VERSION "created by canmatrix"

NS_ :

BS_:

BU_: BDC_Body CHC DME1 EME FLA NiVi ZGW Kombi Kombi_Basis Diagnosetool_FA_CAN CDC_ZGW DME2 ELV Gliwa_T1_Host FA_CAN_Dummy

BO_ 841 RAW_DATA_TANK: 5 BDC_Body
 SG_ RWDT_SEN_FLLV_FUTA_L : 0|16@1+ (0.1,0) [0|120.7] "Ohm" Kombi,Kombi_Basis
 SG_ RWDT_SEN_FLLV_FUTA_R : 16|16@1+ (0.1,0) [0|120.7] "Ohm" Kombi,Kombi_Basis

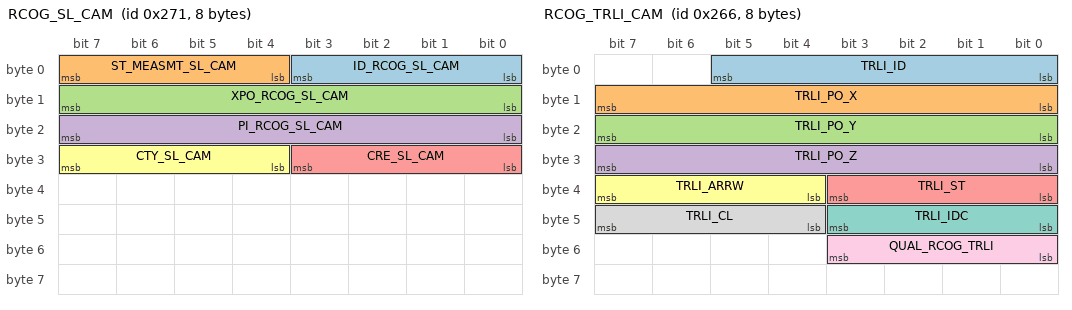
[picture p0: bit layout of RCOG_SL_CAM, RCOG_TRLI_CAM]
BO_ 625 RCOG_SL_CAM: 8 ZGW
 SG_ ID_RCOG_SL_CAM : 0|4@1+ (1,0) [0|12] "This unit fulfills the required AUTOSAR reference to a unit. No real unit is defined." DME2,DME1
 SG_ ST_MEASMT_SL_CAM : 4|4@1+ (1,0) [0|15] "" DME2,DME1
 SG_ XPO_RCOG_SL_CAM : 8|8@1+ (0.25,0) [0.00|15.75] "m" DME2,DME1
 SG_ PI_RCOG_SL_CAM : 16|8@1+ (0.01247,0) [0.00000|0.0391862268] "rad" DME2,DME1
 SG_ CRE_SL_CAM : 24|4@1+ (1,0) [0|10] "This unit fulfills the required AUTOSAR reference to a unit. No real unit is defined." DME2,DME1
 SG_ CTY_SL_CAM : 28|4@1+ (1,0) [0|15] "" DME2,DME1

BO_ 614 RCOG_TRLI_CAM: 8 ZGW
 SG_ TRLI_ID : 0|6@1+ (1,0) [0|60] "This unit fulfills the required AUTOSAR reference to a unit. No real unit is defined." DME2,DME1
 SG_ TRLI_PO_X : 8|8@1+ (0.5,0) [0|63] "m" DME2,DME1
 SG_ TRLI_PO_Y : 16|8@1+ (0.3,-37.8) [-49.14|-26.46] "m" DME2,DME1
 SG_ TRLI_PO_Z : 24|8@1+ (0.1,0) [0|2.52] "m" DME2,DME1
 SG_ TRLI_ST : 32|4@1+ (1,0) [0|15] "" DME2,DME1
 SG_ TRLI_ARRW : 36|4@1+ (1,0) [0|15] "" DME2,DME1
 SG_ TRLI_IDC : 40|4@1+ (1,0) [0|15] "" DME2,DME1
 SG_ TRLI_CL : 44|4@1+ (1,0) [0|15] "" DME2,DME1
 SG_ QUAL_RCOG_TRLI : 48|4@1+ (10,0) [0|1000] "%" DME2,DME1

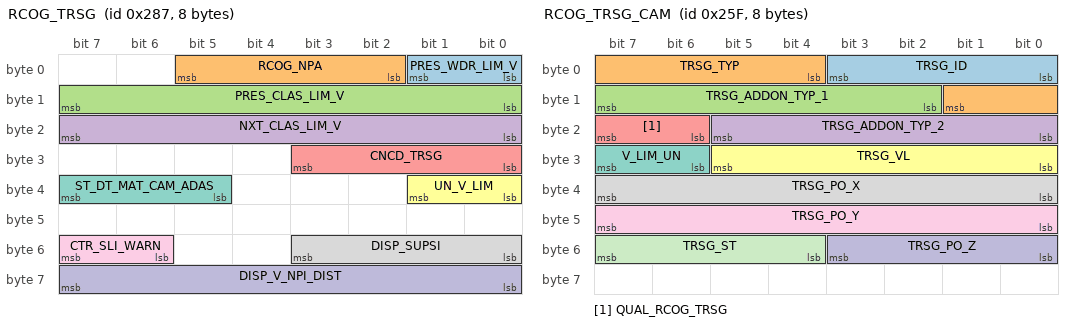
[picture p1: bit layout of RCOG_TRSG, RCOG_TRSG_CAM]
BO_ 647 RCOG_TRSG: 8 ZGW
 SG_ PRES_WDR_LIM_V : 0|2@1+ (1,0) [0|3] "" Kombi,Kombi_Basis,EME
 SG_ RCOG_NPA : 2|4@1+ (1,0) [0|15] "" Kombi,Kombi_Basis
 SG_ PRES_CLAS_LIM_V : 8|8@1+ (1,0) [0|255] "" Kombi,Kombi_Basis,EME
 SG_ NXT_CLAS_LIM_V : 16|8@1+ (1,0) [0|255] "" Kombi
 SG_ CNCD_TRSG : 24|4@1+ (1,0) [0|15] "" Kombi,Kombi_Basis,EME
 SG_ UN_V_LIM : 32|2@1+ (1,0) [0|3] "" Kombi,Kombi_Basis,EME
 SG_ ST_DT_MAT_CAM_ADAS : 37|3@1+ (1,0) [0|7] "" Kombi
 SG_ DISP_SUPSI : 48|4@1+ (1,0) [0|15] "" Kombi
 SG_ CTR_SLI_WARN : 54|2@1+ (1,0) [0|3] "" Kombi,Kombi_Basis
 SG_ DISP_V_NPI_DIST : 56|8@1+ (10,0) [0|25200] "This unit fulfills the required AUTOSAR reference to a unit. No real unit is defined." Kombi

BO_ 607 RCOG_TRSG_CAM: 8 ZGW
 SG_ TRSG_ID : 0|4@1+ (1,0) [0|12] "This unit fulfills the required AUTOSAR reference to a unit. No real unit is defined." DME2,DME1
 SG_ TRSG_TYP : 4|6@1+ (1,0) [0|63] "" DME2,DME1
 SG_ TRSG_ADDON_TYP_1 : 10|6@1+ (1,0) [0|63] "" DME2,DME1
 SG_ TRSG_ADDON_TYP_2 : 16|6@1+ (1,0) [0|63] "" DME2,DME1
 SG_ QUAL_RCOG_TRSG : 22|2@1+ (1,0) [0|3] "" DME2,DME1
 SG_ TRSG_VL : 24|6@1+ (5,0) [0|1500] "This unit fulfills the required AUTOSAR reference to a unit. No real unit is defined." DME2,DME1
 SG_ V_LIM_UN : 30|2@1+ (1,0) [0|3] "" DME2,DME1
 SG_ TRSG_PO_X : 32|8@1+ (0.5,0) [0|63] "m" DME2,DME1
 SG_ TRSG_PO_Y : 40|8@1+ (0.2,-25.2) [-30.24|-20.16] "m" DME2,DME1
 SG_ TRSG_PO_Z : 48|4@1+ (0.5,0) [0|3] "m" DME2,DME1
 SG_ TRSG_ST : 52|4@1+ (1,0) [0|15] "" DME2,DME1

BO_ 370 RCPT_RQ_KI: 5 ZGW
 SG_ RCPT_RQ_ACOU_KI : 32|4@1+ (1,0) [0|15] "" Kombi,Kombi_Basis

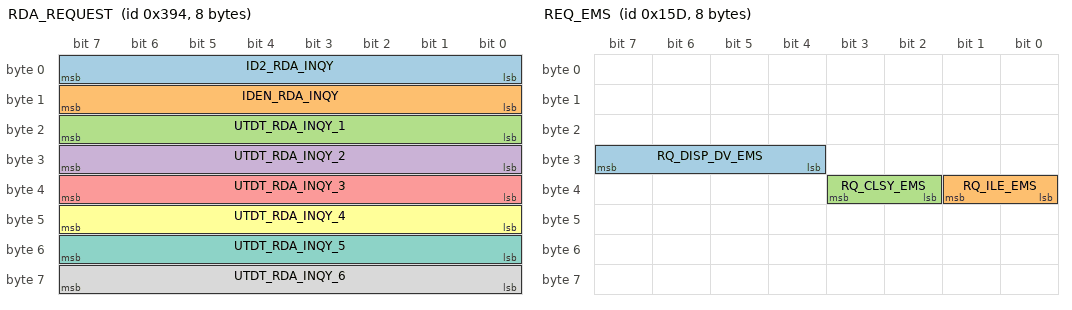
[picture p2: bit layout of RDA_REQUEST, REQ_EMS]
BO_ 916 RDA_REQUEST: 8 Kombi
 SG_ ID2_RDA_INQY : 0|8@1+ (1,0) [0|255] "" BDC_Body
 SG_ IDEN_RDA_INQY : 8|8@1+ (1,0) [0|254] "This unit fulfills the required AUTOSAR reference to a unit. No real unit is defined." BDC_Body
 SG_ UTDT_RDA_INQY_1 : 16|8@1+ (1,0) [0|255] "" BDC_Body
 SG_ UTDT_RDA_INQY_2 : 24|8@1+ (1,0) [0|255] "" BDC_Body
 SG_ UTDT_RDA_INQY_3 : 32|8@1+ (1,0) [0|255] "" BDC_Body
 SG_ UTDT_RDA_INQY_4 : 40|8@1+ (1,0) [0|255] "" BDC_Body
 SG_ UTDT_RDA_INQY_5 : 48|8@1+ (1,0) [0|255] "" BDC_Body
 SG_ UTDT_RDA_INQY_6 : 56|8@1+ (1,0) [0|255] "" BDC_Body

BO_ 808 RELATIVZEIT: 6 Kombi
 SG_ T_SEC_COU_REL : 0|32@1+ (1,0) [0|4294967294] "s" BDC_Body,NiVi,FLA,ELV,EME,DME2,DME1,Kombi_Basis,CHC,ZGW,Kombi
 SG_ T_DAY_COU_ABSL : 32|16@1+ (1,0) [0|65534] "This unit fulfills the required AUTOSAR reference to a unit. No real unit is defined." BDC_Body,EME,DME2,DME1,ZGW,NiVi

BO_ 349 REQ_EMS: 8 ZGW
 SG_ RQ_DISP_DV_EMS : 28|4@1+ (1,0) [0|15] "" Kombi,Kombi_Basis
 SG_ RQ_ILE_EMS : 32|2@1+ (1,0) [0|3] "" BDC_Body
 SG_ RQ_CLSY_EMS : 34|2@1+ (1,0) [0|3] "" BDC_Body

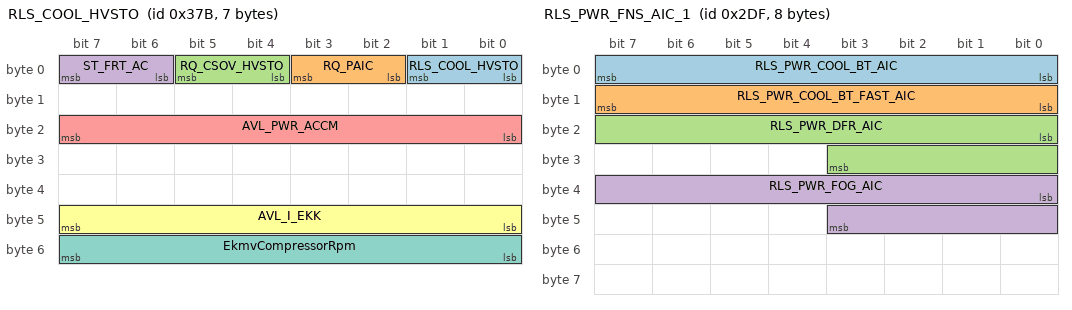
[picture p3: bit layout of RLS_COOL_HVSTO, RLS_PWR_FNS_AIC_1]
BO_ 891 RLS_COOL_HVSTO: 7 ZGW
 SG_ RLS_COOL_HVSTO : 0|2@1+ (1,0) [0|3] "" EME
 SG_ RQ_PAIC : 2|2@1+ (1,0) [0|3] "" DME2,EME,DME1
 SG_ RQ_CSOV_HVSTO : 4|2@1+ (1,0) [0|3] "" EME
 SG_ ST_FRT_AC : 6|2@1+ (1,0) [0|3] "" EME
 SG_ AVL_PWR_ACCM : 16|8@1+ (0.04,0) [0.00|0.4064] "kW" DME2,EME,DME1
 SG_ AVL_I_EKK : 40|8@1+ (0.2,0) [0|10.16] "A" CDC_ZGW,EME
 SG_ EkmvCompressorRpm : 48|8@1+ (0.5,0) [0|50] "%" EME

BO_ 735 RLS_PWR_FNS_AIC_1: 8 EME
 SG_ RLS_PWR_COOL_BT_AIC : 0|8@1+ (25,0) [0|157500] "W" ZGW
 SG_ RLS_PWR_COOL_BT_FAST_AIC : 8|8@1+ (25,0) [0|157500] "W" ZGW
 SG_ RLS_PWR_DFR_AIC : 16|12@1+ (25,0) [0|2557500] "W" ZGW
 SG_ RLS_PWR_FOG_AIC : 32|12@1+ (25,0) [0|2557500] "W" ZGW

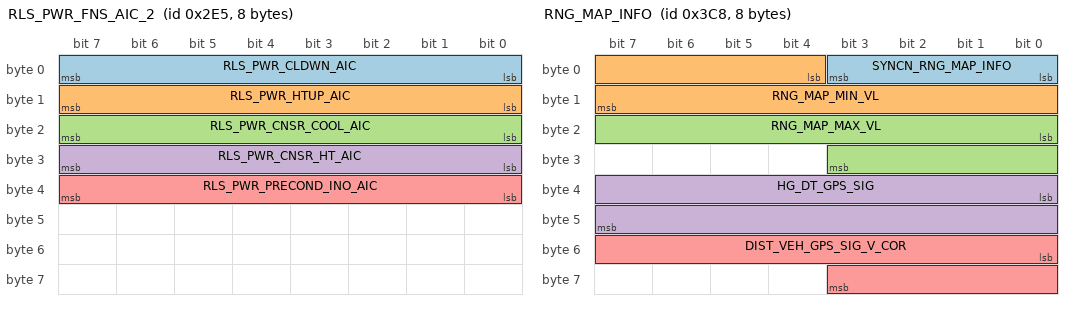
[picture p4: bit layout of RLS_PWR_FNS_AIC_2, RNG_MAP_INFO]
BO_ 741 RLS_PWR_FNS_AIC_2: 8 EME
 SG_ RLS_PWR_CLDWN_AIC : 0|8@1+ (25,0) [0|157500] "W" ZGW
 SG_ RLS_PWR_HTUP_AIC : 8|8@1+ (25,0) [0|157500] "W" ZGW
 SG_ RLS_PWR_CNSR_COOL_AIC : 16|8@1+ (25,0) [0|157500] "W" ZGW
 SG_ RLS_PWR_CNSR_HT_AIC : 24|8@1+ (25,0) [0|157500] "W" ZGW
 SG_ RLS_PWR_PRECOND_INO_AIC : 32|8@1+ (25,0) [0|157500] "W" ZGW

BO_ 968 RNG_MAP_INFO: 8 ZGW
 SG_ SYNCN_RNG_MAP_INFO : 0|4@1+ (1,0) [0|14] "This unit fulfills the required AUTOSAR reference to a unit. No real unit is defined." Kombi,Kombi_Basis
 SG_ RNG_MAP_MIN_VL : 4|12@1+ (1,0) [0|4094] "This unit fulfills the required AUTOSAR reference to a unit. No real unit is defined." Kombi,Kombi_Basis
 SG_ RNG_MAP_MAX_VL : 16|12@1+ (1,0) [0|4094] "This unit fulfills the required AUTOSAR reference to a unit. No real unit is defined." Kombi,Kombi_Basis
 SG_ HG_DT_GPS_SIG : 32|16@1+ (0.2,-1000) [-1200|1421.36] "m" Kombi,Kombi_Basis
 SG_ DIST_VEH_GPS_SIG_V_COR : 48|12@1+ (1,0) [0|4093] "m" Kombi,Kombi_Basis

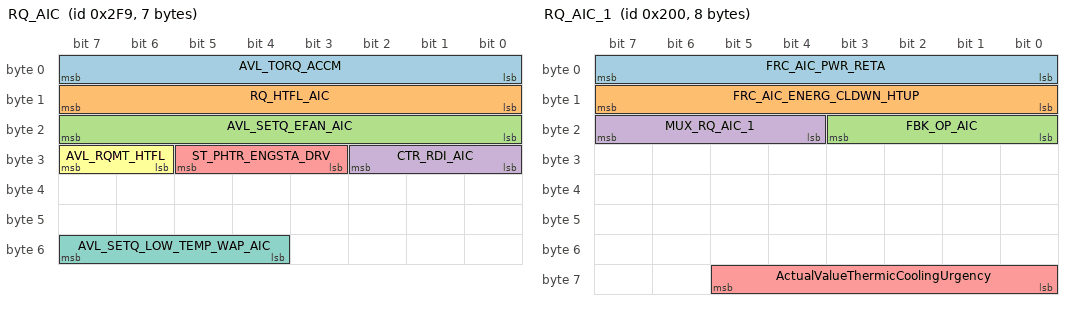
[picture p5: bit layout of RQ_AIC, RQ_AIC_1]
BO_ 761 RQ_AIC: 7 ZGW
 SG_ AVL_TORQ_ACCM : 0|8@1+ (0.5,0) [0|15] "Nm" DME2,DME1
 SG_ RQ_HTFL_AIC : 8|8@1+ (0.5,0) [0|50] "%" DME2,DME1
 SG_ AVL_SETQ_EFAN_AIC : 16|8@1+ (0.5,0) [0|50] "%" DME2,DME1
 SG_ CTR_RDI_AIC : 24|3@1+ (1,0) [0|7] "" DME2,DME1
 SG_ ST_PHTR_ENGSTA_DRV : 27|3@1+ (1,0) [0|7] "" DME2,DME1
 SG_ AVL_RQMT_HTFL : 30|2@1+ (1,0) [0|3] "" DME2,DME1
 SG_ AVL_SETQ_LOW_TEMP_WAP_AIC : 52|4@1+ (8.5,0) [0|867] "%" DME2,DME1

BO_ 512 RQ_AIC_1: 8 ZGW
 SG_ FRC_AIC_PWR_RETA : 0|8@1+ (0.05,0) [0.00|0.630] "kW" Kombi
 SG_ FRC_AIC_ENERG_CLDWN_HTUP : 8|8@1+ (0.05,0) [0.00|0.630] "kWh" Kombi
 SG_ FBK_OP_AIC : 16|4@1+ (1,0) [0|14] "This unit fulfills the required AUTOSAR reference to a unit. No real unit is defined." Kombi
 SG_ MUX_RQ_AIC_1 : 20|4@1+ (1,0) [0|15] "" Kombi
 SG_ ActualValueThermicCoolingUrgency : 56|6@1+ (2,0) [0|200] "%" EME

BO_ 665 RQ_AIC_HYB: 8 ZGW
 SG_ CTR_CSOV_EVA : 40|8@1+ (1,0) [0|100] "%" EME

BO_ 160 RQ_TORQ_CRSH_GRB_2: 8 DME1
 SG_ TAR_MOD_SHFT_DVCH : 12|4@1+ (1,0) [0|15] "" ZGW,Kombi

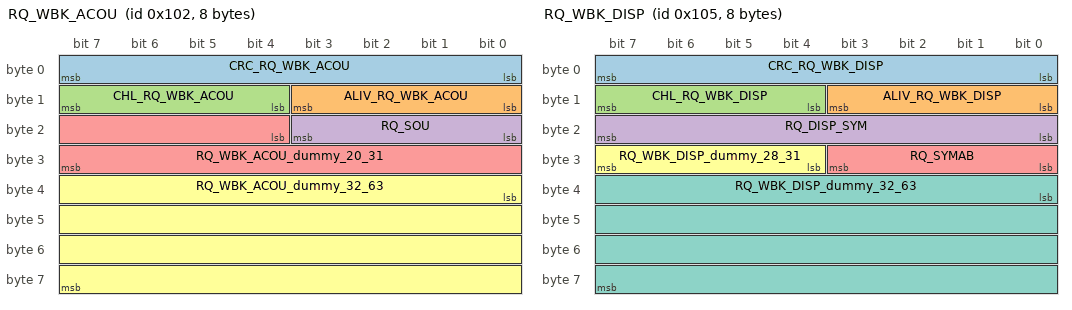
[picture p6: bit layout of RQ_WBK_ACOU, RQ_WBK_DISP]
BO_ 258 RQ_WBK_ACOU: 8 ZGW
 SG_ CRC_RQ_WBK_ACOU : 0|8@1+ (1,0) [0|255] "This unit fulfills the required AUTOSAR reference to a unit. No real unit is defined." Vector__XXX
 SG_ ALIV_RQ_WBK_ACOU : 8|4@1+ (1,0) [0|14] "This unit fulfills the required AUTOSAR reference to a unit. No real unit is defined." Vector__XXX
 SG_ CHL_RQ_WBK_ACOU : 12|4@1+ (1,0) [0|14] "This unit fulfills the required AUTOSAR reference to a unit. No real unit is defined." Vector__XXX
 SG_ RQ_SOU : 16|4@1+ (1,0) [0|15] "" Vector__XXX
 SG_ RQ_WBK_ACOU_dummy_20_31 : 20|12@1+ (1,0) [-2048|2047] "" Vector__XXX
 SG_ RQ_WBK_ACOU_dummy_32_63 : 32|32@1+ (1,0) [-2147483648|2147483647] "" Vector__XXX

BO_ 261 RQ_WBK_DISP: 8 ZGW
 SG_ CRC_RQ_WBK_DISP : 0|8@1+ (1,0) [0|255] "This unit fulfills the required AUTOSAR reference to a unit. No real unit is defined." Vector__XXX
 SG_ ALIV_RQ_WBK_DISP : 8|4@1+ (1,0) [0|14] "This unit fulfills the required AUTOSAR reference to a unit. No real unit is defined." Vector__XXX
 SG_ CHL_RQ_WBK_DISP : 12|4@1+ (1,0) [0|14] "This unit fulfills the required AUTOSAR reference to a unit. No real unit is defined." Vector__XXX
 SG_ RQ_DISP_SYM : 16|8@1+ (1,0) [0|255] "" Vector__XXX
 SG_ RQ_SYMAB : 24|4@1+ (1,0) [0|15] "" Vector__XXX
 SG_ RQ_WBK_DISP_dummy_28_31 : 28|4@1+ (1,0) [-8|7] "" Vector__XXX
 SG_ RQ_WBK_DISP_dummy_32_63 : 32|32@1+ (1,0) [-2147483648|2147483647] "" Vector__XXX

BO_ 199 RTM_DT: 8 EME
 SG_ Multiplexor M : 0|8@1+ (1,0) [-128|127] "" Vector__XXX

BO_ 1096 RequestKeyAction: 8 ZGW
 SG_ RequestKeyFunction : 0|8@1+ (1,0) [0|255] "" BDC_Body
 SG_ RequestKeyId : 8|24@1+ (1,0) [0|16777215] "" BDC_Body

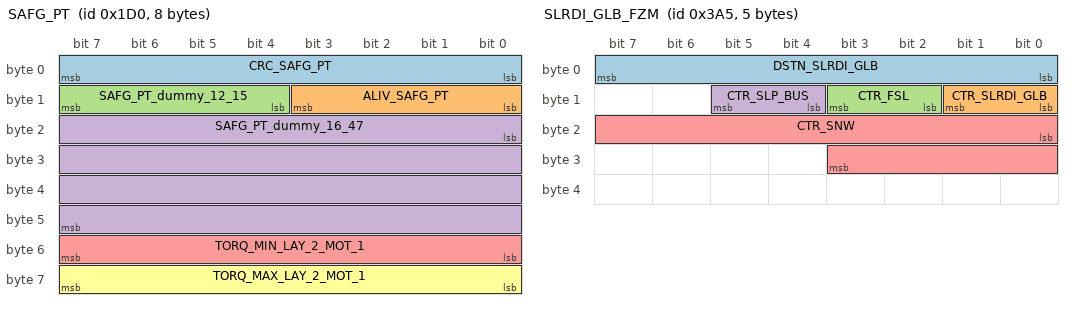
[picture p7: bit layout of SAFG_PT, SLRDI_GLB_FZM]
BO_ 464 SAFG_PT: 8 DME1
 SG_ CRC_SAFG_PT : 0|8@1+ (1,0) [0|255] "This unit fulfills the required AUTOSAR reference to a unit. No real unit is defined." Vector__XXX
 SG_ ALIV_SAFG_PT : 8|4@1+ (1,0) [0|14] "This unit fulfills the required AUTOSAR reference to a unit. No real unit is defined." Vector__XXX
 SG_ SAFG_PT_dummy_12_15 : 12|4@1+ (1,0) [-8|7] "" Vector__XXX
 SG_ SAFG_PT_dummy_16_47 : 16|32@1+ (1,0) [-2147483648|2147483647] "" Vector__XXX
 SG_ TORQ_MIN_LAY_2_MOT_1 : 48|8@1+ (2,-500) [-1500|-500] "Nm" Vector__XXX
 SG_ TORQ_MAX_LAY_2_MOT_1 : 56|8@1+ (2,0) [0|1000] "Nm" Vector__XXX

BO_ 482 SECU_FAHRGESTELLNUMMER: 8 ZGW
 SG_ STU_8_BYTE : 0|64@1+ (1,0) [0|18446744073709551615] "This unit fulfills the required AUTOSAR reference to a unit. No real unit is defined." Vector__XXX

BO_ 786 SERV_C_TELESERV: 2 Kombi
 SG_ TR_AUTOM_SER_CALL_TS : 0|2@1+ (1,0) [0|3] "" ZGW
 SG_ ST_CBS_TS : 2|2@1+ (1,0) [0|3] "" ZGW

BO_ 933 SLRDI_GLB_FZM: 5 ZGW
 SG_ DSTN_SLRDI_GLB : 0|8@1+ (1,0) [0|255] "" DME2,Diagnosetool_FA_CAN,EME,DME1
 SG_ CTR_SLRDI_GLB : 8|2@1+ (1,0) [0|3] "" DME2,Diagnosetool_FA_CAN,EME,DME1
 SG_ CTR_FSL : 10|2@1+ (1,0) [0|3] "" DME2,Diagnosetool_FA_CAN,EME,DME1
 SG_ CTR_SLP_BUS : 12|2@1+ (1,0) [0|3] "" DME2,Diagnosetool_FA_CAN,EME,DME1
 SG_ CTR_SNW : 16|12@1+ (1,0) [0|4095] "" DME2,Diagnosetool_FA_CAN,EME,DME1

BO_ 843 STATE_SBIL_DR: 8 ZGW
 SG_ ALIV_COU_SM_DR : 0|4@1+ (1,0) [0|14] "This unit fulfills the required AUTOSAR reference to a unit. No real unit is defined." Kombi,Kombi_Basis
 SG_ ST_SBIL_DR : 4|2@1+ (1,0) [0|3] "" Kombi,Kombi_Basis

BO_ 845 STATE_SBIL_PS: 8 ZGW
 SG_ ALIV_COU_SM_PS : 0|4@1+ (1,0) [0|14] "This unit fulfills the required AUTOSAR reference to a unit. No real unit is defined." Kombi,Kombi_Basis
 SG_ ST_SBIL_PS : 4|2@1+ (1,0) [0|3] "" Kombi,Kombi_Basis

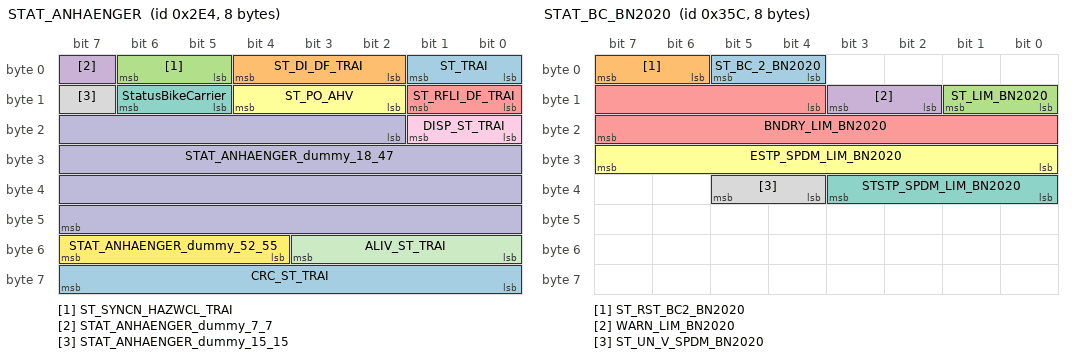
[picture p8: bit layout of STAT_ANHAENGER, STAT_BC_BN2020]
BO_ 740 STAT_ANHAENGER: 8 ZGW
 SG_ ST_TRAI : 0|2@1+ (1,0) [0|3] "" Vector__XXX
 SG_ ST_DI_DF_TRAI : 2|3@1+ (1,0) [0|7] "" Vector__XXX
 SG_ ST_SYNCN_HAZWCL_TRAI : 5|2@1+ (1,0) [0|3] "" Vector__XXX
 SG_ STAT_ANHAENGER_dummy_7_7 : 7|1@1+ (1,0) [-1|0] "" Vector__XXX
 SG_ ST_RFLI_DF_TRAI : 8|2@1+ (1,0) [0|3] "" Vector__XXX
 SG_ ST_PO_AHV : 10|3@1+ (1,0) [0|7] "" Vector__XXX
 SG_ StatusBikeCarrier : 13|2@1+ (1,0) [0|3] "" Vector__XXX
 SG_ STAT_ANHAENGER_dummy_15_15 : 15|1@1+ (1,0) [-1|0] "" Vector__XXX
 SG_ DISP_ST_TRAI : 16|2@1+ (1,0) [0|3] "" Vector__XXX
 SG_ STAT_ANHAENGER_dummy_18_47 : 18|30@1+ (1,0) [-536870912|536870911] "" Vector__XXX
 SG_ ALIV_ST_TRAI : 48|4@1+ (1,0) [0|14] "This unit fulfills the required AUTOSAR reference to a unit. No real unit is defined." Vector__XXX
 SG_ STAT_ANHAENGER_dummy_52_55 : 52|4@1+ (1,0) [-8|7] "" Vector__XXX
 SG_ CRC_ST_TRAI : 56|8@1+ (1,0) [0|255] "This unit fulfills the required AUTOSAR reference to a unit. No real unit is defined." Vector__XXX

BO_ 860 STAT_BC_BN2020: 8 Kombi
 SG_ ST_BC_2_BN2020 : 4|2@1+ (1,0) [0|3] "" ZGW
 SG_ ST_RST_BC2_BN2020 : 6|2@1+ (1,0) [0|3] "" ZGW
 SG_ ST_LIM_BN2020 : 8|2@1+ (1,0) [0|3] "" ZGW
 SG_ WARN_LIM_BN2020 : 10|2@1+ (1,0) [0|3] "" ZGW
 SG_ BNDRY_LIM_BN2020 : 12|12@1+ (1,0) [0|4094] "This unit fulfills the required AUTOSAR reference to a unit. No real unit is defined." ZGW
 SG_ ESTP_SPDM_LIM_BN2020 : 24|8@1+ (1,80) [160|414] "This unit fulfills the required AUTOSAR reference to a unit. No real unit is defined." ZGW
 SG_ STSTP_SPDM_LIM_BN2020 : 32|4@1+ (1,0) [0|14] "This unit fulfills the required AUTOSAR reference to a unit. No real unit is defined." ZGW
 SG_ ST_UN_V_SPDM_BN2020 : 36|2@1+ (1,0) [0|3] "" ZGW

BO_ 554 STAT_BFS: 8 ZGW
 SG_ ST_SHTR_PS : 4|4@1+ (1,0) [0|15] "" Kombi,Kombi_Basis

BO_ 558 STAT_BFSH: 8 ZGW
 SG_ ST_SHTR_PSR : 4|4@1+ (1,0) [0|15] "" Kombi,Kombi_Basis

BO_ 847 STAT_CT_HABR: 2 BDC_Body
 SG_ ST_CT_HABR : 0|2@1+ (1,0) [0|3] "" ZGW,Kombi,Kombi_Basis

BO_ 722 STAT_DRUCK_KAELTE: 5 ZGW
 SG_ DT_PSEN_RFCI : 0|8@1+ (0.5,0) [0|63] "bar" DME2,DME1

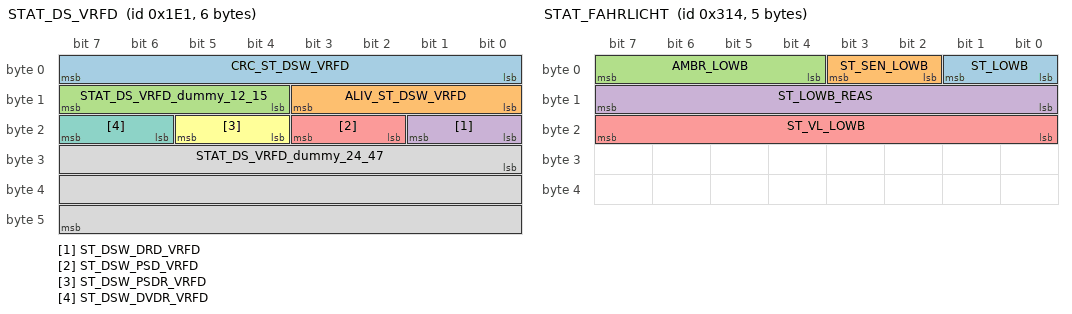
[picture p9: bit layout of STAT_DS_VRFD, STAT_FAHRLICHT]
BO_ 481 STAT_DS_VRFD: 6 BDC_Body
 SG_ CRC_ST_DSW_VRFD : 0|8@1+ (1,0) [0|255] "This unit fulfills the required AUTOSAR reference to a unit. No real unit is defined." Vector__XXX
 SG_ ALIV_ST_DSW_VRFD : 8|4@1+ (1,0) [0|14] "This unit fulfills the required AUTOSAR reference to a unit. No real unit is defined." Vector__XXX
 SG_ STAT_DS_VRFD_dummy_12_15 : 12|4@1+ (1,0) [-8|7] "" Vector__XXX
 SG_ ST_DSW_DRD_VRFD : 16|2@1+ (1,0) [0|3] "" Vector__XXX
 SG_ ST_DSW_PSD_VRFD : 18|2@1+ (1,0) [0|3] "" Vector__XXX
 SG_ ST_DSW_PSDR_VRFD : 20|2@1+ (1,0) [0|3] "" Vector__XXX
 SG_ ST_DSW_DVDR_VRFD : 22|2@1+ (1,0) [0|3] "" Vector__XXX
 SG_ STAT_DS_VRFD_dummy_24_47 : 24|24@1+ (1,0) [-8388608|8388607] "" Vector__XXX

BO_ 779 STAT_ENG_STA_AUTO: 8 DME1
 SG_ CRC_ST_ENG_STA_AUTO : 0|8@1+ (1,0) [0|255] "This unit fulfills the required AUTOSAR reference to a unit. No real unit is defined." Vector__XXX
 SG_ ALIV_ST_ENG_STA_AUTO : 8|4@1+ (1,0) [0|15] "" Vector__XXX
 SG_ RQ_MSA_ENG_STA_1 : 12|2@1+ (1,0) [0|3] "" Vector__XXX
 SG_ RQ_MSA_ENG_STA_2 : 14|2@1+ (1,0) [0|3] "" Vector__XXX
 SG_ ST_AVL_PENG_CENG_ENGMG : 16|2@1+ (1,0) [0|3] "" Vector__XXX
 SG_ ST_FN_MSA : 18|2@1+ (1,0) [0|3] "" Vector__XXX
 SG_ SPEC_TYP_ENGSTA_PRM : 20|4@1+ (1,0) [0|15] "" Vector__XXX
 SG_ ST_SHFT_MSA_ENGSTP : 24|3@1+ (1,0) [0|7] "" Vector__XXX
 SG_ PSBTY_MSA_ENG_STOP_STA : 27|3@1+ (1,0) [0|7] "" Vector__XXX
 SG_ ST_TAR_CENG : 30|2@1+ (1,0) [0|3] "" Vector__XXX
 SG_ SPEC_TYP_ENGSTA : 32|4@1+ (1,0) [0|15] "" Vector__XXX
 SG_ ST_RPM_CLCTR_MOT : 36|2@1+ (1,0) [0|3] "" Vector__XXX
 SG_ ST_TAR_PENG_CENG : 38|2@1+ (1,0) [0|3] "" Vector__XXX
 SG_ ST_AVAI_SAIL_DME : 40|8@1+ (1,0) [0|255] "" Vector__XXX
 SG_ RQ_SLIP_K0 : 48|8@1+ (10,-1000) [-11000|9000] "1/min" Vector__XXX
 SG_ VARI_TYP_ENGSTA : 56|2@1+ (1,0) [0|3] "" Vector__XXX
 SG_ STAT_ENG_STA_AUTO_dummy_58_59 : 58|2@1+ (1,0) [-2|1] "" Vector__XXX
 SG_ ST_CON_MSA : 60|4@1+ (1,0) [0|15] "" Vector__XXX

BO_ 788 STAT_FAHRLICHT: 5 BDC_Body
 SG_ ST_LOWB : 0|2@1+ (1,0) [0|3] "" NiVi
 SG_ ST_SEN_LOWB : 2|2@1+ (1,0) [0|3] "" Kombi,Kombi_Basis,NiVi
 SG_ AMBR_LOWB : 4|4@1+ (1,0) [1|8] "This unit fulfills the required AUTOSAR reference to a unit. No real unit is defined." CDC_ZGW,NiVi
 SG_ ST_LOWB_REAS : 8|8@1+ (1,0) [0|255] "" CDC_ZGW,Kombi,Kombi_Basis,NiVi
 SG_ ST_VL_LOWB : 16|8@1+ (1,0) [0|254] "This unit fulfills the required AUTOSAR reference to a unit. No real unit is defined." Kombi,Kombi_Basis,NiVi

BO_ 562 STAT_FAS: 8 ZGW
 SG_ ST_SHTR_DR : 4|4@1+ (1,0) [0|15] "" Kombi,Kombi_Basis

BO_ 566 STAT_FASH: 8 ZGW
 SG_ ST_SHTR_DRR : 4|4@1+ (1,0) [0|15] "" Kombi,Kombi_Basis

BO_ 570 STAT_FUNKSCHLUESSEL: 8 BDC_Body
 SG_ NO_KEY_PRSL_IMME : 0|4@1+ (1,0) [0|15] "" ZGW,Kombi,Kombi_Basis,NiVi
 SG_ NO_KEY_PRSL : 4|4@1+ (1,0) [0|15] "" ZGW,Kombi,Kombi_Basis,NiVi
 SG_ ST_KEY_RMC : 8|2@1+ (1,0) [0|3] "" ZGW
 SG_ ST_KEY_BT : 10|2@1+ (1,0) [0|3] "" ZGW
 SG_ CTR_ITLI_PLIP : 12|2@1+ (1,0) [0|3] "" ZGW,Kombi,Kombi_Basis,NiVi
 SG_ OP_KEY_LDPO_FLDT : 14|2@1+ (1,0) [0|3] "" ZGW
 SG_ OP_KEY_BUT_ULOK : 16|2@1+ (1,0) [0|3] "" NiVi,EME,Kombi_Basis,ZGW,Kombi
 SG_ OP_KEY_BUT_LOK : 18|2@1+ (1,0) [0|3] "" ZGW,Kombi,Kombi_Basis,NiVi
 SG_ OP_KEY_BUT_BTL : 20|2@1+ (1,0) [0|3] "" ZGW,Kombi,Kombi_Basis,NiVi
 SG_ OP_KEY_BUT_SPFN : 22|2@1+ (1,0) [0|3] "" ZGW,Kombi,Kombi_Basis,NiVi
 SG_ NO_KEY_TR_PRSL : 24|4@1+ (1,0) [0|15] "" ZGW,Kombi,Kombi_Basis,NiVi
 SG_ CTR_TR_PRSL : 28|2@1+ (1,0) [0|3] "" ZGW,Kombi,Kombi_Basis,NiVi
 SG_ ST_LOK_RQ_FFB_LFSR : 30|2@1+ (1,0) [0|3] "" ZGW
 SG_ CTR_LP_FMH : 32|2@1+ (1,0) [0|3] "" ZGW
 SG_ CTR_UGDO : 34|2@1+ (1,0) [0|3] "" ZGW
 SG_ ST_KEY_BT_DISP_MMI : 36|4@1+ (1,0) [0|15] "" ZGW
 SG_ ST_PCOL : 40|2@1+ (1,0) [0|3] "" ZGW
 SG_ CTR_PAN_MOD : 42|2@1+ (1,0) [0|3] "" ZGW
 SG_ AVL_MOD_SSHK : 44|4@1+ (1,0) [0|15] "" ZGW

BO_ 944 STAT_GANG_RUECKWAERTS: 2 BDC_Body
 SG_ ST_GR_BAC : 0|2@1+ (1,0) [0|3] "" FLA,DME2,DME1,Kombi_Basis,ZGW,Kombi

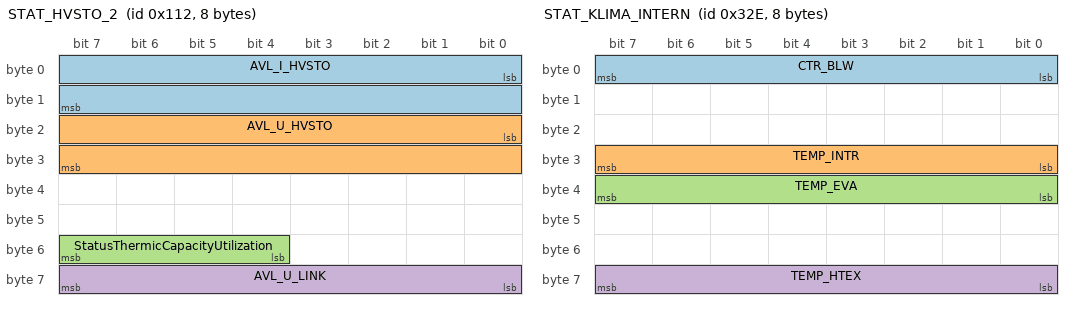
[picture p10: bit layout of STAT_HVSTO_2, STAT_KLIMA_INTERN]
BO_ 274 STAT_HVSTO_2: 8 EME
 SG_ AVL_I_HVSTO : 0|16@1+ (0.1,-819.2) [-901.12|-737.3] "A" CDC_ZGW,ZGW
 SG_ AVL_U_HVSTO : 16|16@1+ (0.1,0) [0|81.9] "V" CDC_ZGW,ZGW
 SG_ StatusThermicCapacityUtilization : 52|4@1+ (1,0) [0|15] "" ZGW
 SG_ AVL_U_LINK : 56|8@1+ (4,0) [0|3280] "V" ZGW

BO_ 814 STAT_KLIMA_INTERN: 8 ZGW
 SG_ CTR_BLW : 0|8@1+ (0.5,0) [0|50] "%" DME2,EME,DME1
 SG_ TEMP_INTR : 24|8@1+ (0.1667,0) [1.6670|6.6680] "°C" BDC_Body
 SG_ TEMP_EVA : 32|8@1+ (0.2,-10) [-12|-2] "°C" BDC_Body,DME1
 SG_ TEMP_HTEX : 56|8@1+ (0.5,5) [7.5|67.5] "°C" BDC_Body

BO_ 742 STAT_KLIMA_LUFT_FA: 8 ZGW
 SG_ TEMP_TAR_DR_IHKA : 56|8@1+ (0.5,0) [8|16] "°C" DME2,DME1

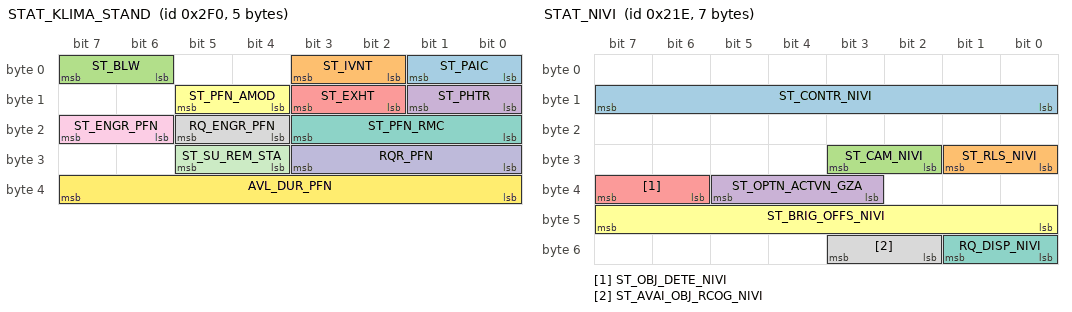
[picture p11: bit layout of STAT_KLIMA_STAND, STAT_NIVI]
BO_ 752 STAT_KLIMA_STAND: 5 ZGW
 SG_ ST_PAIC : 0|2@1+ (1,0) [0|3] "" BDC_Body,DME2,DME1,Kombi_Basis,Kombi
 SG_ ST_IVNT : 2|2@1+ (1,0) [0|3] "" BDC_Body,DME2,DME1,Kombi_Basis,Kombi
 SG_ ST_BLW : 6|2@1+ (1,0) [0|3] "" BDC_Body
 SG_ ST_PHTR : 8|2@1+ (1,0) [0|3] "" BDC_Body,DME2,DME1,Kombi_Basis,Kombi
 SG_ ST_EXHT : 10|2@1+ (1,0) [0|3] "" BDC_Body
 SG_ ST_PFN_AMOD : 12|2@1+ (1,0) [0|3] "" BDC_Body
 SG_ ST_PFN_RMC : 16|4@1+ (1,0) [0|15] "" BDC_Body
 SG_ RQ_ENGR_PFN : 20|2@1+ (1,0) [0|3] "" BDC_Body,DME2,DME1
 SG_ ST_ENGR_PFN : 22|2@1+ (1,0) [0|3] "" Kombi,BDC_Body,Kombi_Basis
 SG_ RQR_PFN : 24|4@1+ (1,0) [0|15] "" BDC_Body
 SG_ ST_SU_REM_STA : 28|2@1+ (1,0) [0|3] "" BDC_Body
 SG_ AVL_DUR_PFN : 32|8@1+ (1,0) [0|60] "min" BDC_Body

BO_ 542 STAT_NIVI: 7 NiVi
 SG_ ST_CONTR_NIVI : 8|8@1+ (1,0) [0|100] "%" ZGW
 SG_ ST_RLS_NIVI : 24|2@1+ (1,0) [0|3] "" ZGW
 SG_ ST_CAM_NIVI : 26|2@1+ (1,0) [0|3] "" ZGW
 SG_ ST_OPTN_ACTVN_GZA : 35|3@1+ (1,0) [0|7] "" BDC_Body
 SG_ ST_OBJ_DETE_NIVI : 38|2@1+ (1,0) [0|3] "" ZGW,BDC_Body
 SG_ ST_BRIG_OFFS_NIVI : 40|8@1+ (1,0) [0|100] "%" ZGW
 SG_ RQ_DISP_NIVI : 48|2@1+ (1,0) [0|3] "" ZGW
 SG_ ST_AVAI_OBJ_RCOG_NIVI : 50|2@1+ (1,0) [0|3] "" BDC_Body

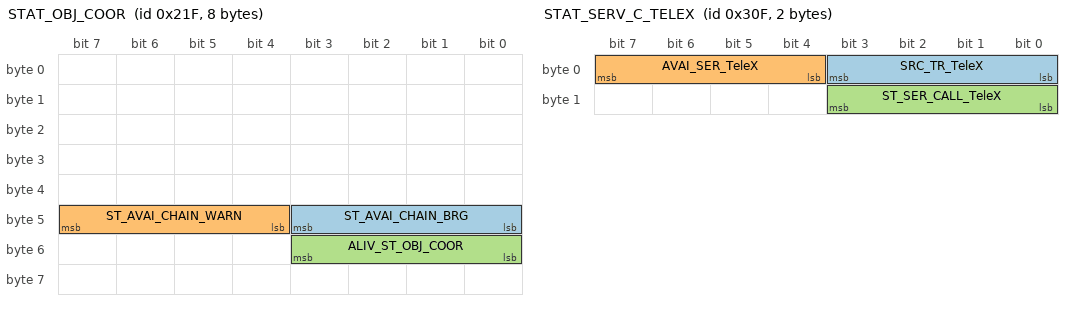
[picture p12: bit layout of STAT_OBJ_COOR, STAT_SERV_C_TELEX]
BO_ 543 STAT_OBJ_COOR: 8 ZGW
 SG_ ST_AVAI_CHAIN_BRG : 40|4@1+ (1,0) [0|15] "" NiVi
 SG_ ST_AVAI_CHAIN_WARN : 44|4@1+ (1,0) [0|15] "" NiVi
 SG_ ALIV_ST_OBJ_COOR : 48|4@1+ (1,0) [0|14] "This unit fulfills the required AUTOSAR reference to a unit. No real unit is defined." NiVi

BO_ 783 STAT_SERV_C_TELEX: 2 ZGW
 SG_ SRC_TR_TeleX : 0|4@1+ (1,0) [0|15] "" Kombi,Kombi_Basis
 SG_ AVAI_SER_TeleX : 4|4@1+ (1,0) [0|15] "" Kombi,Kombi_Basis
 SG_ ST_SER_CALL_TeleX : 8|4@1+ (1,0) [0|15] "" Kombi,Kombi_Basis

BO_ 594 STAT_WISCHER: 2 BDC_Body
 SG_ PO_WIBL : 0|4@1+ (1,0) [0|15] "" ZGW,NiVi

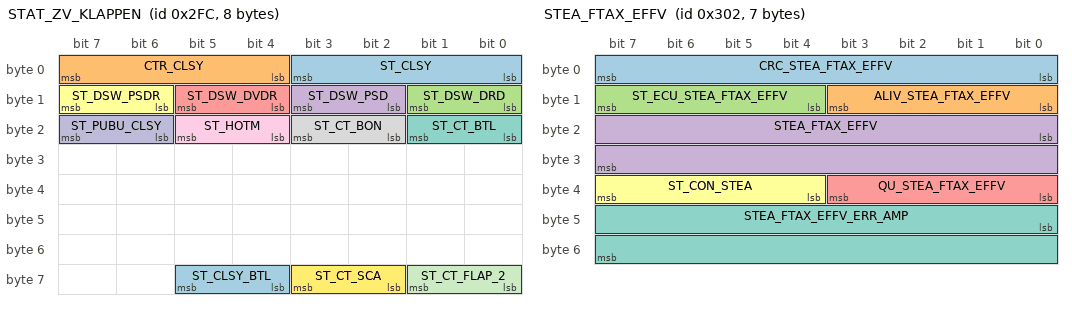
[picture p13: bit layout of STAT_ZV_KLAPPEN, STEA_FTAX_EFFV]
BO_ 764 STAT_ZV_KLAPPEN: 8 BDC_Body
 SG_ ST_CLSY : 0|4@1+ (1,0) [0|15] "" ELV,EME,DME1,Kombi_Basis,CHC,ZGW,Kombi
 SG_ CTR_CLSY : 4|4@1+ (1,0) [0|15] "" ZGW,Kombi,Kombi_Basis
 SG_ ST_DSW_DRD : 8|2@1+ (1,0) [0|3] "" ELV,DME2,DME1,Kombi_Basis,CHC,ZGW,Kombi
 SG_ ST_DSW_PSD : 10|2@1+ (1,0) [0|3] "" ZGW,Kombi,Kombi_Basis,CHC
 SG_ ST_DSW_DVDR : 12|2@1+ (1,0) [0|3] "" ZGW,Kombi,Kombi_Basis,CHC
 SG_ ST_DSW_PSDR : 14|2@1+ (1,0) [0|3] "" ZGW,Kombi,Kombi_Basis,CHC
 SG_ ST_CT_BTL : 16|2@1+ (1,0) [0|3] "" EME,DME2,DME1,Kombi_Basis,CHC,ZGW,Kombi
 SG_ ST_CT_BON : 18|2@1+ (1,0) [0|3] "" EME,DME2,DME1,Kombi_Basis,ZGW,Kombi
 SG_ ST_HOTM : 20|2@1+ (1,0) [0|3] "" ZGW
 SG_ ST_PUBU_CLSY : 22|2@1+ (1,0) [0|3] "" ZGW
 SG_ ST_CT_FLAP_2 : 56|2@1+ (1,0) [0|3] "" ZGW,Kombi,Kombi_Basis
 SG_ ST_CT_SCA : 58|2@1+ (1,0) [0|3] "" ZGW
 SG_ ST_CLSY_BTL : 60|2@1+ (1,0) [0|3] "" ZGW

BO_ 719 STAT_ZWP: 2 BDC_Body
 SG_ ST_AUWP : 0|3@1+ (1,0) [0|7] "" ZGW

BO_ 770 STEA_FTAX_EFFV: 7 ZGW
 SG_ CRC_STEA_FTAX_EFFV : 0|8@1+ (1,0) [0|255] "This unit fulfills the required AUTOSAR reference to a unit. No real unit is defined." Vector__XXX
 SG_ ALIV_STEA_FTAX_EFFV : 8|4@1+ (1,0) [0|14] "This unit fulfills the required AUTOSAR reference to a unit. No real unit is defined." Vector__XXX
 SG_ ST_ECU_STEA_FTAX_EFFV : 12|4@1+ (1,0) [0|15] "" Vector__XXX
 SG_ STEA_FTAX_EFFV : 16|16@1+ (0.00274658203125,-89.997253418125) [-90.24443825722507476806640625|-89.75006857902578353881835938] "°" Vector__XXX
 SG_ QU_STEA_FTAX_EFFV : 32|4@1+ (1,0) [0|15] "" Vector__XXX
 SG_ ST_CON_STEA : 36|4@1+ (1,0) [0|15] "" Vector__XXX
 SG_ STEA_FTAX_EFFV_ERR_AMP : 40|16@1+ (0.00274658203125,0) [0E-014|0.24719238281250] "°" Vector__XXX

BO_ 756 ST_ACTVN_HSFZ: 2 ZGW
 SG_ ST_CONN_HSFZ : 0|8@1+ (1,0) [0|255] "" Kombi,Kombi_Basis
 SG_ ST_ACTVN_WR_HSFZ : 8|8@1+ (1,0) [0|255] "" Kombi,Kombi_Basis

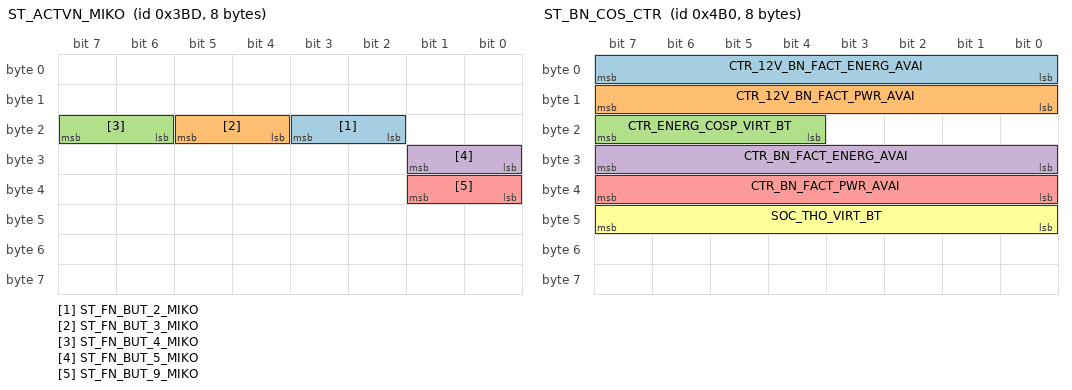
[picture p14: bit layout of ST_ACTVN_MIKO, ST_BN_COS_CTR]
BO_ 957 ST_ACTVN_MIKO: 8 BDC_Body
 SG_ ST_FN_BUT_2_MIKO : 18|2@1+ (1,0) [0|3] "" ZGW,DME2,DME1
 SG_ ST_FN_BUT_3_MIKO : 20|2@1+ (1,0) [0|3] "" ZGW,DME2,DME1
 SG_ ST_FN_BUT_4_MIKO : 22|2@1+ (1,0) [0|3] "" ZGW,DME2,DME1
 SG_ ST_FN_BUT_5_MIKO : 24|2@1+ (1,0) [0|3] "" ZGW
 SG_ ST_FN_BUT_9_MIKO : 32|2@1+ (1,0) [0|3] "" DME2,DME1

BO_ 663 ST_BLT_CT_SOCCU: 7 ZGW
 SG_ CRC_ST_BLT_CT_SOCCU : 0|8@1+ (1,0) [0|255] "This unit fulfills the required AUTOSAR reference to a unit. No real unit is defined." Vector__XXX
 SG_ ALIV_COU_ST_BLT_CT_SOCCU : 8|4@1+ (1,0) [0|14] "This unit fulfills the required AUTOSAR reference to a unit. No real unit is defined." Vector__XXX
 SG_ ST_ERR_SEAT_MT_DR : 12|3@1+ (1,0) [0|7] "" Vector__XXX
 SG_ ST_BLT_CT_SOCCU_dummy_15_15 : 15|1@1+ (1,0) [-1|0] "" Vector__XXX
 SG_ ST_BLTB_SW_DR : 16|2@1+ (1,0) [0|3] "" Vector__XXX
 SG_ ST_SEAT_OCCU_DR : 18|3@1+ (1,0) [0|7] "" Vector__XXX
 SG_ ST_SEAT_OCCU_3_LH_TIR_RS : 21|3@1+ (1,0) [0|7] "" Vector__XXX
 SG_ ST_BLTB_SW_PS : 24|2@1+ (1,0) [0|3] "" Vector__XXX
 SG_ ST_SEAT_OCCU_PS : 26|3@1+ (1,0) [0|7] "" Vector__XXX
 SG_ ST_SEAT_OCCU_3_MID_TIR_RS : 29|3@1+ (1,0) [0|7] "" Vector__XXX
 SG_ ST_BLTB_SW_RLH : 32|2@1+ (1,0) [0|3] "" Vector__XXX
 SG_ ST_SEAT_OCCU_RLH : 34|3@1+ (1,0) [0|7] "" Vector__XXX
 SG_ ST_SEAT_OCCU_3_RH_TIR_RS : 37|3@1+ (1,0) [0|7] "" Vector__XXX
 SG_ ST_BLTB_SW_RRH : 40|2@1+ (1,0) [0|3] "" Vector__XXX
 SG_ ST_SEAT_OCCU_RRH : 42|3@1+ (1,0) [0|7] "" Vector__XXX
 SG_ ST_SEAT_OCCU_RM : 45|3@1+ (1,0) [0|7] "" Vector__XXX
 SG_ ST_BLTB_SW_RM : 48|2@1+ (1,0) [0|3] "" Vector__XXX
 SG_ ST_BLTB_SW_3_LH_TIR_RS : 50|2@1+ (1,0) [0|3] "" Vector__XXX
 SG_ ST_BLTB_SW_3_RH_TIR_RS : 52|2@1+ (1,0) [0|3] "" Vector__XXX
 SG_ ST_BLTB_SW_3_MID_TIR_RS : 54|2@1+ (1,0) [0|3] "" Vector__XXX

BO_ 1200 ST_BN_COS_CTR: 8 DME1
 SG_ CTR_12V_BN_FACT_ENERG_AVAI : 0|8@1+ (0.5,0) [0|50] "%" ZGW,BDC_Body
 SG_ CTR_12V_BN_FACT_PWR_AVAI : 8|8@1+ (0.5,0) [0|50] "%" ZGW,BDC_Body
 SG_ CTR_ENERG_COSP_VIRT_BT : 20|4@1+ (1,0) [0|15] "" ZGW,BDC_Body
 SG_ CTR_BN_FACT_ENERG_AVAI : 24|8@1+ (0.5,0) [0|50] "%" Vector__XXX
 SG_ CTR_BN_FACT_PWR_AVAI : 32|8@1+ (0.5,0) [0|50] "%" Vector__XXX
 SG_ SOC_THO_VIRT_BT : 40|8@1+ (1,0) [0|100] "%" BDC_Body

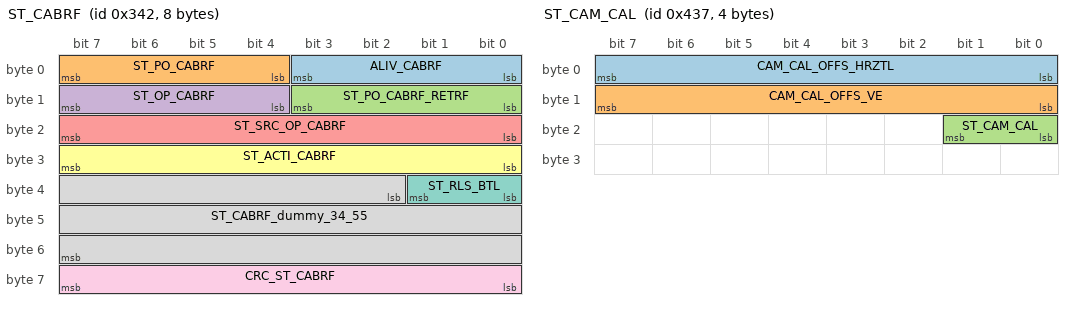
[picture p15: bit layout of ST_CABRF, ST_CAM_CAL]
BO_ 834 ST_CABRF: 8 ZGW
 SG_ ALIV_CABRF : 0|4@1+ (1,0) [0|14] "This unit fulfills the required AUTOSAR reference to a unit. No real unit is defined." Vector__XXX
 SG_ ST_PO_CABRF : 4|4@1+ (1,0) [0|15] "" Vector__XXX
 SG_ ST_PO_CABRF_RETRF : 8|4@1+ (1,0) [0|15] "" Vector__XXX
 SG_ ST_OP_CABRF : 12|4@1+ (1,0) [0|15] "" Vector__XXX
 SG_ ST_SRC_OP_CABRF : 16|8@1+ (1,0) [0|255] "" Vector__XXX
 SG_ ST_ACTI_CABRF : 24|8@1+ (1,0) [0|255] "" Vector__XXX
 SG_ ST_RLS_BTL : 32|2@1+ (1,0) [0|3] "" Vector__XXX
 SG_ ST_CABRF_dummy_34_55 : 34|22@1+ (1,0) [-2097152|2097151] "" Vector__XXX
 SG_ CRC_ST_CABRF : 56|8@1+ (1,0) [0|255] "This unit fulfills the required AUTOSAR reference to a unit. No real unit is defined." Vector__XXX

BO_ 1079 ST_CAM_CAL: 4 FLA
 SG_ CAM_CAL_OFFS_HRZTL : 0|8@1+ (0.05,-5) [-5.25|-4.75] "°" BDC_Body
 SG_ CAM_CAL_OFFS_VE : 8|8@1+ (0.05,-5) [-5.25|-4.75] "°" BDC_Body
 SG_ ST_CAM_CAL : 16|2@1+ (1,0) [0|3] "" BDC_Body

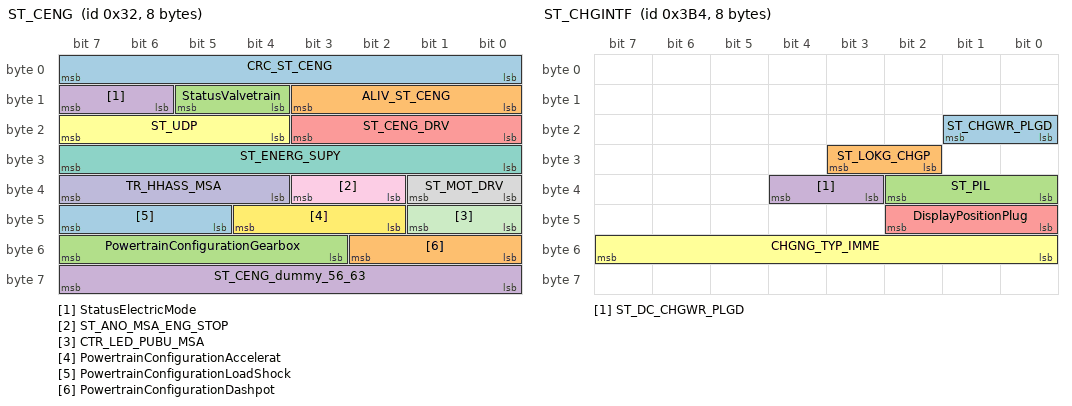
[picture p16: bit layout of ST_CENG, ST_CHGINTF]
BO_ 50 ST_CENG: 8 DME1
 SG_ CRC_ST_CENG : 0|8@1+ (1,0) [0|255] "This unit fulfills the required AUTOSAR reference to a unit. No real unit is defined." Vector__XXX
 SG_ ALIV_ST_CENG : 8|4@1+ (1,0) [0|14] "This unit fulfills the required AUTOSAR reference to a unit. No real unit is defined." Vector__XXX
 SG_ StatusValvetrain : 12|2@1+ (1,0) [0|3] "" Vector__XXX
 SG_ StatusElectricMode : 14|2@1+ (1,0) [0|3] "" Vector__XXX
 SG_ ST_CENG_DRV : 16|4@1+ (1,0) [0|15] "" Vector__XXX
 SG_ ST_UDP : 20|4@1+ (1,0) [0|15] "" Vector__XXX
 SG_ ST_ENERG_SUPY : 24|8@1+ (1,0) [0|255] "" Vector__XXX
 SG_ ST_MOT_DRV : 32|2@1+ (1,0) [0|3] "" Vector__XXX
 SG_ ST_ANO_MSA_ENG_STOP : 34|2@1+ (1,0) [0|3] "" Vector__XXX
 SG_ TR_HHASS_MSA : 36|4@1+ (1,0) [0|15] "" Vector__XXX
 SG_ CTR_LED_PUBU_MSA : 40|2@1+ (1,0) [0|3] "" Vector__XXX
 SG_ PowertrainConfigurationAccelerat : 42|3@1+ (1,0) [0|7] "" Vector__XXX
 SG_ PowertrainConfigurationLoadShock : 45|3@1+ (1,0) [0|7] "" Vector__XXX
 SG_ PowertrainConfigurationDashpot : 48|3@1+ (1,0) [0|7] "" Vector__XXX
 SG_ PowertrainConfigurationGearbox : 51|5@1+ (1,0) [0|31] "" Vector__XXX
 SG_ ST_CENG_dummy_56_63 : 56|8@1+ (1,0) [-128|127] "" Vector__XXX

BO_ 948 ST_CHGINTF: 8 EME
 SG_ ST_CHGWR_PLGD : 16|2@1+ (1,0) [0|3] "" ZGW,Kombi,BDC_Body,Kombi_Basis
 SG_ ST_LOKG_CHGP : 26|2@1+ (1,0) [0|3] "" ZGW
 SG_ ST_PIL : 32|3@1+ (1,0) [0|7] "" BDC_Body
 SG_ ST_DC_CHGWR_PLGD : 35|2@1+ (1,0) [0|3] "" ZGW,Kombi,BDC_Body,Kombi_Basis
 SG_ DisplayPositionPlug : 40|3@1+ (1,0) [0|7] "" Kombi
 SG_ CHGNG_TYP_IMME : 48|8@1+ (1,0) [0|255] "" CDC_ZGW,Kombi,ZGW

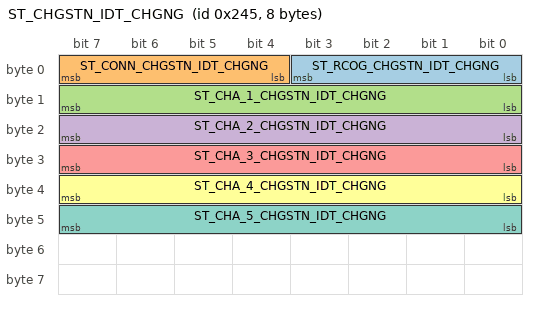
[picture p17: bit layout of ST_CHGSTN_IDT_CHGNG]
BO_ 581 ST_CHGSTN_IDT_CHGNG: 8 EME
 SG_ ST_RCOG_CHGSTN_IDT_CHGNG : 0|4@1+ (1,0) [0|15] "" ZGW
 SG_ ST_CONN_CHGSTN_IDT_CHGNG : 4|4@1+ (1,0) [0|15] "" ZGW
 SG_ ST_CHA_1_CHGSTN_IDT_CHGNG : 8|8@1+ (1,0) [0|254] "This unit fulfills the required AUTOSAR reference to a unit. No real unit is defined." ZGW
 SG_ ST_CHA_2_CHGSTN_IDT_CHGNG : 16|8@1+ (1,0) [0|254] "This unit fulfills the required AUTOSAR reference to a unit. No real unit is defined." ZGW
 SG_ ST_CHA_3_CHGSTN_IDT_CHGNG : 24|8@1+ (1,0) [0|254] "This unit fulfills the required AUTOSAR reference to a unit. No real unit is defined." ZGW
 SG_ ST_CHA_4_CHGSTN_IDT_CHGNG : 32|8@1+ (1,0) [0|254] "This unit fulfills the required AUTOSAR reference to a unit. No real unit is defined." ZGW
 SG_ ST_CHA_5_CHGSTN_IDT_CHGNG : 40|8@1+ (1,0) [0|254] "This unit fulfills the required AUTOSAR reference to a unit. No real unit is defined." ZGW

BO_ 588 ST_CLSY_DO_LA: 8 ZGW
 SG_ ST_CT_RSCR_LCL : 34|2@1+ (1,0) [0|3] "" Kombi,Kombi_Basis

BO_TX_BU_ 916 : Kombi,Kombi_Basis;
BO_TX_BU_ 808 : Kombi,Kombi_Basis;
BO_TX_BU_ 786 : Kombi,Kombi_Basis;
BO_TX_BU_ 860 : Kombi,Kombi_Basis;
BO_TX_BU_ 1079 : FLA,ZGW;
BO_TX_BU_ 948 : EME,ZGW;
CM_ BO_ 199  "Mit dieser Nachricht werden ein Teil der Daten f�r RTM (RealTimeMonitoring) von der EME an das ZGW gesendet. Die EME sammelt die Daten ein und sendet sie als Multiplex-Nachricht ans ZGW (RTM-Funktion).
Aktuell werden 22 PDUs im Abstand von mind. 20ms mit MUX-Daten versendet.
Zykluszeit der 22 verwendeten PDUs muss jeweils auf 1000ms gesetzt werden.
Der Frame wird nur in China-Varianten versendet.";
CM_ BO_ 543  "Die Versendung dieser Nachricht erfolgt zyklisch ab Klemme R EIN.";

BA_DEF_ BO_ "FrameTriggeringName" STRING;
BA_DEF_ BO_ "GenMsgCycleTime" INT 0 65535;
BA_DEF_ BO_ "GenMsgDelayTime" INT 0 65535;
BA_DEF_ BO_ "GenMsgSendType" ENUM  "cyclicX","spontanX","cyclicIfActiveX","spontanWithDelay","cyclicAndSpontanX","cyclicAndSpontanWithDelay","spontanWithRepitition","cyclicIfActiveAndSpontanWD","cyclicIfActiveFast","cyclicWithRepeatOnDemand","none";
BA_DEF_ BO_ "GenMsgStartValue" STRING;
BA_DEF_ BO_ "PduName" STRING;
BA_DEF_ BO_ "SystemMessageLongSymbol" STRING;
BA_DEF_ SG_ "CompuMethodName" STRING;
BA_DEF_ SG_ "GenSigStartValue" FLOAT 0 100000000000;
BA_DEF_ SG_ "ISignalName" STRING;
BA_DEF_ SG_ "LongName" STRING;
BA_DEF_ SG_ "SysSignalName" STRING;
BA_DEF_ SG_ "SystemSignalLongSymbol" STRING;
BA_ "FrameTriggeringName" BO_ 841 "frTrig_CAN_963411852_841_963396506_963411732_963424759_FA_CAN";
BA_ "GenMsgCycleTime" BO_ 841 200;
BA_ "GenMsgSendType" BO_ 841 0;
BA_ "GenMsgStartValue" BO_ 841 "0000000000";
BA_ "PduName" BO_ 841 "RAW_DATA_TANK";
BA_ "FrameTriggeringName" BO_ 625 "frTrig_CAN_963411942_625_963396678_963411732_963424759_FA_CAN";
BA_ "GenMsgDelayTime" BO_ 625 60;
BA_ "GenMsgSendType" BO_ 625 1;
BA_ "GenMsgStartValue" BO_ 625 "0000000000000000";
BA_ "PduName" BO_ 625 "RCOG_SL_CAM";
BA_ "FrameTriggeringName" BO_ 614 "frTrig_CAN_963411740_614_963394157_963411732_963424759_FA_CAN";
BA_ "GenMsgDelayTime" BO_ 614 60;
BA_ "GenMsgSendType" BO_ 614 1;
BA_ "GenMsgStartValue" BO_ 614 "0000da0000000000";
BA_ "PduName" BO_ 614 "RCOG_TRLI_CAM";
BA_ "FrameTriggeringName" BO_ 647 "frTrig_CAN_963412064_647_963393854_963411732_963424759_FA_CAN";
BA_ "GenMsgCycleTime" BO_ 647 500;
BA_ "GenMsgDelayTime" BO_ 647 100;
BA_ "GenMsgSendType" BO_ 647 4;
BA_ "GenMsgStartValue" BO_ 647 "0000000000000000";
BA_ "PduName" BO_ 647 "RCOG_TRSG";
BA_ "FrameTriggeringName" BO_ 607 "frTrig_CAN_963411967_607_963405823_963411732_963424759_FA_CAN";
BA_ "GenMsgDelayTime" BO_ 607 100;
BA_ "GenMsgSendType" BO_ 607 1;
BA_ "GenMsgStartValue" BO_ 607 "0000000000e70000";
BA_ "PduName" BO_ 607 "RCOG_TRSG_CAM";
BA_ "FrameTriggeringName" BO_ 370 "frTrig_CAN_963411964_370_963403256_963411732_963424759_FA_CAN";
BA_ "GenMsgDelayTime" BO_ 370 50;
BA_ "GenMsgSendType" BO_ 370 1;
BA_ "GenMsgStartValue" BO_ 370 "0000000000";
BA_ "PduName" BO_ 370 "RCPT_RQ_KI";
BA_ "FrameTriggeringName" BO_ 916 "frTrig_CAN_963411991_916_963403249_963411732_963424759_FA_CAN";
BA_ "GenMsgDelayTime" BO_ 916 100;
BA_ "GenMsgSendType" BO_ 916 1;
BA_ "GenMsgStartValue" BO_ 916 "0000000000000000";
BA_ "PduName" BO_ 916 "RDA_REQUEST";
BA_ "FrameTriggeringName" BO_ 808 "frTrig_CAN_963411780_808_963402693_963411732_963424759_FA_CAN";
BA_ "GenMsgCycleTime" BO_ 808 1000;
BA_ "GenMsgDelayTime" BO_ 808 200;
BA_ "GenMsgSendType" BO_ 808 4;
BA_ "GenMsgStartValue" BO_ 808 "000000000000";
BA_ "PduName" BO_ 808 "RELATIVZEIT";
BA_ "FrameTriggeringName" BO_ 349 "frTrig_CAN_963411997_349_963405206_963411732_963424759_FA_CAN";
BA_ "GenMsgCycleTime" BO_ 349 1000;
BA_ "GenMsgDelayTime" BO_ 349 20;
BA_ "GenMsgSendType" BO_ 349 4;
BA_ "GenMsgStartValue" BO_ 349 "0000000000000000";
BA_ "PduName" BO_ 349 "REQ_EMS";
BA_ "FrameTriggeringName" BO_ 891 "frTrig_CAN_963412072_891_963401213_963411732_963424759_FA_CAN";
BA_ "GenMsgCycleTime" BO_ 891 10000;
BA_ "GenMsgDelayTime" BO_ 891 200;
BA_ "GenMsgSendType" BO_ 891 4;
BA_ "GenMsgStartValue" BO_ 891 "00000000000000";
BA_ "PduName" BO_ 891 "RLS_COOL_HVSTO";
BA_ "FrameTriggeringName" BO_ 735 "frTrig_CAN_963411817_735_963398771_963411732_963424759_FA_CAN";
BA_ "GenMsgCycleTime" BO_ 735 1000;
BA_ "GenMsgDelayTime" BO_ 735 100;
BA_ "GenMsgSendType" BO_ 735 4;
BA_ "GenMsgStartValue" BO_ 735 "0000000000000000";
BA_ "PduName" BO_ 735 "RLS_PWR_FNS_AIC_1";
BA_ "FrameTriggeringName" BO_ 741 "frTrig_CAN_963412163_741_963401233_963411732_963424759_FA_CAN";
BA_ "GenMsgCycleTime" BO_ 741 1000;
BA_ "GenMsgDelayTime" BO_ 741 100;
BA_ "GenMsgSendType" BO_ 741 4;
BA_ "GenMsgStartValue" BO_ 741 "0000000000000000";
BA_ "PduName" BO_ 741 "RLS_PWR_FNS_AIC_2";
BA_ "FrameTriggeringName" BO_ 968 "frTrig_CAN_963412054_968_963399086_963411732_963424759_FA_CAN";
BA_ "GenMsgCycleTime" BO_ 968 1000;
BA_ "GenMsgDelayTime" BO_ 968 100;
BA_ "GenMsgSendType" BO_ 968 4;
BA_ "GenMsgStartValue" BO_ 968 "0000000088130000";
BA_ "PduName" BO_ 968 "RNG_MAP_INFO";
BA_ "FrameTriggeringName" BO_ 761 "frTrig_CAN_963411971_761_963403413_963411732_963424759_FA_CAN";
BA_ "GenMsgCycleTime" BO_ 761 1000;
BA_ "GenMsgDelayTime" BO_ 761 50;
BA_ "GenMsgSendType" BO_ 761 4;
BA_ "GenMsgStartValue" BO_ 761 "00000000000000";
BA_ "PduName" BO_ 761 "RQ_AIC";
BA_ "FrameTriggeringName" BO_ 512 "frTrig_CAN_963412006_512_963394349_963411732_963424759_FA_CAN";
BA_ "GenMsgCycleTime" BO_ 512 1000;
BA_ "GenMsgDelayTime" BO_ 512 50;
BA_ "GenMsgSendType" BO_ 512 4;
BA_ "GenMsgStartValue" BO_ 512 "0000000000000000";
BA_ "PduName" BO_ 512 "RQ_AIC_1";
BA_ "FrameTriggeringName" BO_ 665 "frTrig_CAN_963411762_665_963389409_963411732_963424759_FA_CAN";
BA_ "GenMsgCycleTime" BO_ 665 1000;
BA_ "GenMsgDelayTime" BO_ 665 200;
BA_ "GenMsgSendType" BO_ 665 4;
BA_ "GenMsgStartValue" BO_ 665 "0000000000000000";
BA_ "PduName" BO_ 665 "RQ_AIC_HYB";
BA_ "FrameTriggeringName" BO_ 160 "frTrig_CAN_963411881_160_963401124_963411732_963424759_FA_CAN";
BA_ "GenMsgCycleTime" BO_ 160 30;
BA_ "GenMsgSendType" BO_ 160 0;
BA_ "GenMsgStartValue" BO_ 160 "0000000000000000";
BA_ "PduName" BO_ 160 "RQ_TORQ_CRSH_GRB_2";
BA_ "FrameTriggeringName" BO_ 258 "frTrig_CAN_963411962_258_963391949_963411732_963424759_FA_CAN";
BA_ "GenMsgCycleTime" BO_ 258 500;
BA_ "GenMsgDelayTime" BO_ 258 20;
BA_ "GenMsgSendType" BO_ 258 4;
BA_ "GenMsgStartValue" BO_ 258 "0000008000000080";
BA_ "PduName" BO_ 258 "RQ_WBK_ACOU";
BA_ "FrameTriggeringName" BO_ 261 "frTrig_CAN_963411858_261_963391769_963411732_963424759_FA_CAN";
BA_ "GenMsgCycleTime" BO_ 261 500;
BA_ "GenMsgDelayTime" BO_ 261 20;
BA_ "GenMsgSendType" BO_ 261 4;
BA_ "GenMsgStartValue" BO_ 261 "0000008000000080";
BA_ "PduName" BO_ 261 "RQ_WBK_DISP";
BA_ "FrameTriggeringName" BO_ 199 "frTrig_CAN_963411926_199_963396673_963411732_963424759_FA_CAN";
BA_ "GenMsgSendType" BO_ 199 1;
BA_ "GenMsgStartValue" BO_ 199 "0000000000000000";
BA_ "PduName" BO_ 199 "RTM_DT";
BA_ "FrameTriggeringName" BO_ 1096 "frTrig_CAN_963411822_1096_963394063_963411732_963424759_FA_CAN";
BA_ "GenMsgDelayTime" BO_ 1096 200;
BA_ "GenMsgSendType" BO_ 1096 1;
BA_ "GenMsgStartValue" BO_ 1096 "0000000000000000";
BA_ "PduName" BO_ 1096 "RequestKeyAction";
BA_ "FrameTriggeringName" BO_ 464 "frTrig_CAN_963411873_464_963394341_963411732_963424759_FA_CAN";
BA_ "GenMsgCycleTime" BO_ 464 1000;
BA_ "GenMsgDelayTime" BO_ 464 10;
BA_ "GenMsgSendType" BO_ 464 4;
BA_ "GenMsgStartValue" BO_ 464 "0080000000800c00";
BA_ "PduName" BO_ 464 "SAFG_PT";
BA_ "FrameTriggeringName" BO_ 482 "frTrig_CAN_963411797_482_963393870_963411732_963424759_FA_CAN";
BA_ "GenMsgDelayTime" BO_ 482 50;
BA_ "GenMsgSendType" BO_ 482 1;
BA_ "GenMsgStartValue" BO_ 482 "0000000000000000";
BA_ "PduName" BO_ 482 "SECU_FAHRGESTELLNUMMER";
BA_ "FrameTriggeringName" BO_ 786 "frTrig_CAN_963411801_786_963403200_963411732_963424759_FA_CAN";
BA_ "GenMsgDelayTime" BO_ 786 100;
BA_ "GenMsgSendType" BO_ 786 1;
BA_ "GenMsgStartValue" BO_ 786 "0000";
BA_ "PduName" BO_ 786 "SERV_C_TELESERV";
BA_ "FrameTriggeringName" BO_ 933 "frTrig_CAN_963411884_933_963388814_963411732_963424759_FA_CAN";
BA_ "GenMsgCycleTime" BO_ 933 5000;
BA_ "GenMsgDelayTime" BO_ 933 160;
BA_ "GenMsgSendType" BO_ 933 4;
BA_ "GenMsgStartValue" BO_ 933 "0000000000";
BA_ "PduName" BO_ 933 "SLRDI_GLB_FZM";
BA_ "FrameTriggeringName" BO_ 843 "frTrig_CAN_963411800_843_963400672_963411732_963424759_FA_CAN";
BA_ "GenMsgCycleTime" BO_ 843 1000;
BA_ "GenMsgDelayTime" BO_ 843 100;
BA_ "GenMsgSendType" BO_ 843 4;
BA_ "GenMsgStartValue" BO_ 843 "0000000000000000";
BA_ "PduName" BO_ 843 "STATE_SBIL_DR";
BA_ "FrameTriggeringName" BO_ 845 "frTrig_CAN_963412105_845_963391239_963411732_963424759_FA_CAN";
BA_ "GenMsgCycleTime" BO_ 845 1000;
BA_ "GenMsgDelayTime" BO_ 845 100;
BA_ "GenMsgSendType" BO_ 845 4;
BA_ "GenMsgStartValue" BO_ 845 "0000000000000000";
BA_ "PduName" BO_ 845 "STATE_SBIL_PS";
BA_ "FrameTriggeringName" BO_ 740 "frTrig_CAN_963411955_740_963391115_963411732_963424759_FA_CAN";
BA_ "GenMsgCycleTime" BO_ 740 5000;
BA_ "GenMsgDelayTime" BO_ 740 100;
BA_ "GenMsgSendType" BO_ 740 4;
BA_ "GenMsgStartValue" BO_ 740 "8080000000808000";
BA_ "PduName" BO_ 740 "STAT_ANHAENGER";
BA_ "FrameTriggeringName" BO_ 860 "frTrig_CAN_963412027_860_963396685_963411732_963424759_FA_CAN";
BA_ "GenMsgCycleTime" BO_ 860 5000;
BA_ "GenMsgDelayTime" BO_ 860 200;
BA_ "GenMsgSendType" BO_ 860 4;
BA_ "GenMsgStartValue" BO_ 860 "0000005000000000";
BA_ "PduName" BO_ 860 "STAT_BC_BN2020";
BA_ "FrameTriggeringName" BO_ 554 "frTrig_CAN_963412067_554_963393649_963411732_963424759_FA_CAN";
BA_ "GenMsgCycleTime" BO_ 554 5000;
BA_ "GenMsgDelayTime" BO_ 554 50;
BA_ "GenMsgSendType" BO_ 554 4;
BA_ "GenMsgStartValue" BO_ 554 "0000000000000000";
BA_ "PduName" BO_ 554 "STAT_BFS";
BA_ "FrameTriggeringName" BO_ 558 "frTrig_CAN_963412085_558_963405112_963411732_963424759_FA_CAN";
BA_ "GenMsgCycleTime" BO_ 558 5000;
BA_ "GenMsgDelayTime" BO_ 558 50;
BA_ "GenMsgSendType" BO_ 558 4;
BA_ "GenMsgStartValue" BO_ 558 "0000000000000000";
BA_ "PduName" BO_ 558 "STAT_BFSH";
BA_ "FrameTriggeringName" BO_ 847 "frTrig_CAN_963411806_847_963398241_963411732_963424759_FA_CAN";
BA_ "GenMsgCycleTime" BO_ 847 5000;
BA_ "GenMsgDelayTime" BO_ 847 50;
BA_ "GenMsgSendType" BO_ 847 4;
BA_ "GenMsgStartValue" BO_ 847 "0000";
BA_ "PduName" BO_ 847 "STAT_CT_HABR";
BA_ "FrameTriggeringName" BO_ 722 "frTrig_CAN_963411766_722_963391751_963411732_963424759_FA_CAN";
BA_ "GenMsgCycleTime" BO_ 722 20000;
BA_ "GenMsgDelayTime" BO_ 722 500;
BA_ "GenMsgSendType" BO_ 722 4;
BA_ "GenMsgStartValue" BO_ 722 "0000000000";
BA_ "PduName" BO_ 722 "STAT_DRUCK_KAELTE";
BA_ "FrameTriggeringName" BO_ 481 "frTrig_CAN_963412021_481_963402935_963411732_963424759_FA_CAN";
BA_ "GenMsgCycleTime" BO_ 481 200;
BA_ "GenMsgDelayTime" BO_ 481 100;
BA_ "GenMsgSendType" BO_ 481 4;
BA_ "GenMsgStartValue" BO_ 481 "008000000080";
BA_ "PduName" BO_ 481 "STAT_DS_VRFD";
BA_ "FrameTriggeringName" BO_ 779 "frTrig_CAN_963411737_779_963396250_963411732_963424759_FA_CAN";
BA_ "GenMsgCycleTime" BO_ 779 100;
BA_ "GenMsgDelayTime" BO_ 779 10;
BA_ "GenMsgSendType" BO_ 779 4;
BA_ "GenMsgStartValue" BO_ 779 "0000000000006408";
BA_ "PduName" BO_ 779 "STAT_ENG_STA_AUTO";
BA_ "FrameTriggeringName" BO_ 788 "frTrig_CAN_963411739_788_963402705_963411732_963424759_FA_CAN";
BA_ "GenMsgCycleTime" BO_ 788 160;
BA_ "GenMsgDelayTime" BO_ 788 100;
BA_ "GenMsgSendType" BO_ 788 4;
BA_ "GenMsgStartValue" BO_ 788 "1000000000";
BA_ "PduName" BO_ 788 "STAT_FAHRLICHT";
BA_ "FrameTriggeringName" BO_ 562 "frTrig_CAN_963412047_562_963393521_963411732_963424759_FA_CAN";
BA_ "GenMsgCycleTime" BO_ 562 5000;
BA_ "GenMsgDelayTime" BO_ 562 50;
BA_ "GenMsgSendType" BO_ 562 4;
BA_ "GenMsgStartValue" BO_ 562 "0000000000000000";
BA_ "PduName" BO_ 562 "STAT_FAS";
BA_ "FrameTriggeringName" BO_ 566 "frTrig_CAN_963412106_566_963400676_963411732_963424759_FA_CAN";
BA_ "GenMsgCycleTime" BO_ 566 5000;
BA_ "GenMsgDelayTime" BO_ 566 50;
BA_ "GenMsgSendType" BO_ 566 4;
BA_ "GenMsgStartValue" BO_ 566 "0000000000000000";
BA_ "PduName" BO_ 566 "STAT_FASH";
BA_ "FrameTriggeringName" BO_ 570 "frTrig_CAN_963412013_570_963388867_963411732_963424759_FA_CAN";
BA_ "GenMsgCycleTime" BO_ 570 100;
BA_ "GenMsgDelayTime" BO_ 570 50;
BA_ "GenMsgSendType" BO_ 570 4;
BA_ "GenMsgStartValue" BO_ 570 "0000000000000000";
BA_ "PduName" BO_ 570 "STAT_FUNKSCHLUESSEL";
BA_ "FrameTriggeringName" BO_ 944 "frTrig_CAN_963412103_944_963393914_963411732_963424759_FA_CAN";
BA_ "GenMsgCycleTime" BO_ 944 1000;
BA_ "GenMsgDelayTime" BO_ 944 50;
BA_ "GenMsgSendType" BO_ 944 4;
BA_ "GenMsgStartValue" BO_ 944 "0000";
BA_ "PduName" BO_ 944 "STAT_GANG_RUECKWAERTS";
BA_ "FrameTriggeringName" BO_ 274 "frTrig_CAN_963411984_274_963394228_963411732_963424759_FA_CAN";
BA_ "GenMsgCycleTime" BO_ 274 20;
BA_ "GenMsgSendType" BO_ 274 0;
BA_ "GenMsgStartValue" BO_ 274 "cdfc000000000000";
BA_ "PduName" BO_ 274 "STAT_HVSTO_2";
BA_ "FrameTriggeringName" BO_ 814 "frTrig_CAN_963411770_814_963398379_963411732_963424759_FA_CAN";
BA_ "GenMsgCycleTime" BO_ 814 1000;
BA_ "GenMsgSendType" BO_ 814 0;
BA_ "GenMsgStartValue" BO_ 814 "0000000af6000005";
BA_ "PduName" BO_ 814 "STAT_KLIMA_INTERN";
BA_ "FrameTriggeringName" BO_ 742 "frTrig_CAN_963411798_742_963402689_963411732_963424759_FA_CAN";
BA_ "GenMsgCycleTime" BO_ 742 10000;
BA_ "GenMsgDelayTime" BO_ 742 100;
BA_ "GenMsgSendType" BO_ 742 4;
BA_ "GenMsgStartValue" BO_ 742 "0000000000000010";
BA_ "PduName" BO_ 742 "STAT_KLIMA_LUFT_FA";
BA_ "FrameTriggeringName" BO_ 752 "frTrig_CAN_963412092_752_963402674_963411732_963424759_FA_CAN";
BA_ "GenMsgCycleTime" BO_ 752 2000;
BA_ "GenMsgDelayTime" BO_ 752 100;
BA_ "GenMsgSendType" BO_ 752 4;
BA_ "GenMsgStartValue" BO_ 752 "0000000000";
BA_ "PduName" BO_ 752 "STAT_KLIMA_STAND";
BA_ "FrameTriggeringName" BO_ 542 "frTrig_CAN_963412022_542_963399075_963411732_963424759_FA_CAN";
BA_ "GenMsgCycleTime" BO_ 542 200;
BA_ "GenMsgDelayTime" BO_ 542 200;
BA_ "GenMsgSendType" BO_ 542 4;
BA_ "GenMsgStartValue" BO_ 542 "00000000000000";
BA_ "PduName" BO_ 542 "STAT_NIVI";
BA_ "FrameTriggeringName" BO_ 543 "frTrig_CAN_963411930_543_963393950_963411732_963424759_FA_CAN";
BA_ "GenMsgCycleTime" BO_ 543 1000;
BA_ "GenMsgDelayTime" BO_ 543 200;
BA_ "GenMsgSendType" BO_ 543 4;
BA_ "GenMsgStartValue" BO_ 543 "0000000000000000";
BA_ "PduName" BO_ 543 "STAT_OBJ_COOR";
BA_ "FrameTriggeringName" BO_ 783 "frTrig_CAN_963411901_783_963405648_963411732_963424759_FA_CAN";
BA_ "GenMsgDelayTime" BO_ 783 10;
BA_ "GenMsgSendType" BO_ 783 1;
BA_ "GenMsgStartValue" BO_ 783 "0000";
BA_ "PduName" BO_ 783 "STAT_SERV_C_TELEX";
BA_ "FrameTriggeringName" BO_ 594 "frTrig_CAN_963411846_594_963393858_963411732_963424759_FA_CAN";
BA_ "GenMsgDelayTime" BO_ 594 50;
BA_ "GenMsgSendType" BO_ 594 1;
BA_ "GenMsgStartValue" BO_ 594 "0000";
BA_ "PduName" BO_ 594 "STAT_WISCHER";
BA_ "FrameTriggeringName" BO_ 764 "frTrig_CAN_963412112_764_963396018_963411732_963424759_FA_CAN";
BA_ "GenMsgCycleTime" BO_ 764 5000;
BA_ "GenMsgDelayTime" BO_ 764 100;
BA_ "GenMsgSendType" BO_ 764 4;
BA_ "GenMsgStartValue" BO_ 764 "0000000000000000";
BA_ "PduName" BO_ 764 "STAT_ZV_KLAPPEN";
BA_ "FrameTriggeringName" BO_ 719 "frTrig_CAN_963411982_719_963391772_963411732_963424759_FA_CAN";
BA_ "GenMsgCycleTime" BO_ 719 20000;
BA_ "GenMsgDelayTime" BO_ 719 500;
BA_ "GenMsgSendType" BO_ 719 4;
BA_ "GenMsgStartValue" BO_ 719 "0000";
BA_ "PduName" BO_ 719 "STAT_ZWP";
BA_ "FrameTriggeringName" BO_ 770 "frTrig_CAN_963412075_770_963393778_963411732_963424759_FA_CAN";
BA_ "GenMsgCycleTime" BO_ 770 40;
BA_ "GenMsgSendType" BO_ 770 0;
BA_ "GenMsgStartValue" BO_ 770 "0000a6ff000000";
BA_ "PduName" BO_ 770 "STEA_FTAX_EFFV";
BA_ "FrameTriggeringName" BO_ 756 "frTrig_CAN_963411791_756_963395954_963411732_963424759_FA_CAN";
BA_ "GenMsgCycleTime" BO_ 756 500;
BA_ "GenMsgSendType" BO_ 756 0;
BA_ "GenMsgStartValue" BO_ 756 "0000";
BA_ "PduName" BO_ 756 "ST_ACTVN_HSFZ";
BA_ "FrameTriggeringName" BO_ 957 "frTrig_CAN_963411768_957_963403192_963411732_963424759_FA_CAN";
BA_ "GenMsgCycleTime" BO_ 957 10000;
BA_ "GenMsgDelayTime" BO_ 957 200;
BA_ "GenMsgSendType" BO_ 957 4;
BA_ "GenMsgStartValue" BO_ 957 "0000000000000000";
BA_ "PduName" BO_ 957 "ST_ACTVN_MIKO";
BA_ "FrameTriggeringName" BO_ 663 "frTrig_CAN_963412023_663_963395993_963411732_963424759_FA_CAN";
BA_ "GenMsgCycleTime" BO_ 663 200;
BA_ "GenMsgDelayTime" BO_ 663 40;
BA_ "GenMsgSendType" BO_ 663 4;
BA_ "GenMsgStartValue" BO_ 663 "00800000000000";
BA_ "PduName" BO_ 663 "ST_BLT_CT_SOCCU";
BA_ "FrameTriggeringName" BO_ 1200 "frTrig_CAN_963411813_1200_963405146_963411732_963424759_FA_CAN";
BA_ "GenMsgCycleTime" BO_ 1200 5000;
BA_ "GenMsgDelayTime" BO_ 1200 100;
BA_ "GenMsgSendType" BO_ 1200 4;
BA_ "GenMsgStartValue" BO_ 1200 "0000000000000000";
BA_ "PduName" BO_ 1200 "ST_BN_COS_CTR";
BA_ "FrameTriggeringName" BO_ 834 "frTrig_CAN_963412082_834_963393492_963411732_963424759_FA_CAN";
BA_ "GenMsgCycleTime" BO_ 834 1000;
BA_ "GenMsgDelayTime" BO_ 834 100;
BA_ "GenMsgSendType" BO_ 834 4;
BA_ "GenMsgStartValue" BO_ 834 "0000000000008000";
BA_ "PduName" BO_ 834 "ST_CABRF";
BA_ "FrameTriggeringName" BO_ 1079 "frTrig_CAN_963412159_1079_963401229_963411732_963424759_FA_CAN";
BA_ "GenMsgCycleTime" BO_ 1079 5000;
BA_ "GenMsgSendType" BO_ 1079 0;
BA_ "GenMsgStartValue" BO_ 1079 "fbfb0000";
BA_ "PduName" BO_ 1079 "ST_CAM_CAL";
BA_ "FrameTriggeringName" BO_ 50 "frTrig_CAN_963411906_50_963400599_963411732_963424759_FA_CAN";
BA_ "GenMsgCycleTime" BO_ 50 1000;
BA_ "GenMsgDelayTime" BO_ 50 10;
BA_ "GenMsgSendType" BO_ 50 4;
BA_ "GenMsgStartValue" BO_ 50 "0000000000000080";
BA_ "PduName" BO_ 50 "ST_CENG";
BA_ "FrameTriggeringName" BO_ 948 "frTrig_CAN_963411745_948_963398259_963411732_963424759_FA_CAN";
BA_ "GenMsgCycleTime" BO_ 948 200;
BA_ "GenMsgDelayTime" BO_ 948 40;
BA_ "GenMsgSendType" BO_ 948 4;
BA_ "GenMsgStartValue" BO_ 948 "0000000000000000";
BA_ "PduName" BO_ 948 "ST_CHGINTF";
BA_ "FrameTriggeringName" BO_ 581 "frTrig_CAN_963412001_581_963394217_963411732_963424759_FA_CAN";
BA_ "GenMsgDelayTime" BO_ 581 100;
BA_ "GenMsgSendType" BO_ 581 1;
BA_ "GenMsgStartValue" BO_ 581 "0000000000000000";
BA_ "PduName" BO_ 581 "ST_CHGSTN_IDT_CHGNG";
BA_ "FrameTriggeringName" BO_ 588 "frTrig_CAN_963412043_588_963388912_963411732_963424759_FA_CAN";
BA_ "GenMsgCycleTime" BO_ 588 5000;
BA_ "GenMsgDelayTime" BO_ 588 100;
BA_ "GenMsgSendType" BO_ 588 4;
BA_ "GenMsgStartValue" BO_ 588 "0000000000000000";
BA_ "PduName" BO_ 588 "ST_CLSY_DO_LA";
BA_ "CompuMethodName" SG_ 841 RWDT_SEN_FLLV_FUTA_L "RWDT_SEN_FLLV_FUTA_LH";
BA_ "ISignalName" SG_ 841 RWDT_SEN_FLLV_FUTA_L "RWDT_SEN_FLLV_FUTA_L";
BA_ "LongName" SG_ 841 RWDT_SEN_FLLV_FUTA_L "Rohdaten_Sensor_Füllstand_Tank_Links";
BA_ "SysSignalName" SG_ 841 RWDT_SEN_FLLV_FUTA_L "RWDT_SEN_FLLV_FUTA_L";
BA_ "CompuMethodName" SG_ 841 RWDT_SEN_FLLV_FUTA_R "UI_16_0_0_65535_0_10s_0_noEnc_hasRng_1";
BA_ "ISignalName" SG_ 841 RWDT_SEN_FLLV_FUTA_R "RWDT_SEN_FLLV_FUTA_R";
BA_ "LongName" SG_ 841 RWDT_SEN_FLLV_FUTA_R "Rohdaten_Sensor_Füllstand_Tank_Rechts";
BA_ "SysSignalName" SG_ 841 RWDT_SEN_FLLV_FUTA_R "RWDT_SEN_FLLV_FUTA_R";
BA_ "CompuMethodName" SG_ 625 ID_RCOG_SL_CAM "ID_RCOG_SL_CAM";
BA_ "ISignalName" SG_ 625 ID_RCOG_SL_CAM "ID_RCOG_SL_CAM";
BA_ "LongName" SG_ 625 ID_RCOG_SL_CAM "ID_Erkennung_Haltelinie_Kamera";
BA_ "SysSignalName" SG_ 625 ID_RCOG_SL_CAM "ID_RCOG_SL_CAM";
BA_ "CompuMethodName" SG_ 625 ST_MEASMT_SL_CAM "ST_MEASMT_SL_CAM";
BA_ "ISignalName" SG_ 625 ST_MEASMT_SL_CAM "ST_MEASMT_SL_CAM";
BA_ "LongName" SG_ 625 ST_MEASMT_SL_CAM "Status_Messung_Haltelinie_Kamera";
BA_ "SysSignalName" SG_ 625 ST_MEASMT_SL_CAM "ST_MEASMT_SL_CAM";
BA_ "CompuMethodName" SG_ 625 XPO_RCOG_SL_CAM "XPO_RCOG_SL_CAM";
BA_ "ISignalName" SG_ 625 XPO_RCOG_SL_CAM "XPO_RCOG_SL_CAM";
BA_ "LongName" SG_ 625 XPO_RCOG_SL_CAM "x-Position_Erkennung_Haltelinie_Kamera";
BA_ "SysSignalName" SG_ 625 XPO_RCOG_SL_CAM "XPO_RCOG_SL_CAM";
BA_ "CompuMethodName" SG_ 625 PI_RCOG_SL_CAM "PI_RCOG_SL_CAM";
BA_ "ISignalName" SG_ 625 PI_RCOG_SL_CAM "PI_RCOG_SL_CAM";
BA_ "LongName" SG_ 625 PI_RCOG_SL_CAM "Phi_Erkennung_Haltelinie_Kamera";
BA_ "SysSignalName" SG_ 625 PI_RCOG_SL_CAM "PI_RCOG_SL_CAM";
BA_ "CompuMethodName" SG_ 625 CRE_SL_CAM "CRE_SL_CAM";
BA_ "ISignalName" SG_ 625 CRE_SL_CAM "CRE_SL_CAM";
BA_ "LongName" SG_ 625 CRE_SL_CAM "Erkennungskonfidenz_Haltelinie_Kamera";
BA_ "SysSignalName" SG_ 625 CRE_SL_CAM "CRE_SL_CAM";
BA_ "CompuMethodName" SG_ 625 CTY_SL_CAM "CTY_SL_CAM";
BA_ "ISignalName" SG_ 625 CTY_SL_CAM "CTY_SL_CAM";
BA_ "LongName" SG_ 625 CTY_SL_CAM "Klassifikationstyp_Haltelinie_Kamera";
BA_ "SysSignalName" SG_ 625 CTY_SL_CAM "CTY_SL_CAM";
BA_ "CompuMethodName" SG_ 614 TRLI_ID "TRLI_ID";
BA_ "ISignalName" SG_ 614 TRLI_ID "TRLI_ID";
BA_ "LongName" SG_ 614 TRLI_ID "Ampel_ID";
BA_ "SysSignalName" SG_ 614 TRLI_ID "TRLI_ID";
BA_ "CompuMethodName" SG_ 614 TRLI_PO_X "TRLI_PO_X";
BA_ "ISignalName" SG_ 614 TRLI_PO_X "TRLI_PO_X";
BA_ "LongName" SG_ 614 TRLI_PO_X "Ampel_Position_X";
BA_ "SysSignalName" SG_ 614 TRLI_PO_X "TRLI_PO_X";
BA_ "CompuMethodName" SG_ 614 TRLI_PO_Y "TRLI_PO_Y";
BA_ "GenSigStartValue" SG_ 614 TRLI_PO_Y -38;
BA_ "ISignalName" SG_ 614 TRLI_PO_Y "TRLI_PO_Y";
BA_ "LongName" SG_ 614 TRLI_PO_Y "Ampel_Position_Y";
BA_ "SysSignalName" SG_ 614 TRLI_PO_Y "TRLI_PO_Y";
BA_ "CompuMethodName" SG_ 614 TRLI_PO_Z "TRLI_PO_Z";
BA_ "ISignalName" SG_ 614 TRLI_PO_Z "TRLI_PO_Z";
BA_ "LongName" SG_ 614 TRLI_PO_Z "Ampel_Position_Z";
BA_ "SysSignalName" SG_ 614 TRLI_PO_Z "TRLI_PO_Z";
BA_ "CompuMethodName" SG_ 614 TRLI_ST "TRLI_ST";
BA_ "ISignalName" SG_ 614 TRLI_ST "TRLI_ST";
BA_ "LongName" SG_ 614 TRLI_ST "Ampel_Status";
BA_ "SysSignalName" SG_ 614 TRLI_ST "TRLI_ST";
BA_ "CompuMethodName" SG_ 614 TRLI_ARRW "TRLI_ARRW";
BA_ "ISignalName" SG_ 614 TRLI_ARRW "TRLI_ARRW";
BA_ "LongName" SG_ 614 TRLI_ARRW "Ampel_Pfeil";
BA_ "SysSignalName" SG_ 614 TRLI_ARRW "TRLI_ARRW";
BA_ "CompuMethodName" SG_ 614 TRLI_IDC "TRLI_IDC";
BA_ "ISignalName" SG_ 614 TRLI_IDC "TRLI_IDC";
BA_ "LongName" SG_ 614 TRLI_IDC "Ampel_Blinken";
BA_ "SysSignalName" SG_ 614 TRLI_IDC "TRLI_IDC";
BA_ "CompuMethodName" SG_ 614 TRLI_CL "TRLI_CL";
BA_ "ISignalName" SG_ 614 TRLI_CL "TRLI_CL";
BA_ "LongName" SG_ 614 TRLI_CL "Ampel_Farbe";
BA_ "SysSignalName" SG_ 614 TRLI_CL "TRLI_CL";
BA_ "CompuMethodName" SG_ 614 QUAL_RCOG_TRLI "QUAL_RCOG_TRLI";
BA_ "ISignalName" SG_ 614 QUAL_RCOG_TRLI "QUAL_RCOG_TRLI";
BA_ "LongName" SG_ 614 QUAL_RCOG_TRLI "Qualität_Erkennung_Ampel";
BA_ "SysSignalName" SG_ 614 QUAL_RCOG_TRLI "QUAL_RCOG_TRLI";
BA_ "CompuMethodName" SG_ 647 PRES_WDR_LIM_V "PRES_WDR_LIM_V";
BA_ "ISignalName" SG_ 647 PRES_WDR_LIM_V "PRES_WDR_LIM_V";
BA_ "LongName" SG_ 647 PRES_WDR_LIM_V "Aktuelle_Aufhebung_Begrenzung_Geschwindigkeit";
BA_ "SysSignalName" SG_ 647 PRES_WDR_LIM_V "PRES_WDR_LIM_V";
BA_ "CompuMethodName" SG_ 647 RCOG_NPA "RCOG_Ueberholverbot";
BA_ "ISignalName" SG_ 647 RCOG_NPA "RCOG_NPA";
BA_ "LongName" SG_ 647 RCOG_NPA "Erkennung_Überholverbot";
BA_ "SysSignalName" SG_ 647 RCOG_NPA "RCOG_NPA";
BA_ "CompuMethodName" SG_ 647 PRES_CLAS_LIM_V "PRES_CLAS_LIM_V";
BA_ "ISignalName" SG_ 647 PRES_CLAS_LIM_V "PRES_CLAS_LIM_V";
BA_ "LongName" SG_ 647 PRES_CLAS_LIM_V "Aktuelle_Klasse_Begrenzung_Geschwindigkeit";
BA_ "SysSignalName" SG_ 647 PRES_CLAS_LIM_V "PRES_CLAS_LIM_V";
BA_ "CompuMethodName" SG_ 647 NXT_CLAS_LIM_V "NXT_CLAS_LIM_V";
BA_ "ISignalName" SG_ 647 NXT_CLAS_LIM_V "NXT_CLAS_LIM_V";
BA_ "LongName" SG_ 647 NXT_CLAS_LIM_V "Nächste_Klasse_Begrenzung_Geschwindigkeit";
BA_ "SysSignalName" SG_ 647 NXT_CLAS_LIM_V "NXT_CLAS_LIM_V";
BA_ "CompuMethodName" SG_ 647 CNCD_TRSG "CNCD_TRSG_1";
BA_ "ISignalName" SG_ 647 CNCD_TRSG "CNCD_TRSG";
BA_ "LongName" SG_ 647 CNCD_TRSG "Ländercodierung_Verkehrszeichen";
BA_ "SysSignalName" SG_ 647 CNCD_TRSG "CNCD_TRSG";
BA_ "CompuMethodName" SG_ 647 UN_V_LIM "UN_V_LIM";
BA_ "ISignalName" SG_ 647 UN_V_LIM "UN_V_LIM";
BA_ "LongName" SG_ 647 UN_V_LIM "Einheit_Geschwindigkeit_Begrenzung";
BA_ "SysSignalName" SG_ 647 UN_V_LIM "UN_V_LIM";
BA_ "CompuMethodName" SG_ 647 ST_DT_MAT_CAM_ADAS "ST_DT_MAT_CAM_ADAS";
BA_ "ISignalName" SG_ 647 ST_DT_MAT_CAM_ADAS "ST_DT_MAT_CAM_ADAS";
BA_ "LongName" SG_ 647 ST_DT_MAT_CAM_ADAS "Status_Daten_Abgleich_Kamera_ADAS";
BA_ "SysSignalName" SG_ 647 ST_DT_MAT_CAM_ADAS "ST_DT_MAT_CAM_ADAS";
BA_ "CompuMethodName" SG_ 647 DISP_SUPSI "DISP_SUPSI";
BA_ "ISignalName" SG_ 647 DISP_SUPSI "DISP_SUPSI";
BA_ "LongName" SG_ 647 DISP_SUPSI "Anzeige_Zusatzzeichen";
BA_ "SysSignalName" SG_ 647 DISP_SUPSI "DISP_SUPSI";
BA_ "CompuMethodName" SG_ 647 CTR_SLI_WARN "CTR_SLI_WARN";
BA_ "ISignalName" SG_ 647 CTR_SLI_WARN "CTR_SLI_WARN";
BA_ "LongName" SG_ 647 CTR_SLI_WARN "Steuerung_SLI_Warnung";
BA_ "SysSignalName" SG_ 647 CTR_SLI_WARN "CTR_SLI_WARN";
BA_ "CompuMethodName" SG_ 647 DISP_V_NPI_DIST "DISP_V_NPI_DIST";
BA_ "ISignalName" SG_ 647 DISP_V_NPI_DIST "DISP_V_NPI_DIST";
BA_ "LongName" SG_ 647 DISP_V_NPI_DIST "Anzeige_Geschwindigkeit_NPI_Distanz";
BA_ "SysSignalName" SG_ 647 DISP_V_NPI_DIST "DISP_V_NPI_DIST";
BA_ "CompuMethodName" SG_ 607 TRSG_ID "TRSG_ID";
BA_ "ISignalName" SG_ 607 TRSG_ID "TRSG_ID";
BA_ "LongName" SG_ 607 TRSG_ID "Verkehrszeichen_ID";
BA_ "SysSignalName" SG_ 607 TRSG_ID "TRSG_ID";
BA_ "CompuMethodName" SG_ 607 TRSG_TYP "TRSG_TYP";
BA_ "ISignalName" SG_ 607 TRSG_TYP "TRSG_TYP";
BA_ "LongName" SG_ 607 TRSG_TYP "Verkehrszeichen_Typ";
BA_ "SysSignalName" SG_ 607 TRSG_TYP "TRSG_TYP";
BA_ "CompuMethodName" SG_ 607 TRSG_ADDON_TYP_1 "TRSG_ADDON_TYP";
BA_ "ISignalName" SG_ 607 TRSG_ADDON_TYP_1 "TRSG_ADDON_TYP_1";
BA_ "LongName" SG_ 607 TRSG_ADDON_TYP_1 "Verkehrszeichen_Zusatz_Typ_1";
BA_ "SysSignalName" SG_ 607 TRSG_ADDON_TYP_1 "TRSG_ADDON_TYP_1";
BA_ "CompuMethodName" SG_ 607 TRSG_ADDON_TYP_2 "TRSG_ADDON_TYP";
BA_ "ISignalName" SG_ 607 TRSG_ADDON_TYP_2 "TRSG_ADDON_TYP_2";
BA_ "LongName" SG_ 607 TRSG_ADDON_TYP_2 "Verkehrszeichen_Zusatz_Typ_2";
BA_ "SysSignalName" SG_ 607 TRSG_ADDON_TYP_2 "TRSG_ADDON_TYP_2";
BA_ "CompuMethodName" SG_ 607 QUAL_RCOG_TRSG "QUAL_RCOG_TRSG";
BA_ "ISignalName" SG_ 607 QUAL_RCOG_TRSG "QUAL_RCOG_TRSG";
BA_ "LongName" SG_ 607 QUAL_RCOG_TRSG "Qualität_Erkennung_Verkehrszeichen";
BA_ "SysSignalName" SG_ 607 QUAL_RCOG_TRSG "QUAL_RCOG_TRSG";
BA_ "CompuMethodName" SG_ 607 TRSG_VL "TRSG_VL";
BA_ "ISignalName" SG_ 607 TRSG_VL "TRSG_VL";
BA_ "LongName" SG_ 607 TRSG_VL "Verkehrszeichen_Wert";
BA_ "SysSignalName" SG_ 607 TRSG_VL "TRSG_VL";
BA_ "CompuMethodName" SG_ 607 V_LIM_UN "V_LIM_UN";
BA_ "ISignalName" SG_ 607 V_LIM_UN "V_LIM_UN";
BA_ "LongName" SG_ 607 V_LIM_UN "Geschwindigkeit_Begrenzung_Einheit";
BA_ "SysSignalName" SG_ 607 V_LIM_UN "V_LIM_UN";
BA_ "CompuMethodName" SG_ 607 TRSG_PO_X "TRSG_PO_X";
BA_ "ISignalName" SG_ 607 TRSG_PO_X "TRSG_PO_X";
BA_ "LongName" SG_ 607 TRSG_PO_X "Verkehrszeichen_Position_X";
BA_ "SysSignalName" SG_ 607 TRSG_PO_X "TRSG_PO_X";
BA_ "CompuMethodName" SG_ 607 TRSG_PO_Y "TRSG_PO_Y";
BA_ "GenSigStartValue" SG_ 607 TRSG_PO_Y -25;
BA_ "ISignalName" SG_ 607 TRSG_PO_Y "TRSG_PO_Y";
BA_ "LongName" SG_ 607 TRSG_PO_Y "Verkehrszeichen_Position_Y";
BA_ "SysSignalName" SG_ 607 TRSG_PO_Y "TRSG_PO_Y";
BA_ "CompuMethodName" SG_ 607 TRSG_PO_Z "TRSG_PO_Z";
BA_ "ISignalName" SG_ 607 TRSG_PO_Z "TRSG_PO_Z";
BA_ "LongName" SG_ 607 TRSG_PO_Z "Verkehrszeichen_Position_Z";
BA_ "SysSignalName" SG_ 607 TRSG_PO_Z "TRSG_PO_Z";
BA_ "CompuMethodName" SG_ 607 TRSG_ST "TRSG_ST";
BA_ "ISignalName" SG_ 607 TRSG_ST "TRSG_ST";
BA_ "LongName" SG_ 607 TRSG_ST "Verkehrszeichen_Status";
BA_ "SysSignalName" SG_ 607 TRSG_ST "TRSG_ST";
BA_ "CompuMethodName" SG_ 370 RCPT_RQ_ACOU_KI "RCPT_RQ_ACOU_KI";
BA_ "ISignalName" SG_ 370 RCPT_RQ_ACOU_KI "RCPT_RQ_ACOU_KI";
BA_ "LongName" SG_ 370 RCPT_RQ_ACOU_KI "Quittierung_Anforderung_Akustik_Kombi";
BA_ "SysSignalName" SG_ 370 RCPT_RQ_ACOU_KI "RCPT_RQ_ACOU_KI";
BA_ "CompuMethodName" SG_ 916 ID2_RDA_INQY "ID2_RDA_INQY";
BA_ "ISignalName" SG_ 916 ID2_RDA_INQY "ID2_RDA_INQY";
BA_ "LongName" SG_ 916 ID2_RDA_INQY "ID2_RDA_Anfrage";
BA_ "SysSignalName" SG_ 916 ID2_RDA_INQY "ID2_RDA_INQY";
BA_ "CompuMethodName" SG_ 916 IDEN_RDA_INQY "IDEN_RDA_INQY";
BA_ "ISignalName" SG_ 916 IDEN_RDA_INQY "IDEN_RDA_INQY";
BA_ "LongName" SG_ 916 IDEN_RDA_INQY "Kennung_RDA_Anfrage";
BA_ "SysSignalName" SG_ 916 IDEN_RDA_INQY "IDEN_RDA_INQY";
BA_ "CompuMethodName" SG_ 916 UTDT_RDA_INQY_1 "UTDT_RDA_INQY_X";
BA_ "ISignalName" SG_ 916 UTDT_RDA_INQY_1 "UTDT_RDA_INQY_1";
BA_ "LongName" SG_ 916 UTDT_RDA_INQY_1 "Nutzdaten_RDA_Anfrage_1";
BA_ "SysSignalName" SG_ 916 UTDT_RDA_INQY_1 "UTDT_RDA_INQY_1";
BA_ "CompuMethodName" SG_ 916 UTDT_RDA_INQY_2 "UTDT_RDA_INQY_X";
BA_ "ISignalName" SG_ 916 UTDT_RDA_INQY_2 "UTDT_RDA_INQY_2";
BA_ "LongName" SG_ 916 UTDT_RDA_INQY_2 "Nutzdaten_RDA_Anfrage_2";
BA_ "SysSignalName" SG_ 916 UTDT_RDA_INQY_2 "UTDT_RDA_INQY_2";
BA_ "CompuMethodName" SG_ 916 UTDT_RDA_INQY_3 "UTDT_RDA_INQY_X";
BA_ "ISignalName" SG_ 916 UTDT_RDA_INQY_3 "UTDT_RDA_INQY_3";
BA_ "LongName" SG_ 916 UTDT_RDA_INQY_3 "Nutzdaten_RDA_Anfrage_3";
BA_ "SysSignalName" SG_ 916 UTDT_RDA_INQY_3 "UTDT_RDA_INQY_3";
BA_ "CompuMethodName" SG_ 916 UTDT_RDA_INQY_4 "UTDT_RDA_INQY_X";
BA_ "ISignalName" SG_ 916 UTDT_RDA_INQY_4 "UTDT_RDA_INQY_4";
BA_ "LongName" SG_ 916 UTDT_RDA_INQY_4 "Nutzdaten_RDA_Anfrage_4";
BA_ "SysSignalName" SG_ 916 UTDT_RDA_INQY_4 "UTDT_RDA_INQY_4";
BA_ "CompuMethodName" SG_ 916 UTDT_RDA_INQY_5 "UTDT_RDA_INQY_X";
BA_ "ISignalName" SG_ 916 UTDT_RDA_INQY_5 "UTDT_RDA_INQY_5";
BA_ "LongName" SG_ 916 UTDT_RDA_INQY_5 "Nutzdaten_RDA_Anfrage_5";
BA_ "SysSignalName" SG_ 916 UTDT_RDA_INQY_5 "UTDT_RDA_INQY_5";
BA_ "CompuMethodName" SG_ 916 UTDT_RDA_INQY_6 "UTDT_RDA_INQY_X";
BA_ "ISignalName" SG_ 916 UTDT_RDA_INQY_6 "UTDT_RDA_INQY_6";
BA_ "LongName" SG_ 916 UTDT_RDA_INQY_6 "Nutzdaten_RDA_Anfrage_6";
BA_ "SysSignalName" SG_ 916 UTDT_RDA_INQY_6 "UTDT_RDA_INQY_6";
BA_ "CompuMethodName" SG_ 808 T_SEC_COU_REL "UI_32_noIniVal_noDflVal_4294967295_1_0_noEnc_hasRng";
BA_ "ISignalName" SG_ 808 T_SEC_COU_REL "T_SEC_COU_REL";
BA_ "LongName" SG_ 808 T_SEC_COU_REL "Zeit_Sekunde_Zähler_Relativ";
BA_ "SysSignalName" SG_ 808 T_SEC_COU_REL "T_SEC_COU_REL";
BA_ "CompuMethodName" SG_ 808 T_DAY_COU_ABSL "UI_16_noIniVal_noDflVal_65535_1_0_noEnc_hasRng_2";
BA_ "ISignalName" SG_ 808 T_DAY_COU_ABSL "T_DAY_COU_ABSL";
BA_ "LongName" SG_ 808 T_DAY_COU_ABSL "Zeit_Tag_Zähler_Absolut";
BA_ "SysSignalName" SG_ 808 T_DAY_COU_ABSL "T_DAY_COU_ABSL";
BA_ "CompuMethodName" SG_ 349 RQ_DISP_DV_EMS "RQ_DISP_DV_EMS";
BA_ "ISignalName" SG_ 349 RQ_DISP_DV_EMS "RQ_DISP_DV_EMS";
BA_ "LongName" SG_ 349 RQ_DISP_DV_EMS "Anforderung_Anzeige_Fahrer_Nothalt";
BA_ "SysSignalName" SG_ 349 RQ_DISP_DV_EMS "RQ_DISP_DV_EMS";
BA_ "CompuMethodName" SG_ 349 RQ_ILE_EMS "RQ_ILE_EMS";
BA_ "ISignalName" SG_ 349 RQ_ILE_EMS "RQ_ILE_EMS";
BA_ "LongName" SG_ 349 RQ_ILE_EMS "Anforderung_Innenlichteinheit_Nothalt";
BA_ "SysSignalName" SG_ 349 RQ_ILE_EMS "RQ_ILE_EMS";
BA_ "CompuMethodName" SG_ 349 RQ_CLSY_EMS "RQ_CLSY_EMS";
BA_ "ISignalName" SG_ 349 RQ_CLSY_EMS "RQ_CLSY_EMS";
BA_ "LongName" SG_ 349 RQ_CLSY_EMS "Anforderung_Zentralverriegelung_Nothalt";
BA_ "SysSignalName" SG_ 349 RQ_CLSY_EMS "RQ_CLSY_EMS";
BA_ "CompuMethodName" SG_ 891 RLS_COOL_HVSTO "RLS_COOL_HVSTO";
BA_ "ISignalName" SG_ 891 RLS_COOL_HVSTO "RLS_COOL_HVSTO";
BA_ "LongName" SG_ 891 RLS_COOL_HVSTO "Freigabe_Kühlung_Hochvoltspeicher";
BA_ "SysSignalName" SG_ 891 RLS_COOL_HVSTO "RLS_COOL_HVSTO";
BA_ "CompuMethodName" SG_ 891 RQ_PAIC "RQ_PAIC";
BA_ "ISignalName" SG_ 891 RQ_PAIC "RQ_PAIC";
BA_ "LongName" SG_ 891 RQ_PAIC "Anforderung_Standklima";
BA_ "SysSignalName" SG_ 891 RQ_PAIC "RQ_PAIC";
BA_ "CompuMethodName" SG_ 891 RQ_CSOV_HVSTO "RQ_CSOV_HVSTO";
BA_ "ISignalName" SG_ 891 RQ_CSOV_HVSTO "RQ_CSOV_HVSTO";
BA_ "LongName" SG_ 891 RQ_CSOV_HVSTO "Anforderung_Kälteabsperrventil_Hochvoltspeicher";
BA_ "SysSignalName" SG_ 891 RQ_CSOV_HVSTO "RQ_CSOV_HVSTO";
BA_ "CompuMethodName" SG_ 891 ST_FRT_AC "ST_FRT_AC";
BA_ "ISignalName" SG_ 891 ST_FRT_AC "ST_FRT_AC";
BA_ "LongName" SG_ 891 ST_FRT_AC "Status_Front_AC";
BA_ "SysSignalName" SG_ 891 ST_FRT_AC "ST_FRT_AC";
BA_ "CompuMethodName" SG_ 891 AVL_PWR_ACCM "PWR_ACCM";
BA_ "ISignalName" SG_ 891 AVL_PWR_ACCM "AVL_PWR_ACCM";
BA_ "LongName" SG_ 891 AVL_PWR_ACCM "Ist_Leistung_Klimakompressor";
BA_ "SysSignalName" SG_ 891 AVL_PWR_ACCM "AVL_PWR_ACCM";
BA_ "CompuMethodName" SG_ 891 AVL_I_EKK "AVL_I_EKK";
BA_ "ISignalName" SG_ 891 AVL_I_EKK "AVL_I_EKK";
BA_ "LongName" SG_ 891 AVL_I_EKK "Ist_Strom_EKK";
BA_ "SysSignalName" SG_ 891 AVL_I_EKK "AVL_I_EKK";
BA_ "CompuMethodName" SG_ 891 EkmvCompressorRpm "EkmvCompressorRpm";
BA_ "ISignalName" SG_ 891 EkmvCompressorRpm "EkmvCompressorRpm";
BA_ "LongName" SG_ 891 EkmvCompressorRpm "EkmvCompressorRpm";
BA_ "SysSignalName" SG_ 891 EkmvCompressorRpm "EkmvCompressorRpm";
BA_ "CompuMethodName" SG_ 735 RLS_PWR_COOL_BT_AIC "INQY_PWR_6300";
BA_ "ISignalName" SG_ 735 RLS_PWR_COOL_BT_AIC "RLS_PWR_COOL_BT_AIC";
BA_ "LongName" SG_ 735 RLS_PWR_COOL_BT_AIC "Freigabe_Leistung_Kühlung_Batterie_Klima";
BA_ "SysSignalName" SG_ 735 RLS_PWR_COOL_BT_AIC "RLS_PWR_COOL_BT_AIC";
BA_ "CompuMethodName" SG_ 735 RLS_PWR_COOL_BT_FAST_AIC "INQY_PWR_6300";
BA_ "ISignalName" SG_ 735 RLS_PWR_COOL_BT_FAST_AIC "RLS_PWR_COOL_BT_FAST_AIC";
BA_ "LongName" SG_ 735 RLS_PWR_COOL_BT_FAST_AIC "Freigabe_Leistung_Kühlung_Batterie_Schnell_Klima";
BA_ "SysSignalName" SG_ 735 RLS_PWR_COOL_BT_FAST_AIC "RLS_PWR_COOL_BT_FAST_AIC";
BA_ "CompuMethodName" SG_ 735 RLS_PWR_DFR_AIC "INQY_PWR_102300";
BA_ "ISignalName" SG_ 735 RLS_PWR_DFR_AIC "RLS_PWR_DFR_AIC";
BA_ "LongName" SG_ 735 RLS_PWR_DFR_AIC "Freigabe_Leistung_Defrost_Klima";
BA_ "SysSignalName" SG_ 735 RLS_PWR_DFR_AIC "RLS_PWR_DFR_AIC";
BA_ "CompuMethodName" SG_ 735 RLS_PWR_FOG_AIC "INQY_PWR_102300";
BA_ "ISignalName" SG_ 735 RLS_PWR_FOG_AIC "RLS_PWR_FOG_AIC";
BA_ "LongName" SG_ 735 RLS_PWR_FOG_AIC "release_power_fog-up_air-conditioning";
BA_ "SysSignalName" SG_ 735 RLS_PWR_FOG_AIC "RLS_PWR_FOG_AIC";
BA_ "CompuMethodName" SG_ 741 RLS_PWR_CLDWN_AIC "INQY_PWR_6300";
BA_ "ISignalName" SG_ 741 RLS_PWR_CLDWN_AIC "RLS_PWR_CLDWN_AIC";
BA_ "LongName" SG_ 741 RLS_PWR_CLDWN_AIC "Freigabe_Leistung_Abkühlung_Klima";
BA_ "SysSignalName" SG_ 741 RLS_PWR_CLDWN_AIC "RLS_PWR_CLDWN_AIC";
BA_ "CompuMethodName" SG_ 741 RLS_PWR_HTUP_AIC "INQY_PWR_6300";
BA_ "ISignalName" SG_ 741 RLS_PWR_HTUP_AIC "RLS_PWR_HTUP_AIC";
BA_ "LongName" SG_ 741 RLS_PWR_HTUP_AIC "Freigabe_Leistung_Aufheizung_Klima";
BA_ "SysSignalName" SG_ 741 RLS_PWR_HTUP_AIC "RLS_PWR_HTUP_AIC";
BA_ "CompuMethodName" SG_ 741 RLS_PWR_CNSR_COOL_AIC "INQY_PWR_6300";
BA_ "ISignalName" SG_ 741 RLS_PWR_CNSR_COOL_AIC "RLS_PWR_CNSR_COOL_AIC";
BA_ "LongName" SG_ 741 RLS_PWR_CNSR_COOL_AIC "Freigabe_Leistung_Erhaltung_Kühlung_Klima";
BA_ "SysSignalName" SG_ 741 RLS_PWR_CNSR_COOL_AIC "RLS_PWR_CNSR_COOL_AIC";
BA_ "CompuMethodName" SG_ 741 RLS_PWR_CNSR_HT_AIC "INQY_PWR_6300";
BA_ "ISignalName" SG_ 741 RLS_PWR_CNSR_HT_AIC "RLS_PWR_CNSR_HT_AIC";
BA_ "LongName" SG_ 741 RLS_PWR_CNSR_HT_AIC "Freigabe_Leistung_Erhaltung_Heizung_Klima";
BA_ "SysSignalName" SG_ 741 RLS_PWR_CNSR_HT_AIC "RLS_PWR_CNSR_HT_AIC";
BA_ "CompuMethodName" SG_ 741 RLS_PWR_PRECOND_INO_AIC "INQY_PWR_6300";
BA_ "ISignalName" SG_ 741 RLS_PWR_PRECOND_INO_AIC "RLS_PWR_PRECOND_INO_AIC";
BA_ "LongName" SG_ 741 RLS_PWR_PRECOND_INO_AIC "Freigabe_Leistung_Vorkonditionierung_Innenraum_Klima";
BA_ "SysSignalName" SG_ 741 RLS_PWR_PRECOND_INO_AIC "RLS_PWR_PRECOND_INO_AIC";
BA_ "CompuMethodName" SG_ 968 SYNCN_RNG_MAP_INFO "SYNCN_RNG_MAP_INFO";
BA_ "ISignalName" SG_ 968 SYNCN_RNG_MAP_INFO "SYNCN_RNG_MAP_INFO";
BA_ "LongName" SG_ 968 SYNCN_RNG_MAP_INFO "Synchronisation_Reichweite_Karte_Information";
BA_ "SysSignalName" SG_ 968 SYNCN_RNG_MAP_INFO "SYNCN_RNG_MAP_INFO";
BA_ "CompuMethodName" SG_ 968 RNG_MAP_MIN_VL "RNG_MAP_MIN_VL";
BA_ "ISignalName" SG_ 968 RNG_MAP_MIN_VL "RNG_MAP_MIN_VL";
BA_ "LongName" SG_ 968 RNG_MAP_MIN_VL "Reichweite_Karte_Minimal_Wert";
BA_ "SysSignalName" SG_ 968 RNG_MAP_MIN_VL "RNG_MAP_MIN_VL";
BA_ "CompuMethodName" SG_ 968 RNG_MAP_MAX_VL "RNG_MAP_MAX_VL";
BA_ "ISignalName" SG_ 968 RNG_MAP_MAX_VL "RNG_MAP_MAX_VL";
BA_ "LongName" SG_ 968 RNG_MAP_MAX_VL "Reichweite_Karte_Maximal_Wert";
BA_ "SysSignalName" SG_ 968 RNG_MAP_MAX_VL "RNG_MAP_MAX_VL";
BA_ "CompuMethodName" SG_ 968 HG_DT_GPS_SIG "HG_DT_GPS_SIG";
BA_ "GenSigStartValue" SG_ 968 HG_DT_GPS_SIG 5000;
BA_ "ISignalName" SG_ 968 HG_DT_GPS_SIG "HG_DT_GPS_SIG";
BA_ "LongName" SG_ 968 HG_DT_GPS_SIG "Höhe_Daten_GPS_Signal";
BA_ "SysSignalName" SG_ 968 HG_DT_GPS_SIG "HG_DT_GPS_SIG";
BA_ "CompuMethodName" SG_ 968 DIST_VEH_GPS_SIG_V_COR "DIST_VEH_GPS_SIG_V_COR";
BA_ "ISignalName" SG_ 968 DIST_VEH_GPS_SIG_V_COR "DIST_VEH_GPS_SIG_V_COR";
BA_ "LongName" SG_ 968 DIST_VEH_GPS_SIG_V_COR "Distanz_Fahrzeug_GPS_Signal_Geschwindigkeit_Korrektur";
BA_ "SysSignalName" SG_ 968 DIST_VEH_GPS_SIG_V_COR "DIST_VEH_GPS_SIG_V_COR";
BA_ "CompuMethodName" SG_ 761 AVL_TORQ_ACCM "AVL_TORQ_ACCM";
BA_ "ISignalName" SG_ 761 AVL_TORQ_ACCM "AVL_TORQ_ACCM";
BA_ "LongName" SG_ 761 AVL_TORQ_ACCM "Ist_Drehmoment_Klimakompressor";
BA_ "SysSignalName" SG_ 761 AVL_TORQ_ACCM "AVL_TORQ_ACCM";
BA_ "CompuMethodName" SG_ 761 RQ_HTFL_AIC "RQ_HTFL_AIC";
BA_ "ISignalName" SG_ 761 RQ_HTFL_AIC "RQ_HTFL_AIC";
BA_ "LongName" SG_ 761 RQ_HTFL_AIC "Anforderung_Wärmestrom_Klima";
BA_ "SysSignalName" SG_ 761 RQ_HTFL_AIC "RQ_HTFL_AIC";
BA_ "CompuMethodName" SG_ 761 AVL_SETQ_EFAN_AIC "AVL_SETQ_EFAN_AIC";
BA_ "ISignalName" SG_ 761 AVL_SETQ_EFAN_AIC "AVL_SETQ_EFAN_AIC";
BA_ "LongName" SG_ 761 AVL_SETQ_EFAN_AIC "Ist_Stellgröße_Elektrolüfter_Klima";
BA_ "SysSignalName" SG_ 761 AVL_SETQ_EFAN_AIC "AVL_SETQ_EFAN_AIC";
BA_ "CompuMethodName" SG_ 761 CTR_RDI_AIC "CTR_RDI_AIC";
BA_ "ISignalName" SG_ 761 CTR_RDI_AIC "CTR_RDI_AIC";
BA_ "LongName" SG_ 761 CTR_RDI_AIC "Steuerung_Bereitschaft_Klima";
BA_ "SysSignalName" SG_ 761 CTR_RDI_AIC "CTR_RDI_AIC";
BA_ "CompuMethodName" SG_ 761 ST_PHTR_ENGSTA_DRV "ST_PHTR_ENGSTA_DRV";
BA_ "ISignalName" SG_ 761 ST_PHTR_ENGSTA_DRV "ST_PHTR_ENGSTA_DRV";
BA_ "LongName" SG_ 761 ST_PHTR_ENGSTA_DRV "Status_Standheizung_Motorstart_Antrieb";
BA_ "SysSignalName" SG_ 761 ST_PHTR_ENGSTA_DRV "ST_PHTR_ENGSTA_DRV";
BA_ "CompuMethodName" SG_ 761 AVL_RQMT_HTFL "AVL_RQMT_HTFL";
BA_ "ISignalName" SG_ 761 AVL_RQMT_HTFL "AVL_RQMT_HTFL";
BA_ "LongName" SG_ 761 AVL_RQMT_HTFL "Ist_Bedarf_Wärmestrom";
BA_ "SysSignalName" SG_ 761 AVL_RQMT_HTFL "AVL_RQMT_HTFL";
BA_ "CompuMethodName" SG_ 761 AVL_SETQ_LOW_TEMP_WAP_AIC "AVL_SETQ_LOW_TEMP_WAP_AIC";
BA_ "ISignalName" SG_ 761 AVL_SETQ_LOW_TEMP_WAP_AIC "AVL_SETQ_LOW_TEMP_WAP_AIC";
BA_ "LongName" SG_ 761 AVL_SETQ_LOW_TEMP_WAP_AIC "Ist_Stellgröße_Low_Temperatur_Wasserpumpe_Klima";
BA_ "SysSignalName" SG_ 761 AVL_SETQ_LOW_TEMP_WAP_AIC "AVL_SETQ_LOW_TEMP_WAP_AIC";
BA_ "CompuMethodName" SG_ 512 FRC_AIC_PWR_RETA "FRC_AIC_PWR_RETA";
BA_ "ISignalName" SG_ 512 FRC_AIC_PWR_RETA "FRC_AIC_PWR_RETA";
BA_ "LongName" SG_ 512 FRC_AIC_PWR_RETA "Prognose_Klima_Leistung_Halten";
BA_ "SysSignalName" SG_ 512 FRC_AIC_PWR_RETA "FRC_AIC_PWR_RETA";
BA_ "CompuMethodName" SG_ 512 FRC_AIC_ENERG_CLDWN_HTUP "FRC_AIC_ENERG_CLDWN_HTUP";
BA_ "ISignalName" SG_ 512 FRC_AIC_ENERG_CLDWN_HTUP "FRC_AIC_ENERG_CLDWN_HTUP";
BA_ "LongName" SG_ 512 FRC_AIC_ENERG_CLDWN_HTUP "Prognose_Klima_Energie_Abkühlung_Aufheizung";
BA_ "SysSignalName" SG_ 512 FRC_AIC_ENERG_CLDWN_HTUP "FRC_AIC_ENERG_CLDWN_HTUP";
BA_ "CompuMethodName" SG_ 512 FBK_OP_AIC "FBK_OP_AIC";
BA_ "ISignalName" SG_ 512 FBK_OP_AIC "FBK_OP_AIC";
BA_ "LongName" SG_ 512 FBK_OP_AIC "Rückmeldung_Bedienung_Klima";
BA_ "SysSignalName" SG_ 512 FBK_OP_AIC "FBK_OP_AIC";
BA_ "CompuMethodName" SG_ 512 MUX_RQ_AIC_1 "MUX_RQ_AIC_1";
BA_ "ISignalName" SG_ 512 MUX_RQ_AIC_1 "MUX_RQ_AIC_1";
BA_ "LongName" SG_ 512 MUX_RQ_AIC_1 "Multiplexer_Anforderung_Klima_1";
BA_ "SysSignalName" SG_ 512 MUX_RQ_AIC_1 "MUX_RQ_AIC_1";
BA_ "CompuMethodName" SG_ 512 ActualValueThermicCoolingUrgency "ActualValueThermicCoolingUrgency";
BA_ "ISignalName" SG_ 512 ActualValueThermicCoolingUrgency "ActualValueThermicCoolingUrgencyInterior";
BA_ "LongName" SG_ 512 ActualValueThermicCoolingUrgency "ActualValueThermicCoolingUrgencyInterior";
BA_ "SysSignalName" SG_ 512 ActualValueThermicCoolingUrgency "ActualValueThermicCoolingUrgencyInterior";
BA_ "SystemSignalLongSymbol" SG_ 512 ActualValueThermicCoolingUrgency "ActualValueThermicCoolingUrgencyInterior";
BA_ "CompuMethodName" SG_ 665 CTR_CSOV_EVA "CTR_COLPP_HVBTC_LIM";
BA_ "ISignalName" SG_ 665 CTR_CSOV_EVA "CTR_CSOV_EVA";
BA_ "LongName" SG_ 665 CTR_CSOV_EVA "control_cold-shut-off-valve_evaporator";
BA_ "SysSignalName" SG_ 665 CTR_CSOV_EVA "CTR_CSOV_EVA";
BA_ "CompuMethodName" SG_ 160 TAR_MOD_SHFT_DVCH "TAR_MOD_SHFT_DVCH";
BA_ "ISignalName" SG_ 160 TAR_MOD_SHFT_DVCH "TAR_MOD_SHFT_DVCH";
BA_ "LongName" SG_ 160 TAR_MOD_SHFT_DVCH "target_mode_shift_drivers-choice";
BA_ "SysSignalName" SG_ 160 TAR_MOD_SHFT_DVCH "TAR_MOD_SHFT_DVCH";
BA_ "CompuMethodName" SG_ 258 CRC_RQ_WBK_ACOU "CRC8";
BA_ "ISignalName" SG_ 258 CRC_RQ_WBK_ACOU "CRC_RQ_WBK_ACOU";
BA_ "LongName" SG_ 258 CRC_RQ_WBK_ACOU "CRC_Anforderung_Warnbremskoordinator_Akustik";
BA_ "SysSignalName" SG_ 258 CRC_RQ_WBK_ACOU "CRC_RQ_WBK_ACOU";
BA_ "CompuMethodName" SG_ 258 ALIV_RQ_WBK_ACOU "ALIV_4_BIT_Unsigned_Integer";
BA_ "ISignalName" SG_ 258 ALIV_RQ_WBK_ACOU "ALIV_RQ_WBK_ACOU";
BA_ "LongName" SG_ 258 ALIV_RQ_WBK_ACOU "Alive_Anforderung_Warnbremskoordinator_Akustik";
BA_ "SysSignalName" SG_ 258 ALIV_RQ_WBK_ACOU "ALIV_RQ_WBK_ACOU";
BA_ "CompuMethodName" SG_ 258 CHL_RQ_WBK_ACOU "CHL_4_UInt";
BA_ "ISignalName" SG_ 258 CHL_RQ_WBK_ACOU "CHL_RQ_WBK_ACOU";
BA_ "LongName" SG_ 258 CHL_RQ_WBK_ACOU "CHL_Anforderung_Warnbremskoordinator_Akustik";
BA_ "SysSignalName" SG_ 258 CHL_RQ_WBK_ACOU "CHL_RQ_WBK_ACOU";
BA_ "CompuMethodName" SG_ 258 RQ_SOU "RQ_SOU";
BA_ "ISignalName" SG_ 258 RQ_SOU "RQ_SOU";
BA_ "LongName" SG_ 258 RQ_SOU "Anforderung_Ton";
BA_ "SysSignalName" SG_ 258 RQ_SOU "RQ_SOU";
BA_ "ISignalName" SG_ 258 RQ_WBK_ACOU_dummy_20_31 "RQ_WBK_ACOU_dummy_20_31";
BA_ "LongName" SG_ 258 RQ_WBK_ACOU_dummy_20_31 "RQ_WBK_ACOU_dummy_20_31";
BA_ "SysSignalName" SG_ 258 RQ_WBK_ACOU_dummy_20_31 "RQ_WBK_ACOU_dummy_20_31";
BA_ "ISignalName" SG_ 258 RQ_WBK_ACOU_dummy_32_63 "RQ_WBK_ACOU_dummy_32_63";
BA_ "LongName" SG_ 258 RQ_WBK_ACOU_dummy_32_63 "RQ_WBK_ACOU_dummy_32_63";
BA_ "SysSignalName" SG_ 258 RQ_WBK_ACOU_dummy_32_63 "RQ_WBK_ACOU_dummy_32_63";
BA_ "CompuMethodName" SG_ 261 CRC_RQ_WBK_DISP "CRC8";
BA_ "ISignalName" SG_ 261 CRC_RQ_WBK_DISP "CRC_RQ_WBK_DISP";
BA_ "LongName" SG_ 261 CRC_RQ_WBK_DISP "CRC_Anforderung_Warnbremskoordinator_Anzeige";
BA_ "SysSignalName" SG_ 261 CRC_RQ_WBK_DISP "CRC_RQ_WBK_DISP";
BA_ "CompuMethodName" SG_ 261 ALIV_RQ_WBK_DISP "ALIV_4_BIT_Unsigned_Integer";
BA_ "ISignalName" SG_ 261 ALIV_RQ_WBK_DISP "ALIV_RQ_WBK_DISP";
BA_ "LongName" SG_ 261 ALIV_RQ_WBK_DISP "Alive_Anforderung_Warnbremskoordinator_Anzeige";
BA_ "SysSignalName" SG_ 261 ALIV_RQ_WBK_DISP "ALIV_RQ_WBK_DISP";
BA_ "CompuMethodName" SG_ 261 CHL_RQ_WBK_DISP "CHL_4_UInt";
BA_ "ISignalName" SG_ 261 CHL_RQ_WBK_DISP "CHL_RQ_WBK_DISP";
BA_ "LongName" SG_ 261 CHL_RQ_WBK_DISP "CHL_Anforderung_Warnbremskoordinator_Anzeige";
BA_ "SysSignalName" SG_ 261 CHL_RQ_WBK_DISP "CHL_RQ_WBK_DISP";
BA_ "CompuMethodName" SG_ 261 RQ_DISP_SYM "RQ_DISP_SYM";
BA_ "ISignalName" SG_ 261 RQ_DISP_SYM "RQ_DISP_SYM";
BA_ "LongName" SG_ 261 RQ_DISP_SYM "Anforderung_Anzeige_Symbol";
BA_ "SysSignalName" SG_ 261 RQ_DISP_SYM "RQ_DISP_SYM";
BA_ "CompuMethodName" SG_ 261 RQ_SYMAB "RQ_SYMAB";
BA_ "ISignalName" SG_ 261 RQ_SYMAB "RQ_SYMAB";
BA_ "LongName" SG_ 261 RQ_SYMAB "Anforderung_Symbolattribut";
BA_ "SysSignalName" SG_ 261 RQ_SYMAB "RQ_SYMAB";
BA_ "ISignalName" SG_ 261 RQ_WBK_DISP_dummy_28_31 "RQ_WBK_DISP_dummy_28_31";
BA_ "LongName" SG_ 261 RQ_WBK_DISP_dummy_28_31 "RQ_WBK_DISP_dummy_28_31";
BA_ "SysSignalName" SG_ 261 RQ_WBK_DISP_dummy_28_31 "RQ_WBK_DISP_dummy_28_31";
BA_ "ISignalName" SG_ 261 RQ_WBK_DISP_dummy_32_63 "RQ_WBK_DISP_dummy_32_63";
BA_ "LongName" SG_ 261 RQ_WBK_DISP_dummy_32_63 "RQ_WBK_DISP_dummy_32_63";
BA_ "SysSignalName" SG_ 261 RQ_WBK_DISP_dummy_32_63 "RQ_WBK_DISP_dummy_32_63";
BA_ "CompuMethodName" SG_ 1096 RequestKeyFunction "RequestKeyFunction";
BA_ "ISignalName" SG_ 1096 RequestKeyFunction "RequestKeyFunction";
BA_ "LongName" SG_ 1096 RequestKeyFunction "RequestKeyFunction";
BA_ "SysSignalName" SG_ 1096 RequestKeyFunction "RequestKeyFunction";
BA_ "CompuMethodName" SG_ 1096 RequestKeyId "RequestKeyId";
BA_ "ISignalName" SG_ 1096 RequestKeyId "RequestKeyId";
BA_ "LongName" SG_ 1096 RequestKeyId "RequestKeyId";
BA_ "SysSignalName" SG_ 1096 RequestKeyId "RequestKeyId";
BA_ "CompuMethodName" SG_ 464 CRC_SAFG_PT "CRC8";
BA_ "ISignalName" SG_ 464 CRC_SAFG_PT "CRC_SAFG_PT";
BA_ "LongName" SG_ 464 CRC_SAFG_PT "CRC_Absicherung_Antriebsstrang";
BA_ "SysSignalName" SG_ 464 CRC_SAFG_PT "CRC_SAFG_PT";
BA_ "CompuMethodName" SG_ 464 ALIV_SAFG_PT "ALIV_4_BIT_Unsigned_Integer";
BA_ "ISignalName" SG_ 464 ALIV_SAFG_PT "ALIV_SAFG_PT";
BA_ "LongName" SG_ 464 ALIV_SAFG_PT "Alive_Absicherung_Antriebsstrang";
BA_ "SysSignalName" SG_ 464 ALIV_SAFG_PT "ALIV_SAFG_PT";
BA_ "ISignalName" SG_ 464 SAFG_PT_dummy_12_15 "SAFG_PT_dummy_12_15";
BA_ "LongName" SG_ 464 SAFG_PT_dummy_12_15 "SAFG_PT_dummy_12_15";
BA_ "SysSignalName" SG_ 464 SAFG_PT_dummy_12_15 "SAFG_PT_dummy_12_15";
BA_ "ISignalName" SG_ 464 SAFG_PT_dummy_16_47 "SAFG_PT_dummy_16_47";
BA_ "LongName" SG_ 464 SAFG_PT_dummy_16_47 "SAFG_PT_dummy_16_47";
BA_ "SysSignalName" SG_ 464 SAFG_PT_dummy_16_47 "SAFG_PT_dummy_16_47";
BA_ "CompuMethodName" SG_ 464 TORQ_MIN_LAY_2_MOT_1 "TORQ_MIN_LAY_2_MOT";
BA_ "GenSigStartValue" SG_ 464 TORQ_MIN_LAY_2_MOT_1 -500;
BA_ "ISignalName" SG_ 464 TORQ_MIN_LAY_2_MOT_1 "TORQ_MIN_LAY_2_MOT_1";
BA_ "LongName" SG_ 464 TORQ_MIN_LAY_2_MOT_1 "Drehmoment_Minimal_Ebene_2_E-Motor_1";
BA_ "SysSignalName" SG_ 464 TORQ_MIN_LAY_2_MOT_1 "TORQ_MIN_LAY_2_MOT_1";
BA_ "CompuMethodName" SG_ 464 TORQ_MAX_LAY_2_MOT_1 "TORQ_MAX_LAY_2_MOT";
BA_ "ISignalName" SG_ 464 TORQ_MAX_LAY_2_MOT_1 "TORQ_MAX_LAY_2_MOT_1";
BA_ "LongName" SG_ 464 TORQ_MAX_LAY_2_MOT_1 "Drehmoment_Maximal_Ebene_2_E-Motor_1";
BA_ "SysSignalName" SG_ 464 TORQ_MAX_LAY_2_MOT_1 "TORQ_MAX_LAY_2_MOT_1";
BA_ "CompuMethodName" SG_ 482 STU_8_BYTE "STU_8_BYTE";
BA_ "ISignalName" SG_ 482 STU_8_BYTE "STU_8_BYTE";
BA_ "LongName" SG_ 482 STU_8_BYTE "Signatur_8_Byte";
BA_ "SysSignalName" SG_ 482 STU_8_BYTE "STU_8_BYTE";
BA_ "CompuMethodName" SG_ 786 TR_AUTOM_SER_CALL_TS "TR_AUTOM_SER_CALL_TS";
BA_ "ISignalName" SG_ 786 TR_AUTOM_SER_CALL_TS "TR_AUTOM_SER_CALL_TS";
BA_ "LongName" SG_ 786 TR_AUTOM_SER_CALL_TS "Trigger_Automatischer_Service_Call_Teleservice";
BA_ "SysSignalName" SG_ 786 TR_AUTOM_SER_CALL_TS "TR_AUTOM_SER_CALL_TS";
BA_ "CompuMethodName" SG_ 786 ST_CBS_TS "ST_CBS_TS";
BA_ "ISignalName" SG_ 786 ST_CBS_TS "ST_CBS_TS";
BA_ "LongName" SG_ 786 ST_CBS_TS "Status_CBS_Teleservice";
BA_ "SysSignalName" SG_ 786 ST_CBS_TS "ST_CBS_TS";
BA_ "CompuMethodName" SG_ 933 DSTN_SLRDI_GLB "DSTN_SLRDI_GLB";
BA_ "ISignalName" SG_ 933 DSTN_SLRDI_GLB "DSTN_SLRDI_GLB";
BA_ "LongName" SG_ 933 DSTN_SLRDI_GLB "Ziel_Schlafbereitschaft_Global";
BA_ "SysSignalName" SG_ 933 DSTN_SLRDI_GLB "DSTN_SLRDI_GLB";
BA_ "CompuMethodName" SG_ 933 CTR_SLRDI_GLB "CTR_SLRDI_GLB";
BA_ "ISignalName" SG_ 933 CTR_SLRDI_GLB "CTR_SLRDI_GLB";
BA_ "LongName" SG_ 933 CTR_SLRDI_GLB "Steuerung_Schlafbereitschaft_Global";
BA_ "SysSignalName" SG_ 933 CTR_SLRDI_GLB "CTR_SLRDI_GLB";
BA_ "CompuMethodName" SG_ 933 CTR_FSL "CTR_FSL";
BA_ "ISignalName" SG_ 933 CTR_FSL "CTR_FSL";
BA_ "LongName" SG_ 933 CTR_FSL "Steuerung_Zwangseinschlafen";
BA_ "SysSignalName" SG_ 933 CTR_FSL "CTR_FSL";
BA_ "CompuMethodName" SG_ 933 CTR_SLP_BUS "CTR_SLP_BUS";
BA_ "ISignalName" SG_ 933 CTR_SLP_BUS "CTR_SLP_BUS";
BA_ "LongName" SG_ 933 CTR_SLP_BUS "Steuerung_Sleep_Bus";
BA_ "SysSignalName" SG_ 933 CTR_SLP_BUS "CTR_SLP_BUS";
BA_ "CompuMethodName" SG_ 933 CTR_SNW "CTR_SNW";
BA_ "ISignalName" SG_ 933 CTR_SNW "CTR_SNW";
BA_ "LongName" SG_ 933 CTR_SNW "Steuerung_Teil-Netzwerk";
BA_ "SysSignalName" SG_ 933 CTR_SNW "CTR_SNW";
BA_ "CompuMethodName" SG_ 843 ALIV_COU_SM_DR "Aliv_4";
BA_ "ISignalName" SG_ 843 ALIV_COU_SM_DR "ALIV_COU_SM_DR";
BA_ "LongName" SG_ 843 ALIV_COU_SM_DR "Alive_Zähler_SM_FA";
BA_ "SysSignalName" SG_ 843 ALIV_COU_SM_DR "ALIV_COU_SM_DR";
BA_ "CompuMethodName" SG_ 843 ST_SBIL_DR "ENUM_2_1_1_3_noQuant_noOffs_typeBitField_noRng";
BA_ "ISignalName" SG_ 843 ST_SBIL_DR "ST_SBIL_DR";
BA_ "LongName" SG_ 843 ST_SBIL_DR "Status_Sitzlehnenverriegelung_FA";
BA_ "SysSignalName" SG_ 843 ST_SBIL_DR "ST_SBIL_DR";
BA_ "CompuMethodName" SG_ 845 ALIV_COU_SM_PS "Aliv_4";
BA_ "ISignalName" SG_ 845 ALIV_COU_SM_PS "ALIV_COU_SM_PS";
BA_ "LongName" SG_ 845 ALIV_COU_SM_PS "Alive_Zähler_SM_BF";
BA_ "SysSignalName" SG_ 845 ALIV_COU_SM_PS "ALIV_COU_SM_PS";
BA_ "CompuMethodName" SG_ 845 ST_SBIL_PS "ENUM_2_1_1_3_noQuant_noOffs_typeBitField_noRng";
BA_ "ISignalName" SG_ 845 ST_SBIL_PS "ST_SBIL_PS";
BA_ "LongName" SG_ 845 ST_SBIL_PS "Status_Sitzlehnenverriegelung_BF";
BA_ "SysSignalName" SG_ 845 ST_SBIL_PS "ST_SBIL_PS";
BA_ "CompuMethodName" SG_ 740 ST_TRAI "ST_TRAI";
BA_ "ISignalName" SG_ 740 ST_TRAI "ST_TRAI";
BA_ "LongName" SG_ 740 ST_TRAI "Status_Anhänger";
BA_ "SysSignalName" SG_ 740 ST_TRAI "ST_TRAI";
BA_ "CompuMethodName" SG_ 740 ST_DI_DF_TRAI "ST_DI_DF_TRAI";
BA_ "ISignalName" SG_ 740 ST_DI_DF_TRAI "ST_DI_DF_TRAI";
BA_ "LongName" SG_ 740 ST_DI_DF_TRAI "Status_Blinker_Defekt_Anhänger";
BA_ "SysSignalName" SG_ 740 ST_DI_DF_TRAI "ST_DI_DF_TRAI";
BA_ "CompuMethodName" SG_ 740 ST_SYNCN_HAZWCL_TRAI "ST_SYNCN_HAZWCL_TRAI";
BA_ "ISignalName" SG_ 740 ST_SYNCN_HAZWCL_TRAI "ST_SYNCN_HAZWCL_TRAI";
BA_ "LongName" SG_ 740 ST_SYNCN_HAZWCL_TRAI "Status_Synchronisation_Warnblinktakt_Anhänger";
BA_ "SysSignalName" SG_ 740 ST_SYNCN_HAZWCL_TRAI "ST_SYNCN_HAZWCL_TRAI";
BA_ "ISignalName" SG_ 740 STAT_ANHAENGER_dummy_7_7 "STAT_ANHAENGER_dummy_7_7";
BA_ "LongName" SG_ 740 STAT_ANHAENGER_dummy_7_7 "STAT_ANHAENGER_dummy_7_7";
BA_ "SysSignalName" SG_ 740 STAT_ANHAENGER_dummy_7_7 "STAT_ANHAENGER_dummy_7_7";
BA_ "CompuMethodName" SG_ 740 ST_RFLI_DF_TRAI "ST_RFLI_DF_TRAI";
BA_ "ISignalName" SG_ 740 ST_RFLI_DF_TRAI "ST_RFLI_DF_TRAI";
BA_ "LongName" SG_ 740 ST_RFLI_DF_TRAI "Status_Nebelschlußleuchte_Defekt_Anhänger";
BA_ "SysSignalName" SG_ 740 ST_RFLI_DF_TRAI "ST_RFLI_DF_TRAI";
BA_ "CompuMethodName" SG_ 740 ST_PO_AHV "ST_PO_AHV_SigEncod";
BA_ "ISignalName" SG_ 740 ST_PO_AHV "ST_PO_AHV";
BA_ "LongName" SG_ 740 ST_PO_AHV "Status_Position_AHV";
BA_ "SysSignalName" SG_ 740 ST_PO_AHV "ST_PO_AHV";
BA_ "CompuMethodName" SG_ 740 StatusBikeCarrier "StatusBikeCarrier";
BA_ "ISignalName" SG_ 740 StatusBikeCarrier "StatusBikeCarrier";
BA_ "LongName" SG_ 740 StatusBikeCarrier "StatusBikeCarrier";
BA_ "SysSignalName" SG_ 740 StatusBikeCarrier "StatusBikeCarrier";
BA_ "ISignalName" SG_ 740 STAT_ANHAENGER_dummy_15_15 "STAT_ANHAENGER_dummy_15_15";
BA_ "LongName" SG_ 740 STAT_ANHAENGER_dummy_15_15 "STAT_ANHAENGER_dummy_15_15";
BA_ "SysSignalName" SG_ 740 STAT_ANHAENGER_dummy_15_15 "STAT_ANHAENGER_dummy_15_15";
BA_ "CompuMethodName" SG_ 740 DISP_ST_TRAI "DISP_ST_TRAI";
BA_ "ISignalName" SG_ 740 DISP_ST_TRAI "DISP_ST_TRAI";
BA_ "LongName" SG_ 740 DISP_ST_TRAI "Anzeige_Status_Anhänger";
BA_ "SysSignalName" SG_ 740 DISP_ST_TRAI "DISP_ST_TRAI";
BA_ "ISignalName" SG_ 740 STAT_ANHAENGER_dummy_18_47 "STAT_ANHAENGER_dummy_18_47";
BA_ "LongName" SG_ 740 STAT_ANHAENGER_dummy_18_47 "STAT_ANHAENGER_dummy_18_47";
BA_ "SysSignalName" SG_ 740 STAT_ANHAENGER_dummy_18_47 "STAT_ANHAENGER_dummy_18_47";
BA_ "CompuMethodName" SG_ 740 ALIV_ST_TRAI "ALIV_4_BIT_Unsigned_Integer";
BA_ "ISignalName" SG_ 740 ALIV_ST_TRAI "ALIV_ST_TRAI";
BA_ "LongName" SG_ 740 ALIV_ST_TRAI "Alive_Status_Anhänger";
BA_ "SysSignalName" SG_ 740 ALIV_ST_TRAI "ALIV_ST_TRAI";
BA_ "ISignalName" SG_ 740 STAT_ANHAENGER_dummy_52_55 "STAT_ANHAENGER_dummy_52_55";
BA_ "LongName" SG_ 740 STAT_ANHAENGER_dummy_52_55 "STAT_ANHAENGER_dummy_52_55";
BA_ "SysSignalName" SG_ 740 STAT_ANHAENGER_dummy_52_55 "STAT_ANHAENGER_dummy_52_55";
BA_ "CompuMethodName" SG_ 740 CRC_ST_TRAI "CRC8";
BA_ "ISignalName" SG_ 740 CRC_ST_TRAI "CRC_ST_TRAI";
BA_ "LongName" SG_ 740 CRC_ST_TRAI "CRC_Status_Anhänger";
BA_ "SysSignalName" SG_ 740 CRC_ST_TRAI "CRC_ST_TRAI";
BA_ "CompuMethodName" SG_ 860 ST_BC_2_BN2020 "ST_BC_2";
BA_ "ISignalName" SG_ 860 ST_BC_2_BN2020 "ST_BC_2_BN2020";
BA_ "LongName" SG_ 860 ST_BC_2_BN2020 "Status_BC_2_BN2020";
BA_ "SysSignalName" SG_ 860 ST_BC_2_BN2020 "ST_BC_2_BN2020";
BA_ "CompuMethodName" SG_ 860 ST_RST_BC2_BN2020 "ST_RST_BC2";
BA_ "ISignalName" SG_ 860 ST_RST_BC2_BN2020 "ST_RST_BC2_BN2020";
BA_ "LongName" SG_ 860 ST_RST_BC2_BN2020 "Status_Reset_BC2_BN2020";
BA_ "SysSignalName" SG_ 860 ST_RST_BC2_BN2020 "ST_RST_BC2_BN2020";
BA_ "CompuMethodName" SG_ 860 ST_LIM_BN2020 "ST_LIM";
BA_ "ISignalName" SG_ 860 ST_LIM_BN2020 "ST_LIM_BN2020";
BA_ "LongName" SG_ 860 ST_LIM_BN2020 "Status_Begrenzung_BN2020";
BA_ "SysSignalName" SG_ 860 ST_LIM_BN2020 "ST_LIM_BN2020";
BA_ "CompuMethodName" SG_ 860 WARN_LIM_BN2020 "WARN_LIM";
BA_ "ISignalName" SG_ 860 WARN_LIM_BN2020 "WARN_LIM_BN2020";
BA_ "LongName" SG_ 860 WARN_LIM_BN2020 "Warnung_Begrenzung_BN2020";
BA_ "SysSignalName" SG_ 860 WARN_LIM_BN2020 "WARN_LIM_BN2020";
BA_ "CompuMethodName" SG_ 860 BNDRY_LIM_BN2020 "BNDRY_LIM";
BA_ "ISignalName" SG_ 860 BNDRY_LIM_BN2020 "BNDRY_LIM_BN2020";
BA_ "LongName" SG_ 860 BNDRY_LIM_BN2020 "Grenze_Begrenzung_BN2020";
BA_ "SysSignalName" SG_ 860 BNDRY_LIM_BN2020 "BNDRY_LIM_BN2020";
BA_ "CompuMethodName" SG_ 860 ESTP_SPDM_LIM_BN2020 "ESTP_SPDM_LIM";
BA_ "GenSigStartValue" SG_ 860 ESTP_SPDM_LIM_BN2020 80;
BA_ "ISignalName" SG_ 860 ESTP_SPDM_LIM_BN2020 "ESTP_SPDM_LIM_BN2020";
BA_ "LongName" SG_ 860 ESTP_SPDM_LIM_BN2020 "Endanschlag_Tacho_Begrenzung_BN2020";
BA_ "SysSignalName" SG_ 860 ESTP_SPDM_LIM_BN2020 "ESTP_SPDM_LIM_BN2020";
BA_ "CompuMethodName" SG_ 860 STSTP_SPDM_LIM_BN2020 "STSTP_SPDM_LIM_BN2020";
BA_ "ISignalName" SG_ 860 STSTP_SPDM_LIM_BN2020 "STSTP_SPDM_LIM_BN2020";
BA_ "LongName" SG_ 860 STSTP_SPDM_LIM_BN2020 "Startanschlag_Tacho_Begrenzung_BN2020";
BA_ "SysSignalName" SG_ 860 STSTP_SPDM_LIM_BN2020 "STSTP_SPDM_LIM_BN2020";
BA_ "CompuMethodName" SG_ 860 ST_UN_V_SPDM_BN2020 "ST_UN_V_SPDM_BN2020";
BA_ "ISignalName" SG_ 860 ST_UN_V_SPDM_BN2020 "ST_UN_V_SPDM_BN2020";
BA_ "LongName" SG_ 860 ST_UN_V_SPDM_BN2020 "Status_Einheit_Geschwindigkeit_Tacho_BN2020";
BA_ "SysSignalName" SG_ 860 ST_UN_V_SPDM_BN2020 "ST_UN_V_SPDM_BN2020";
BA_ "CompuMethodName" SG_ 554 ST_SHTR_PS "ST_SHTR_PS";
BA_ "ISignalName" SG_ 554 ST_SHTR_PS "ST_SHTR_PS";
BA_ "LongName" SG_ 554 ST_SHTR_PS "Status_Sitzheizung_BF";
BA_ "SysSignalName" SG_ 554 ST_SHTR_PS "ST_SHTR_PS";
BA_ "CompuMethodName" SG_ 558 ST_SHTR_PSR "ST_SHTR_PSR";
BA_ "ISignalName" SG_ 558 ST_SHTR_PSR "ST_SHTR_PSR";
BA_ "LongName" SG_ 558 ST_SHTR_PSR "Status_Sitzheizung_BFH";
BA_ "SysSignalName" SG_ 558 ST_SHTR_PSR "ST_SHTR_PSR";
BA_ "CompuMethodName" SG_ 847 ST_CT_HABR "ST_CT_HABR";
BA_ "ISignalName" SG_ 847 ST_CT_HABR "ST_CT_HABR";
BA_ "LongName" SG_ 847 ST_CT_HABR "Status_Kontakt_Handbremse";
BA_ "SysSignalName" SG_ 847 ST_CT_HABR "ST_CT_HABR";
BA_ "CompuMethodName" SG_ 722 DT_PSEN_RFCI "DT_PSEN_RFCI";
BA_ "ISignalName" SG_ 722 DT_PSEN_RFCI "DT_PSEN_RFCI";
BA_ "LongName" SG_ 722 DT_PSEN_RFCI "Daten_Drucksensor_Kältekreislauf";
BA_ "SysSignalName" SG_ 722 DT_PSEN_RFCI "DT_PSEN_RFCI";
BA_ "CompuMethodName" SG_ 481 CRC_ST_DSW_VRFD "CRC8";
BA_ "ISignalName" SG_ 481 CRC_ST_DSW_VRFD "CRC_ST_DSW_VRFD";
BA_ "LongName" SG_ 481 CRC_ST_DSW_VRFD "CRC_Status_Türkontakt_Abgesichert";
BA_ "SysSignalName" SG_ 481 CRC_ST_DSW_VRFD "CRC_ST_DSW_VRFD";
BA_ "CompuMethodName" SG_ 481 ALIV_ST_DSW_VRFD "Aliv_4";
BA_ "ISignalName" SG_ 481 ALIV_ST_DSW_VRFD "ALIV_ST_DSW_VRFD";
BA_ "LongName" SG_ 481 ALIV_ST_DSW_VRFD "Alive_Status_Türkontakt_Abgesichert";
BA_ "SysSignalName" SG_ 481 ALIV_ST_DSW_VRFD "ALIV_ST_DSW_VRFD";
BA_ "ISignalName" SG_ 481 STAT_DS_VRFD_dummy_12_15 "STAT_DS_VRFD_dummy_12_15";
BA_ "LongName" SG_ 481 STAT_DS_VRFD_dummy_12_15 "STAT_DS_VRFD_dummy_12_15";
BA_ "SysSignalName" SG_ 481 STAT_DS_VRFD_dummy_12_15 "STAT_DS_VRFD_dummy_12_15";
BA_ "CompuMethodName" SG_ 481 ST_DSW_DRD_VRFD "ST_DSW_VRFD";
BA_ "ISignalName" SG_ 481 ST_DSW_DRD_VRFD "ST_DSW_DRD_VRFD";
BA_ "LongName" SG_ 481 ST_DSW_DRD_VRFD "Status_Türkontakt_FAT_Abgesichert";
BA_ "SysSignalName" SG_ 481 ST_DSW_DRD_VRFD "ST_DSW_DRD_VRFD";
BA_ "CompuMethodName" SG_ 481 ST_DSW_PSD_VRFD "ST_DSW_VRFD";
BA_ "ISignalName" SG_ 481 ST_DSW_PSD_VRFD "ST_DSW_PSD_VRFD";
BA_ "LongName" SG_ 481 ST_DSW_PSD_VRFD "Status_Türkontakt_BFT_Abgesichert";
BA_ "SysSignalName" SG_ 481 ST_DSW_PSD_VRFD "ST_DSW_PSD_VRFD";
BA_ "CompuMethodName" SG_ 481 ST_DSW_PSDR_VRFD "ST_DSW_VRFD";
BA_ "ISignalName" SG_ 481 ST_DSW_PSDR_VRFD "ST_DSW_PSDR_VRFD";
BA_ "LongName" SG_ 481 ST_DSW_PSDR_VRFD "Status_Türkontakt_BFTH_Abgesichert";
BA_ "SysSignalName" SG_ 481 ST_DSW_PSDR_VRFD "ST_DSW_PSDR_VRFD";
BA_ "CompuMethodName" SG_ 481 ST_DSW_DVDR_VRFD "ST_DSW_VRFD";
BA_ "ISignalName" SG_ 481 ST_DSW_DVDR_VRFD "ST_DSW_DVDR_VRFD";
BA_ "LongName" SG_ 481 ST_DSW_DVDR_VRFD "Status_Türkontakt_FATH_Abgesichert";
BA_ "SysSignalName" SG_ 481 ST_DSW_DVDR_VRFD "ST_DSW_DVDR_VRFD";
BA_ "ISignalName" SG_ 481 STAT_DS_VRFD_dummy_24_47 "STAT_DS_VRFD_dummy_24_47";
BA_ "LongName" SG_ 481 STAT_DS_VRFD_dummy_24_47 "STAT_DS_VRFD_dummy_24_47";
BA_ "SysSignalName" SG_ 481 STAT_DS_VRFD_dummy_24_47 "STAT_DS_VRFD_dummy_24_47";
BA_ "CompuMethodName" SG_ 779 CRC_ST_ENG_STA_AUTO "CRC8";
BA_ "ISignalName" SG_ 779 CRC_ST_ENG_STA_AUTO "CRC_ST_ENG_STA_AUTO";
BA_ "LongName" SG_ 779 CRC_ST_ENG_STA_AUTO "CRC_Status_Motor_Start_AUTO";
BA_ "SysSignalName" SG_ 779 CRC_ST_ENG_STA_AUTO "CRC_ST_ENG_STA_AUTO";
BA_ "CompuMethodName" SG_ 779 ALIV_ST_ENG_STA_AUTO "ALIV_COU_4";
BA_ "ISignalName" SG_ 779 ALIV_ST_ENG_STA_AUTO "ALIV_ST_ENG_STA_AUTO";
BA_ "LongName" SG_ 779 ALIV_ST_ENG_STA_AUTO "Alive_Status_Motor_Start_AUTO";
BA_ "SysSignalName" SG_ 779 ALIV_ST_ENG_STA_AUTO "ALIV_ST_ENG_STA_AUTO";
BA_ "CompuMethodName" SG_ 779 RQ_MSA_ENG_STA_1 "RQ_MSA_ENG_STA";
BA_ "ISignalName" SG_ 779 RQ_MSA_ENG_STA_1 "RQ_MSA_ENG_STA_1";
BA_ "LongName" SG_ 779 RQ_MSA_ENG_STA_1 "Anforderung_MSA_Motor_Start_1";
BA_ "SysSignalName" SG_ 779 RQ_MSA_ENG_STA_1 "RQ_MSA_ENG_STA_1";
BA_ "CompuMethodName" SG_ 779 RQ_MSA_ENG_STA_2 "RQ_MSA_ENG_STA";
BA_ "ISignalName" SG_ 779 RQ_MSA_ENG_STA_2 "RQ_MSA_ENG_STA_2";
BA_ "LongName" SG_ 779 RQ_MSA_ENG_STA_2 "Anforderung_MSA_Motor_Start_2";
BA_ "SysSignalName" SG_ 779 RQ_MSA_ENG_STA_2 "RQ_MSA_ENG_STA_2";
BA_ "CompuMethodName" SG_ 779 ST_AVL_PENG_CENG_ENGMG "ST_AVL_PENG_CENG_ENGMG";
BA_ "ISignalName" SG_ 779 ST_AVL_PENG_CENG_ENGMG "ST_AVL_PENG_CENG_ENGMG";
BA_ "LongName" SG_ 779 ST_AVL_PENG_CENG_ENGMG "Status_Ist_Kraftschluss_Verbrennungsmotor_Motorsteuerung";
BA_ "SysSignalName" SG_ 779 ST_AVL_PENG_CENG_ENGMG "ST_AVL_PENG_CENG_ENGMG";
BA_ "CompuMethodName" SG_ 779 ST_FN_MSA "ST_FN_MSA";
BA_ "ISignalName" SG_ 779 ST_FN_MSA "ST_FN_MSA";
BA_ "LongName" SG_ 779 ST_FN_MSA "Status_Funktion_MSA";
BA_ "SysSignalName" SG_ 779 ST_FN_MSA "ST_FN_MSA";
BA_ "CompuMethodName" SG_ 779 SPEC_TYP_ENGSTA_PRM "SPEC_TYP_ENGSTA_PRM";
BA_ "ISignalName" SG_ 779 SPEC_TYP_ENGSTA_PRM "SPEC_TYP_ENGSTA_PRM";
BA_ "LongName" SG_ 779 SPEC_TYP_ENGSTA_PRM "Vorgabe_Typ_Motorstart_Dauerhaft";
BA_ "SysSignalName" SG_ 779 SPEC_TYP_ENGSTA_PRM "SPEC_TYP_ENGSTA_PRM";
BA_ "CompuMethodName" SG_ 779 ST_SHFT_MSA_ENGSTP "ST_SHFT_MSA_ENGSTP";
BA_ "ISignalName" SG_ 779 ST_SHFT_MSA_ENGSTP "ST_SHFT_MSA_ENGSTP";
BA_ "LongName" SG_ 779 ST_SHFT_MSA_ENGSTP "Status_Umsetzung_MSA_Motorstop";
BA_ "SysSignalName" SG_ 779 ST_SHFT_MSA_ENGSTP "ST_SHFT_MSA_ENGSTP";
BA_ "CompuMethodName" SG_ 779 PSBTY_MSA_ENG_STOP_STA "PSBTY_MSA_ENG_STOP_STA";
BA_ "ISignalName" SG_ 779 PSBTY_MSA_ENG_STOP_STA "PSBTY_MSA_ENG_STOP_STA";
BA_ "LongName" SG_ 779 PSBTY_MSA_ENG_STOP_STA "Möglichkeit_MSA_Motor_Stop_Start";
BA_ "SysSignalName" SG_ 779 PSBTY_MSA_ENG_STOP_STA "PSBTY_MSA_ENG_STOP_STA";
BA_ "CompuMethodName" SG_ 779 ST_TAR_CENG "ST_TAR_CENG";
BA_ "ISignalName" SG_ 779 ST_TAR_CENG "ST_TAR_CENG";
BA_ "LongName" SG_ 779 ST_TAR_CENG "Status_Soll_Verbrennungsmotor";
BA_ "SysSignalName" SG_ 779 ST_TAR_CENG "ST_TAR_CENG";
BA_ "CompuMethodName" SG_ 779 SPEC_TYP_ENGSTA "SPEC_TYP_ENGSTA";
BA_ "ISignalName" SG_ 779 SPEC_TYP_ENGSTA "SPEC_TYP_ENGSTA";
BA_ "LongName" SG_ 779 SPEC_TYP_ENGSTA "Vorgabe_Typ_Motorstart";
BA_ "SysSignalName" SG_ 779 SPEC_TYP_ENGSTA "SPEC_TYP_ENGSTA";
BA_ "CompuMethodName" SG_ 779 ST_RPM_CLCTR_MOT "ST_RPM_CLCTR_MOT";
BA_ "ISignalName" SG_ 779 ST_RPM_CLCTR_MOT "ST_RPM_CLCTR_MOT";
BA_ "LongName" SG_ 779 ST_RPM_CLCTR_MOT "Status_Drehzahl_Regelung_E-Motor";
BA_ "SysSignalName" SG_ 779 ST_RPM_CLCTR_MOT "ST_RPM_CLCTR_MOT";
BA_ "CompuMethodName" SG_ 779 ST_TAR_PENG_CENG "ST_TAR_PENG_CENG";
BA_ "ISignalName" SG_ 779 ST_TAR_PENG_CENG "ST_TAR_PENG_CENG";
BA_ "LongName" SG_ 779 ST_TAR_PENG_CENG "Status_Soll_Kraftschluss_Verbrennungsmotor";
BA_ "SysSignalName" SG_ 779 ST_TAR_PENG_CENG "ST_TAR_PENG_CENG";
BA_ "CompuMethodName" SG_ 779 ST_AVAI_SAIL_DME "ST_AVAI_SAIL_DME";
BA_ "ISignalName" SG_ 779 ST_AVAI_SAIL_DME "ST_AVAI_SAIL_DME";
BA_ "LongName" SG_ 779 ST_AVAI_SAIL_DME "Status_Verfügbarkeit_Segeln_DME";
BA_ "SysSignalName" SG_ 779 ST_AVAI_SAIL_DME "ST_AVAI_SAIL_DME";
BA_ "CompuMethodName" SG_ 779 RQ_SLIP_K0 "RQ_SLIP_K0";
BA_ "GenSigStartValue" SG_ 779 RQ_SLIP_K0 100;
BA_ "ISignalName" SG_ 779 RQ_SLIP_K0 "RQ_SLIP_K0";
BA_ "LongName" SG_ 779 RQ_SLIP_K0 "Anforderung_Schlupf_K0";
BA_ "SysSignalName" SG_ 779 RQ_SLIP_K0 "RQ_SLIP_K0";
BA_ "CompuMethodName" SG_ 779 VARI_TYP_ENGSTA "VARI_TYP_ENGSTA";
BA_ "ISignalName" SG_ 779 VARI_TYP_ENGSTA "VARI_TYP_ENGSTA";
BA_ "LongName" SG_ 779 VARI_TYP_ENGSTA "Varianten_Typ_Motorstart";
BA_ "SysSignalName" SG_ 779 VARI_TYP_ENGSTA "VARI_TYP_ENGSTA";
BA_ "ISignalName" SG_ 779 STAT_ENG_STA_AUTO_dummy_58_59 "STAT_ENG_STA_AUTO_dummy_58_59";
BA_ "LongName" SG_ 779 STAT_ENG_STA_AUTO_dummy_58_59 "STAT_ENG_STA_AUTO_dummy_58_59";
BA_ "SysSignalName" SG_ 779 STAT_ENG_STA_AUTO_dummy_58_59 "STAT_ENG_STA_AUTO_dummy_58_59";
BA_ "CompuMethodName" SG_ 779 ST_CON_MSA "ST_CON_MSA";
BA_ "ISignalName" SG_ 779 ST_CON_MSA "ST_CON_MSA";
BA_ "LongName" SG_ 779 ST_CON_MSA "Status_Zustand_MSA";
BA_ "SysSignalName" SG_ 779 ST_CON_MSA "ST_CON_MSA";
BA_ "CompuMethodName" SG_ 788 ST_LOWB "ST_LOWB";
BA_ "ISignalName" SG_ 788 ST_LOWB "ST_LOWB";
BA_ "LongName" SG_ 788 ST_LOWB "status_low-beam";
BA_ "SysSignalName" SG_ 788 ST_LOWB "ST_LOWB";
BA_ "CompuMethodName" SG_ 788 ST_SEN_LOWB "ST_SEN_LOWB";
BA_ "ISignalName" SG_ 788 ST_SEN_LOWB "ST_SEN_LOWB";
BA_ "LongName" SG_ 788 ST_SEN_LOWB "Status_Sensor_Fahrlicht";
BA_ "SysSignalName" SG_ 788 ST_SEN_LOWB "ST_SEN_LOWB";
BA_ "CompuMethodName" SG_ 788 AMBR_LOWB "AMBR_LOWB";
BA_ "GenSigStartValue" SG_ 788 AMBR_LOWB 1;
BA_ "ISignalName" SG_ 788 AMBR_LOWB "AMBR_LOWB";
BA_ "LongName" SG_ 788 AMBR_LOWB "Umgebungshelligkeit_Fahrlicht";
BA_ "SysSignalName" SG_ 788 AMBR_LOWB "AMBR_LOWB";
BA_ "CompuMethodName" SG_ 788 ST_LOWB_REAS "ST_LOWB_REAS";
BA_ "ISignalName" SG_ 788 ST_LOWB_REAS "ST_LOWB_REAS";
BA_ "LongName" SG_ 788 ST_LOWB_REAS "Status_Fahrlicht_Grund";
BA_ "SysSignalName" SG_ 788 ST_LOWB_REAS "ST_LOWB_REAS";
BA_ "CompuMethodName" SG_ 788 ST_VL_LOWB "ST_VL_LOWB";
BA_ "ISignalName" SG_ 788 ST_VL_LOWB "ST_VL_LOWB";
BA_ "LongName" SG_ 788 ST_VL_LOWB "Status_Wert_Fahrlicht";
BA_ "SysSignalName" SG_ 788 ST_VL_LOWB "ST_VL_LOWB";
BA_ "CompuMethodName" SG_ 562 ST_SHTR_DR "ST_SHTR_DR";
BA_ "ISignalName" SG_ 562 ST_SHTR_DR "ST_SHTR_DR";
BA_ "LongName" SG_ 562 ST_SHTR_DR "Status_Sitzheizung_FA";
BA_ "SysSignalName" SG_ 562 ST_SHTR_DR "ST_SHTR_DR";
BA_ "CompuMethodName" SG_ 566 ST_SHTR_DRR "ST_SHTR_DRR";
BA_ "ISignalName" SG_ 566 ST_SHTR_DRR "ST_SHTR_DRR";
BA_ "LongName" SG_ 566 ST_SHTR_DRR "Status_Sitzheizung_FAH";
BA_ "SysSignalName" SG_ 566 ST_SHTR_DRR "ST_SHTR_DRR";
BA_ "CompuMethodName" SG_ 570 NO_KEY_PRSL_IMME "NO_KEY_PRSL_IMME";
BA_ "ISignalName" SG_ 570 NO_KEY_PRSL_IMME "NO_KEY_PRSL_IMME";
BA_ "LongName" SG_ 570 NO_KEY_PRSL_IMME "Nummer_Schlüssel_Personalisierung_Aktuell";
BA_ "SysSignalName" SG_ 570 NO_KEY_PRSL_IMME "NO_KEY_PRSL_IMME";
BA_ "CompuMethodName" SG_ 570 NO_KEY_PRSL "NO_KEY_PRSL";
BA_ "ISignalName" SG_ 570 NO_KEY_PRSL "NO_KEY_PRSL";
BA_ "LongName" SG_ 570 NO_KEY_PRSL "Nummer_Schlüssel_Personalisierung";
BA_ "SysSignalName" SG_ 570 NO_KEY_PRSL "NO_KEY_PRSL";
BA_ "CompuMethodName" SG_ 570 ST_KEY_RMC "ST_KEY_RMC";
BA_ "ISignalName" SG_ 570 ST_KEY_RMC "ST_KEY_RMC";
BA_ "LongName" SG_ 570 ST_KEY_RMC "Status_Schlüssel_Fernbedienung";
BA_ "SysSignalName" SG_ 570 ST_KEY_RMC "ST_KEY_RMC";
BA_ "CompuMethodName" SG_ 570 ST_KEY_BT "ST_KEY_BT";
BA_ "ISignalName" SG_ 570 ST_KEY_BT "ST_KEY_BT";
BA_ "LongName" SG_ 570 ST_KEY_BT "Status_Schlüssel_Batterie";
BA_ "SysSignalName" SG_ 570 ST_KEY_BT "ST_KEY_BT";
BA_ "CompuMethodName" SG_ 570 CTR_ITLI_PLIP "CTR_ITLI_PLIP";
BA_ "ISignalName" SG_ 570 CTR_ITLI_PLIP "CTR_ITLI_PLIP";
BA_ "LongName" SG_ 570 CTR_ITLI_PLIP "Steuerung_Innenbeleuchtung_Funkschlüssel";
BA_ "SysSignalName" SG_ 570 CTR_ITLI_PLIP "CTR_ITLI_PLIP";
BA_ "CompuMethodName" SG_ 570 OP_KEY_LDPO_FLDT "OP_KEY_LDPO_FLDT";
BA_ "ISignalName" SG_ 570 OP_KEY_LDPO_FLDT "OP_KEY_LDPO_FLDT";
BA_ "LongName" SG_ 570 OP_KEY_LDPO_FLDT "Bedienung_Schlüssel_Lade-Position_Verdeck";
BA_ "SysSignalName" SG_ 570 OP_KEY_LDPO_FLDT "OP_KEY_LDPO_FLDT";
BA_ "CompuMethodName" SG_ 570 OP_KEY_BUT_ULOK "ENUM_2_noIniVal_noDflVal_3_noQuant_noOffs_typeBitField_noRng_21";
BA_ "ISignalName" SG_ 570 OP_KEY_BUT_ULOK "OP_KEY_BUT_ULOK";
BA_ "LongName" SG_ 570 OP_KEY_BUT_ULOK "Bedienung_Schlüssel_Taste_Entriegeln";
BA_ "SysSignalName" SG_ 570 OP_KEY_BUT_ULOK "OP_KEY_BUT_ULOK";
BA_ "CompuMethodName" SG_ 570 OP_KEY_BUT_LOK "ENUM_2_noIniVal_noDflVal_3_noQuant_noOffs_typeBitField_noRng_21";
BA_ "ISignalName" SG_ 570 OP_KEY_BUT_LOK "OP_KEY_BUT_LOK";
BA_ "LongName" SG_ 570 OP_KEY_BUT_LOK "Bedienung_Schlüssel_Taste_Verriegeln";
BA_ "SysSignalName" SG_ 570 OP_KEY_BUT_LOK "OP_KEY_BUT_LOK";
BA_ "CompuMethodName" SG_ 570 OP_KEY_BUT_BTL "OP_KEY_BUT";
BA_ "ISignalName" SG_ 570 OP_KEY_BUT_BTL "OP_KEY_BUT_BTL";
BA_ "LongName" SG_ 570 OP_KEY_BUT_BTL "Bedienung_Schlüssel_Taste_Heckklappe";
BA_ "SysSignalName" SG_ 570 OP_KEY_BUT_BTL "OP_KEY_BUT_BTL";
BA_ "CompuMethodName" SG_ 570 OP_KEY_BUT_SPFN "OP_KEY_BUT_SPFN";
BA_ "ISignalName" SG_ 570 OP_KEY_BUT_SPFN "OP_KEY_BUT_SPFN";
BA_ "LongName" SG_ 570 OP_KEY_BUT_SPFN "Bedienung_Schlüssel_Taste_Sonderfunktion";
BA_ "SysSignalName" SG_ 570 OP_KEY_BUT_SPFN "OP_KEY_BUT_SPFN";
BA_ "CompuMethodName" SG_ 570 NO_KEY_TR_PRSL "NO_KEY_TR_PRSL";
BA_ "ISignalName" SG_ 570 NO_KEY_TR_PRSL "NO_KEY_TR_PRSL";
BA_ "LongName" SG_ 570 NO_KEY_TR_PRSL "Nummer_Schlüssel_Trigger_Personalisierung";
BA_ "SysSignalName" SG_ 570 NO_KEY_TR_PRSL "NO_KEY_TR_PRSL";
BA_ "CompuMethodName" SG_ 570 CTR_TR_PRSL "CTR_TR_PRSL";
BA_ "ISignalName" SG_ 570 CTR_TR_PRSL "CTR_TR_PRSL";
BA_ "LongName" SG_ 570 CTR_TR_PRSL "Steuerung_Trigger_Personalisierung";
BA_ "SysSignalName" SG_ 570 CTR_TR_PRSL "CTR_TR_PRSL";
BA_ "CompuMethodName" SG_ 570 ST_LOK_RQ_FFB_LFSR "ST_LOK_RQ_FFB_LFSR";
BA_ "ISignalName" SG_ 570 ST_LOK_RQ_FFB_LFSR "ST_LOK_RQ_FFB_LFSR";
BA_ "LongName" SG_ 570 ST_LOK_RQ_FFB_LFSR "Status_Verriegeln_Anforderung_FFB_LF-Nahbereich";
BA_ "SysSignalName" SG_ 570 ST_LOK_RQ_FFB_LFSR "ST_LOK_RQ_FFB_LFSR";
BA_ "CompuMethodName" SG_ 570 CTR_LP_FMH "CTR_LP_FMH";
BA_ "ISignalName" SG_ 570 CTR_LP_FMH "CTR_LP_FMH";
BA_ "LongName" SG_ 570 CTR_LP_FMH "Steuerung_Licht_Heimleuchten";
BA_ "SysSignalName" SG_ 570 CTR_LP_FMH "CTR_LP_FMH";
BA_ "CompuMethodName" SG_ 570 CTR_UGDO "CTR_UGDO";
BA_ "ISignalName" SG_ 570 CTR_UGDO "CTR_UGDO";
BA_ "LongName" SG_ 570 CTR_UGDO "Steuerung_Universeller-Garagentoröffner";
BA_ "SysSignalName" SG_ 570 CTR_UGDO "CTR_UGDO";
BA_ "CompuMethodName" SG_ 570 ST_KEY_BT_DISP_MMI "ST_KEY_BT_DISP_MMI";
BA_ "ISignalName" SG_ 570 ST_KEY_BT_DISP_MMI "ST_KEY_BT_DISP_MMI";
BA_ "LongName" SG_ 570 ST_KEY_BT_DISP_MMI "Status_Schlüssel_Batterie_Anzeige_MMI";
BA_ "SysSignalName" SG_ 570 ST_KEY_BT_DISP_MMI "ST_KEY_BT_DISP_MMI";
BA_ "CompuMethodName" SG_ 570 ST_PCOL "ST_PCOL";
BA_ "ISignalName" SG_ 570 ST_PCOL "ST_PCOL";
BA_ "LongName" SG_ 570 ST_PCOL "Status_Standkühlen";
BA_ "SysSignalName" SG_ 570 ST_PCOL "ST_PCOL";
BA_ "CompuMethodName" SG_ 570 CTR_PAN_MOD "CTR_PCOL";
BA_ "ISignalName" SG_ 570 CTR_PAN_MOD "CTR_PAN_MOD";
BA_ "LongName" SG_ 570 CTR_PAN_MOD "Steuerung_Panik_Modus";
BA_ "SysSignalName" SG_ 570 CTR_PAN_MOD "CTR_PAN_MOD";
BA_ "CompuMethodName" SG_ 570 AVL_MOD_SSHK "AVL_MOD_SSHK";
BA_ "ISignalName" SG_ 570 AVL_MOD_SSHK "AVL_MOD_SSHK";
BA_ "LongName" SG_ 570 AVL_MOD_SSHK "Ist_Modus_SafeShareKey";
BA_ "SysSignalName" SG_ 570 AVL_MOD_SSHK "AVL_MOD_SSHK";
BA_ "CompuMethodName" SG_ 944 ST_GR_BAC "ST_GR_BAC";
BA_ "ISignalName" SG_ 944 ST_GR_BAC "ST_GR_BAC";
BA_ "LongName" SG_ 944 ST_GR_BAC "Status_Gang_Rückwärts";
BA_ "SysSignalName" SG_ 944 ST_GR_BAC "ST_GR_BAC";
BA_ "CompuMethodName" SG_ 274 AVL_I_HVSTO "I_HVSTO";
BA_ "GenSigStartValue" SG_ 274 AVL_I_HVSTO -819;
BA_ "ISignalName" SG_ 274 AVL_I_HVSTO "AVL_I_HVSTO";
BA_ "LongName" SG_ 274 AVL_I_HVSTO "Ist_Strom_Hochvoltspeicher";
BA_ "SysSignalName" SG_ 274 AVL_I_HVSTO "AVL_I_HVSTO";
BA_ "CompuMethodName" SG_ 274 AVL_U_HVSTO "U_HVSTO";
BA_ "ISignalName" SG_ 274 AVL_U_HVSTO "AVL_U_HVSTO";
BA_ "LongName" SG_ 274 AVL_U_HVSTO "Ist_Spannung_Hochvoltspeicher";
BA_ "SysSignalName" SG_ 274 AVL_U_HVSTO "AVL_U_HVSTO";
BA_ "CompuMethodName" SG_ 274 StatusThermicCapacityUtilization "StatusThermicCapacityUtilizationHighVoltageStorage2";
BA_ "ISignalName" SG_ 274 StatusThermicCapacityUtilization "StatusThermicCapacityUtilizationHighVoltageStorage2";
BA_ "LongName" SG_ 274 StatusThermicCapacityUtilization "StatusThermicCapacityUtilizationHighVoltageStorage2";
BA_ "SysSignalName" SG_ 274 StatusThermicCapacityUtilization "StatusThermicCapacityUtilizationHighVoltageStorage2";
BA_ "SystemSignalLongSymbol" SG_ 274 StatusThermicCapacityUtilization "StatusThermicCapacityUtilizationHighVoltageStorage2";
BA_ "CompuMethodName" SG_ 274 AVL_U_LINK "AVL_U_LINK";
BA_ "ISignalName" SG_ 274 AVL_U_LINK "AVL_U_LINK";
BA_ "LongName" SG_ 274 AVL_U_LINK "Ist_Spannung_Zwischenkreis";
BA_ "SysSignalName" SG_ 274 AVL_U_LINK "AVL_U_LINK";
BA_ "CompuMethodName" SG_ 814 CTR_BLW "CTR_BLW";
BA_ "ISignalName" SG_ 814 CTR_BLW "CTR_BLW";
BA_ "LongName" SG_ 814 CTR_BLW "Steuerung_Gebläse";
BA_ "SysSignalName" SG_ 814 CTR_BLW "CTR_BLW";
BA_ "CompuMethodName" SG_ 814 TEMP_INTR "UI_8_noIniVal_noDflVal_255_0_1667s_0_noEnc_hasRng";
BA_ "GenSigStartValue" SG_ 814 TEMP_INTR 10;
BA_ "ISignalName" SG_ 814 TEMP_INTR "TEMP_INTR";
BA_ "LongName" SG_ 814 TEMP_INTR "Temperatur_Innen";
BA_ "SysSignalName" SG_ 814 TEMP_INTR "TEMP_INTR";
BA_ "CompuMethodName" SG_ 814 TEMP_EVA "UI_8_noIniVal_noDflVal_255_0_20s_MI_10_noEnc_hasRng";
BA_ "GenSigStartValue" SG_ 814 TEMP_EVA -10;
BA_ "ISignalName" SG_ 814 TEMP_EVA "TEMP_EVA";
BA_ "LongName" SG_ 814 TEMP_EVA "Temperatur_Verdampfer";
BA_ "SysSignalName" SG_ 814 TEMP_EVA "TEMP_EVA";
BA_ "CompuMethodName" SG_ 814 TEMP_HTEX "TEMP_HTEX";
BA_ "GenSigStartValue" SG_ 814 TEMP_HTEX 5;
BA_ "ISignalName" SG_ 814 TEMP_HTEX "TEMP_HTEX";
BA_ "LongName" SG_ 814 TEMP_HTEX "temperature_heat-exchanger";
BA_ "SysSignalName" SG_ 814 TEMP_HTEX "TEMP_HTEX";
BA_ "CompuMethodName" SG_ 742 TEMP_TAR_DR_IHKA "TEMP_TAR_DR";
BA_ "GenSigStartValue" SG_ 742 TEMP_TAR_DR_IHKA 16;
BA_ "ISignalName" SG_ 742 TEMP_TAR_DR_IHKA "TEMP_TAR_DR_IHKA";
BA_ "LongName" SG_ 742 TEMP_TAR_DR_IHKA "Temperatur_Soll_FA_IHKA";
BA_ "SysSignalName" SG_ 742 TEMP_TAR_DR_IHKA "TEMP_TAR_DR_IHKA";
BA_ "CompuMethodName" SG_ 752 ST_PAIC "OP_ST_PAIC";
BA_ "ISignalName" SG_ 752 ST_PAIC "ST_PAIC";
BA_ "LongName" SG_ 752 ST_PAIC "Status_Standklima";
BA_ "SysSignalName" SG_ 752 ST_PAIC "ST_PAIC";
BA_ "CompuMethodName" SG_ 752 ST_IVNT "OP_ST_IVNT";
BA_ "ISignalName" SG_ 752 ST_IVNT "ST_IVNT";
BA_ "LongName" SG_ 752 ST_IVNT "Status_Standlüften";
BA_ "SysSignalName" SG_ 752 ST_IVNT "ST_IVNT";
BA_ "CompuMethodName" SG_ 752 ST_BLW "ST_BLW";
BA_ "ISignalName" SG_ 752 ST_BLW "ST_BLW";
BA_ "LongName" SG_ 752 ST_BLW "Status_Gebläse";
BA_ "SysSignalName" SG_ 752 ST_BLW "ST_BLW";
BA_ "CompuMethodName" SG_ 752 ST_PHTR "OP_ST_PHT";
BA_ "ISignalName" SG_ 752 ST_PHTR "ST_PHTR";
BA_ "LongName" SG_ 752 ST_PHTR "Status_Standheizung";
BA_ "SysSignalName" SG_ 752 ST_PHTR "ST_PHTR";
BA_ "CompuMethodName" SG_ 752 ST_EXHT "OP_ST_EXHT";
BA_ "ISignalName" SG_ 752 ST_EXHT "ST_EXHT";
BA_ "LongName" SG_ 752 ST_EXHT "Status_Zuheizer";
BA_ "SysSignalName" SG_ 752 ST_EXHT "ST_EXHT";
BA_ "CompuMethodName" SG_ 752 ST_PFN_AMOD "PFN_AMOD";
BA_ "ISignalName" SG_ 752 ST_PFN_AMOD "ST_PFN_AMOD";
BA_ "LongName" SG_ 752 ST_PFN_AMOD "Status_Standfunktion_Auto-Modus";
BA_ "SysSignalName" SG_ 752 ST_PFN_AMOD "ST_PFN_AMOD";
BA_ "CompuMethodName" SG_ 752 ST_PFN_RMC "ST_PFN_RMC";
BA_ "ISignalName" SG_ 752 ST_PFN_RMC "ST_PFN_RMC";
BA_ "LongName" SG_ 752 ST_PFN_RMC "Status_Standfunktion_Fernbedienung";
BA_ "SysSignalName" SG_ 752 ST_PFN_RMC "ST_PFN_RMC";
BA_ "CompuMethodName" SG_ 752 RQ_ENGR_PFN "RQ_ENGR_PFN";
BA_ "ISignalName" SG_ 752 RQ_ENGR_PFN "RQ_ENGR_PFN";
BA_ "LongName" SG_ 752 RQ_ENGR_PFN "Anforderung_Motorlauf_Standfunktion";
BA_ "SysSignalName" SG_ 752 RQ_ENGR_PFN "RQ_ENGR_PFN";
BA_ "CompuMethodName" SG_ 752 ST_ENGR_PFN "ST_ENGR_PFN";
BA_ "ISignalName" SG_ 752 ST_ENGR_PFN "ST_ENGR_PFN";
BA_ "LongName" SG_ 752 ST_ENGR_PFN "Status_Motorlauf_Standfunktion";
BA_ "SysSignalName" SG_ 752 ST_ENGR_PFN "ST_ENGR_PFN";
BA_ "CompuMethodName" SG_ 752 RQR_PFN "RQR_PFN";
BA_ "ISignalName" SG_ 752 RQR_PFN "RQR_PFN";
BA_ "LongName" SG_ 752 RQR_PFN "Anforderer_Standfunktion";
BA_ "SysSignalName" SG_ 752 RQR_PFN "RQR_PFN";
BA_ "CompuMethodName" SG_ 752 ST_SU_REM_STA "ST_SU_REM_STA";
BA_ "ISignalName" SG_ 752 ST_SU_REM_STA "ST_SU_REM_STA";
BA_ "LongName" SG_ 752 ST_SU_REM_STA "Status_Konfiguration_Remote_Start";
BA_ "SysSignalName" SG_ 752 ST_SU_REM_STA "ST_SU_REM_STA";
BA_ "CompuMethodName" SG_ 752 AVL_DUR_PFN "AVL_DUR_PFN";
BA_ "ISignalName" SG_ 752 AVL_DUR_PFN "AVL_DUR_PFN";
BA_ "LongName" SG_ 752 AVL_DUR_PFN "Ist_Dauer_Standfunktion";
BA_ "SysSignalName" SG_ 752 AVL_DUR_PFN "AVL_DUR_PFN";
BA_ "CompuMethodName" SG_ 542 ST_CONTR_NIVI "ST_CONTR_NIVI";
BA_ "ISignalName" SG_ 542 ST_CONTR_NIVI "ST_CONTR_NIVI";
BA_ "LongName" SG_ 542 ST_CONTR_NIVI "Status_Kontrast_Night-Vision";
BA_ "SysSignalName" SG_ 542 ST_CONTR_NIVI "ST_CONTR_NIVI";
BA_ "CompuMethodName" SG_ 542 ST_RLS_NIVI "ST_RLS_NIVI";
BA_ "ISignalName" SG_ 542 ST_RLS_NIVI "ST_RLS_NIVI";
BA_ "LongName" SG_ 542 ST_RLS_NIVI "Status_Freigabe_Night-Vision";
BA_ "SysSignalName" SG_ 542 ST_RLS_NIVI "ST_RLS_NIVI";
BA_ "CompuMethodName" SG_ 542 ST_CAM_NIVI "ST_CAM_NIVI";
BA_ "ISignalName" SG_ 542 ST_CAM_NIVI "ST_CAM_NIVI";
BA_ "LongName" SG_ 542 ST_CAM_NIVI "Status_Kamera_Night-Vision";
BA_ "SysSignalName" SG_ 542 ST_CAM_NIVI "ST_CAM_NIVI";
BA_ "CompuMethodName" SG_ 542 ST_OPTN_ACTVN_GZA "ST_OPTN_ACTVN_GZA";
BA_ "ISignalName" SG_ 542 ST_OPTN_ACTVN_GZA "ST_OPTN_ACTVN_GZA";
BA_ "LongName" SG_ 542 ST_OPTN_ACTVN_GZA "Status_Option_Aktivierung_GZA";
BA_ "SysSignalName" SG_ 542 ST_OPTN_ACTVN_GZA "ST_OPTN_ACTVN_GZA";
BA_ "CompuMethodName" SG_ 542 ST_OBJ_DETE_NIVI "OBJ_DETE_NIVI";
BA_ "ISignalName" SG_ 542 ST_OBJ_DETE_NIVI "ST_OBJ_DETE_NIVI";
BA_ "LongName" SG_ 542 ST_OBJ_DETE_NIVI "Status_Objekt_Detektion_Night-Vision";
BA_ "SysSignalName" SG_ 542 ST_OBJ_DETE_NIVI "ST_OBJ_DETE_NIVI";
BA_ "CompuMethodName" SG_ 542 ST_BRIG_OFFS_NIVI "BRIG_OFFS_NIVI";
BA_ "ISignalName" SG_ 542 ST_BRIG_OFFS_NIVI "ST_BRIG_OFFS_NIVI";
BA_ "LongName" SG_ 542 ST_BRIG_OFFS_NIVI "Status_Helligkeit_Offset_Night-Vision";
BA_ "SysSignalName" SG_ 542 ST_BRIG_OFFS_NIVI "ST_BRIG_OFFS_NIVI";
BA_ "CompuMethodName" SG_ 542 RQ_DISP_NIVI "RQ_DISP_NIVI";
BA_ "ISignalName" SG_ 542 RQ_DISP_NIVI "RQ_DISP_NIVI";
BA_ "LongName" SG_ 542 RQ_DISP_NIVI "Anforderung_Anzeige_Night-Vision";
BA_ "SysSignalName" SG_ 542 RQ_DISP_NIVI "RQ_DISP_NIVI";
BA_ "CompuMethodName" SG_ 542 ST_AVAI_OBJ_RCOG_NIVI "ST_AVAI_OBJ_RCOG_NIVI";
BA_ "ISignalName" SG_ 542 ST_AVAI_OBJ_RCOG_NIVI "ST_AVAI_OBJ_RCOG_NIVI";
BA_ "LongName" SG_ 542 ST_AVAI_OBJ_RCOG_NIVI "Status_Verfügbarkeit_Objekt_Erkennung_Night-Vision";
BA_ "SysSignalName" SG_ 542 ST_AVAI_OBJ_RCOG_NIVI "ST_AVAI_OBJ_RCOG_NIVI";
BA_ "CompuMethodName" SG_ 543 ST_AVAI_CHAIN_BRG "ST_AVAI_CHAIN_BRG";
BA_ "ISignalName" SG_ 543 ST_AVAI_CHAIN_BRG "ST_AVAI_CHAIN_BRG";
BA_ "LongName" SG_ 543 ST_AVAI_CHAIN_BRG "Status_Verfügbarkeit_Kette_Bremsung";
BA_ "SysSignalName" SG_ 543 ST_AVAI_CHAIN_BRG "ST_AVAI_CHAIN_BRG";
BA_ "CompuMethodName" SG_ 543 ST_AVAI_CHAIN_WARN "ST_AVAI_CHAIN_WARN";
BA_ "ISignalName" SG_ 543 ST_AVAI_CHAIN_WARN "ST_AVAI_CHAIN_WARN";
BA_ "LongName" SG_ 543 ST_AVAI_CHAIN_WARN "Status_Verfügbarkeit_Kette_Warnung";
BA_ "SysSignalName" SG_ 543 ST_AVAI_CHAIN_WARN "ST_AVAI_CHAIN_WARN";
BA_ "CompuMethodName" SG_ 543 ALIV_ST_OBJ_COOR "ALIV_ST_OBJ_COOR";
BA_ "ISignalName" SG_ 543 ALIV_ST_OBJ_COOR "ALIV_ST_OBJ_COOR";
BA_ "LongName" SG_ 543 ALIV_ST_OBJ_COOR "Alive_Status_Objekt_Koordination";
BA_ "SysSignalName" SG_ 543 ALIV_ST_OBJ_COOR "ALIV_ST_OBJ_COOR";
BA_ "CompuMethodName" SG_ 783 SRC_TR_TeleX "SRC_TR_TS";
BA_ "ISignalName" SG_ 783 SRC_TR_TeleX "SRC_TR_TeleX";
BA_ "LongName" SG_ 783 SRC_TR_TeleX "Quelle_Trigger_TeleX";
BA_ "SysSignalName" SG_ 783 SRC_TR_TeleX "SRC_TR_TeleX";
BA_ "CompuMethodName" SG_ 783 AVAI_SER_TeleX "AVAI_SER_TS";
BA_ "ISignalName" SG_ 783 AVAI_SER_TeleX "AVAI_SER_TeleX";
BA_ "LongName" SG_ 783 AVAI_SER_TeleX "Verfügbarkeit_Service_TeleX";
BA_ "SysSignalName" SG_ 783 AVAI_SER_TeleX "AVAI_SER_TeleX";
BA_ "CompuMethodName" SG_ 783 ST_SER_CALL_TeleX "ST_SER_CALL_TS";
BA_ "ISignalName" SG_ 783 ST_SER_CALL_TeleX "ST_SER_CALL_TeleX";
BA_ "LongName" SG_ 783 ST_SER_CALL_TeleX "Status_Service_Call_TeleX";
BA_ "SysSignalName" SG_ 783 ST_SER_CALL_TeleX "ST_SER_CALL_TeleX";
BA_ "CompuMethodName" SG_ 594 PO_WIBL "PO_WIBL";
BA_ "ISignalName" SG_ 594 PO_WIBL "PO_WIBL";
BA_ "LongName" SG_ 594 PO_WIBL "Position_Wischerblatt";
BA_ "SysSignalName" SG_ 594 PO_WIBL "PO_WIBL";
BA_ "CompuMethodName" SG_ 764 ST_CLSY "ST_CLSY";
BA_ "ISignalName" SG_ 764 ST_CLSY "ST_CLSY";
BA_ "LongName" SG_ 764 ST_CLSY "Status_Zentralverriegelung";
BA_ "SysSignalName" SG_ 764 ST_CLSY "ST_CLSY";
BA_ "CompuMethodName" SG_ 764 CTR_CLSY "CTR_CLSY";
BA_ "ISignalName" SG_ 764 CTR_CLSY "CTR_CLSY";
BA_ "LongName" SG_ 764 CTR_CLSY "Steuerung_Zentralverriegelung";
BA_ "SysSignalName" SG_ 764 CTR_CLSY "CTR_CLSY";
BA_ "CompuMethodName" SG_ 764 ST_DSW_DRD "ENUM_2_noIniVal_noDflVal_3_noQuant_noOffs_typeBitField_noRng_127";
BA_ "ISignalName" SG_ 764 ST_DSW_DRD "ST_DSW_DRD";
BA_ "LongName" SG_ 764 ST_DSW_DRD "Status_Türkontakt_FAT";
BA_ "SysSignalName" SG_ 764 ST_DSW_DRD "ST_DSW_DRD";
BA_ "CompuMethodName" SG_ 764 ST_DSW_PSD "ST_DSW_PSD";
BA_ "ISignalName" SG_ 764 ST_DSW_PSD "ST_DSW_PSD";
BA_ "LongName" SG_ 764 ST_DSW_PSD "Status_Türkontakt_BFT";
BA_ "SysSignalName" SG_ 764 ST_DSW_PSD "ST_DSW_PSD";
BA_ "CompuMethodName" SG_ 764 ST_DSW_DVDR "ENUM_2_noIniVal_noDflVal_3_noQuant_noOffs_typeBitField_noRng_125";
BA_ "ISignalName" SG_ 764 ST_DSW_DVDR "ST_DSW_DVDR";
BA_ "LongName" SG_ 764 ST_DSW_DVDR "Status_Türkontakt_FATH";
BA_ "SysSignalName" SG_ 764 ST_DSW_DVDR "ST_DSW_DVDR";
BA_ "CompuMethodName" SG_ 764 ST_DSW_PSDR "ENUM_2_noIniVal_noDflVal_3_noQuant_noOffs_typeBitField_noRng_124";
BA_ "ISignalName" SG_ 764 ST_DSW_PSDR "ST_DSW_PSDR";
BA_ "LongName" SG_ 764 ST_DSW_PSDR "Status_Türkontakt_BFTH";
BA_ "SysSignalName" SG_ 764 ST_DSW_PSDR "ST_DSW_PSDR";
BA_ "CompuMethodName" SG_ 764 ST_CT_BTL "ST_CT_BTL";
BA_ "ISignalName" SG_ 764 ST_CT_BTL "ST_CT_BTL";
BA_ "LongName" SG_ 764 ST_CT_BTL "Status_Kontakt_Heckklappe";
BA_ "SysSignalName" SG_ 764 ST_CT_BTL "ST_CT_BTL";
BA_ "CompuMethodName" SG_ 764 ST_CT_BON "ST_CT_BON";
BA_ "ISignalName" SG_ 764 ST_CT_BON "ST_CT_BON";
BA_ "LongName" SG_ 764 ST_CT_BON "Status_Kontakt_Motorhaube";
BA_ "SysSignalName" SG_ 764 ST_CT_BON "ST_CT_BON";
BA_ "CompuMethodName" SG_ 764 ST_HOTM "ENUM_2_noIniVal_noDflVal_3_noQuant_noOffs_typeBitField_noRng_88";
BA_ "ISignalName" SG_ 764 ST_HOTM "ST_HOTM";
BA_ "LongName" SG_ 764 ST_HOTM "Status_Hotelstellung";
BA_ "SysSignalName" SG_ 764 ST_HOTM "ST_HOTM";
BA_ "CompuMethodName" SG_ 764 ST_PUBU_CLSY "ST_PUBU_CLSY";
BA_ "ISignalName" SG_ 764 ST_PUBU_CLSY "ST_PUBU_CLSY";
BA_ "LongName" SG_ 764 ST_PUBU_CLSY "Status_Taster_Zentralverriegelung";
BA_ "SysSignalName" SG_ 764 ST_PUBU_CLSY "ST_PUBU_CLSY";
BA_ "CompuMethodName" SG_ 764 ST_CT_FLAP_2 "ST_CT_FLAP_2";
BA_ "ISignalName" SG_ 764 ST_CT_FLAP_2 "ST_CT_FLAP_2";
BA_ "LongName" SG_ 764 ST_CT_FLAP_2 "Status_Kontakt_Klappe_2";
BA_ "SysSignalName" SG_ 764 ST_CT_FLAP_2 "ST_CT_FLAP_2";
BA_ "CompuMethodName" SG_ 764 ST_CT_SCA "ST_CT_SCA";
BA_ "ISignalName" SG_ 764 ST_CT_SCA "ST_CT_SCA";
BA_ "LongName" SG_ 764 ST_CT_SCA "Status_Kontakt_Soft-Close-Automatik";
BA_ "SysSignalName" SG_ 764 ST_CT_SCA "ST_CT_SCA";
BA_ "CompuMethodName" SG_ 764 ST_CLSY_BTL "ST_CLSY_BTL";
BA_ "ISignalName" SG_ 764 ST_CLSY_BTL "ST_CLSY_BTL";
BA_ "LongName" SG_ 764 ST_CLSY_BTL "Status_Zentralverriegelung_Heckklappe";
BA_ "SysSignalName" SG_ 764 ST_CLSY_BTL "ST_CLSY_BTL";
BA_ "CompuMethodName" SG_ 719 ST_AUWP "ST_AUWP";
BA_ "ISignalName" SG_ 719 ST_AUWP "ST_AUWP";
BA_ "LongName" SG_ 719 ST_AUWP "Status_Zusatzwasserpumpe";
BA_ "SysSignalName" SG_ 719 ST_AUWP "ST_AUWP";
BA_ "CompuMethodName" SG_ 770 CRC_STEA_FTAX_EFFV "CRC8";
BA_ "ISignalName" SG_ 770 CRC_STEA_FTAX_EFFV "CRC_STEA_FTAX_EFFV";
BA_ "LongName" SG_ 770 CRC_STEA_FTAX_EFFV "CRC_Lenkwinkel_Vorderachse_effektiv";
BA_ "SysSignalName" SG_ 770 CRC_STEA_FTAX_EFFV "CRC_STEA_FTAX_EFFV";
BA_ "CompuMethodName" SG_ 770 ALIV_STEA_FTAX_EFFV "Aliv_4";
BA_ "ISignalName" SG_ 770 ALIV_STEA_FTAX_EFFV "ALIV_STEA_FTAX_EFFV";
BA_ "LongName" SG_ 770 ALIV_STEA_FTAX_EFFV "Alive_Lenkwinkel_Vorderachse_effektiv";
BA_ "SysSignalName" SG_ 770 ALIV_STEA_FTAX_EFFV "ALIV_STEA_FTAX_EFFV";
BA_ "CompuMethodName" SG_ 770 ST_ECU_STEA_FTAX_EFFV "ST_ECU";
BA_ "ISignalName" SG_ 770 ST_ECU_STEA_FTAX_EFFV "ST_ECU_STEA_FTAX_EFFV";
BA_ "LongName" SG_ 770 ST_ECU_STEA_FTAX_EFFV "Status_STG_Lenkwinkel_Vorderachse_effektiv";
BA_ "SysSignalName" SG_ 770 ST_ECU_STEA_FTAX_EFFV "ST_ECU_STEA_FTAX_EFFV";
BA_ "CompuMethodName" SG_ 770 STEA_FTAX_EFFV "AVL_STEA_FTAX";
BA_ "GenSigStartValue" SG_ 770 STEA_FTAX_EFFV -90;
BA_ "ISignalName" SG_ 770 STEA_FTAX_EFFV "STEA_FTAX_EFFV";
BA_ "LongName" SG_ 770 STEA_FTAX_EFFV "Lenkwinkel_Vorderachse_effektiv";
BA_ "SysSignalName" SG_ 770 STEA_FTAX_EFFV "STEA_FTAX_EFFV";
BA_ "CompuMethodName" SG_ 770 QU_STEA_FTAX_EFFV "QU_STEA_FTAX_effektiv2";
BA_ "ISignalName" SG_ 770 QU_STEA_FTAX_EFFV "QU_STEA_FTAX_EFFV";
BA_ "LongName" SG_ 770 QU_STEA_FTAX_EFFV "Qualifier_Lenkwinkel_Vorderachse_effektiv";
BA_ "SysSignalName" SG_ 770 QU_STEA_FTAX_EFFV "QU_STEA_FTAX_EFFV";
BA_ "CompuMethodName" SG_ 770 ST_CON_STEA "ST_CON_STEA";
BA_ "ISignalName" SG_ 770 ST_CON_STEA "ST_CON_STEA";
BA_ "LongName" SG_ 770 ST_CON_STEA "Status_Zustand_Lenkwinkel";
BA_ "SysSignalName" SG_ 770 ST_CON_STEA "ST_CON_STEA";
BA_ "CompuMethodName" SG_ 770 STEA_FTAX_EFFV_ERR_AMP "STEA_FTAX_EFFV_ERR_AMP";
BA_ "ISignalName" SG_ 770 STEA_FTAX_EFFV_ERR_AMP "STEA_FTAX_EFFV_ERR_AMP";
BA_ "LongName" SG_ 770 STEA_FTAX_EFFV_ERR_AMP "Lenkwinkel_Vorderachse_effektiv_Fehler_Amplitude";
BA_ "SysSignalName" SG_ 770 STEA_FTAX_EFFV_ERR_AMP "STEA_FTAX_EFFV_ERR_AMP";
BA_ "CompuMethodName" SG_ 756 ST_CONN_HSFZ "ST_CONN_HSFZ";
BA_ "ISignalName" SG_ 756 ST_CONN_HSFZ "ST_CONN_HSFZ";
BA_ "LongName" SG_ 756 ST_CONN_HSFZ "Status_Verbindung_High-Speed-Fahrzeugzugang";
BA_ "SysSignalName" SG_ 756 ST_CONN_HSFZ "ST_CONN_HSFZ";
BA_ "CompuMethodName" SG_ 756 ST_ACTVN_WR_HSFZ "ST_ACTVN_WR_HSFZ";
BA_ "ISignalName" SG_ 756 ST_ACTVN_WR_HSFZ "ST_ACTVN_WR_HSFZ";
BA_ "LongName" SG_ 756 ST_ACTVN_WR_HSFZ "Status_Aktivierung_Leitung_High-Speed-Fahrzeugzugang";
BA_ "SysSignalName" SG_ 756 ST_ACTVN_WR_HSFZ "ST_ACTVN_WR_HSFZ";
BA_ "CompuMethodName" SG_ 957 ST_FN_BUT_2_MIKO "ST_FN_BUT_2_MIKO";
BA_ "ISignalName" SG_ 957 ST_FN_BUT_2_MIKO "ST_FN_BUT_2_MIKO";
BA_ "LongName" SG_ 957 ST_FN_BUT_2_MIKO "Status_Funktion_Taste_2_MIKO";
BA_ "SysSignalName" SG_ 957 ST_FN_BUT_2_MIKO "ST_FN_BUT_2_MIKO";
BA_ "CompuMethodName" SG_ 957 ST_FN_BUT_3_MIKO "ST_FN_BUT_3_MIKO";
BA_ "ISignalName" SG_ 957 ST_FN_BUT_3_MIKO "ST_FN_BUT_3_MIKO";
BA_ "LongName" SG_ 957 ST_FN_BUT_3_MIKO "Status_Funktion_Taste_3_MIKO";
BA_ "SysSignalName" SG_ 957 ST_FN_BUT_3_MIKO "ST_FN_BUT_3_MIKO";
BA_ "CompuMethodName" SG_ 957 ST_FN_BUT_4_MIKO "ST_FN_BUT_4_MIKO";
BA_ "ISignalName" SG_ 957 ST_FN_BUT_4_MIKO "ST_FN_BUT_4_MIKO";
BA_ "LongName" SG_ 957 ST_FN_BUT_4_MIKO "Status_Funktion_Taste_4_MIKO";
BA_ "SysSignalName" SG_ 957 ST_FN_BUT_4_MIKO "ST_FN_BUT_4_MIKO";
BA_ "CompuMethodName" SG_ 957 ST_FN_BUT_5_MIKO "ST_FN_BUT_5_MIKO";
BA_ "ISignalName" SG_ 957 ST_FN_BUT_5_MIKO "ST_FN_BUT_5_MIKO";
BA_ "LongName" SG_ 957 ST_FN_BUT_5_MIKO "Status_Funktion_Taste_5_MIKO";
BA_ "SysSignalName" SG_ 957 ST_FN_BUT_5_MIKO "ST_FN_BUT_5_MIKO";
BA_ "CompuMethodName" SG_ 957 ST_FN_BUT_9_MIKO "ST_FN_BUT_9_MIKO";
BA_ "ISignalName" SG_ 957 ST_FN_BUT_9_MIKO "ST_FN_BUT_9_MIKO";
BA_ "LongName" SG_ 957 ST_FN_BUT_9_MIKO "Status_Funktion_Taste_9_MIKO";
BA_ "SysSignalName" SG_ 957 ST_FN_BUT_9_MIKO "ST_FN_BUT_9_MIKO";
BA_ "CompuMethodName" SG_ 663 CRC_ST_BLT_CT_SOCCU "CRC8";
BA_ "ISignalName" SG_ 663 CRC_ST_BLT_CT_SOCCU "CRC_ST_BLT_CT_SOCCU";
BA_ "LongName" SG_ 663 CRC_ST_BLT_CT_SOCCU "CRC_Status_Gurt_Kontakt_Sitzbelegung";
BA_ "SysSignalName" SG_ 663 CRC_ST_BLT_CT_SOCCU "CRC_ST_BLT_CT_SOCCU";
BA_ "CompuMethodName" SG_ 663 ALIV_COU_ST_BLT_CT_SOCCU "Aliv_4";
BA_ "ISignalName" SG_ 663 ALIV_COU_ST_BLT_CT_SOCCU "ALIV_COU_ST_BLT_CT_SOCCU";
BA_ "LongName" SG_ 663 ALIV_COU_ST_BLT_CT_SOCCU "Alive_Zähler_Status_Gurt_Kontakt_Sitzbelegung";
BA_ "SysSignalName" SG_ 663 ALIV_COU_ST_BLT_CT_SOCCU "ALIV_COU_ST_BLT_CT_SOCCU";
BA_ "CompuMethodName" SG_ 663 ST_ERR_SEAT_MT_DR "ST_ERR_SEAT_MT";
BA_ "ISignalName" SG_ 663 ST_ERR_SEAT_MT_DR "ST_ERR_SEAT_MT_DR";
BA_ "LongName" SG_ 663 ST_ERR_SEAT_MT_DR "Status_Fehler_Sitz_Matte_FA";
BA_ "SysSignalName" SG_ 663 ST_ERR_SEAT_MT_DR "ST_ERR_SEAT_MT_DR";
BA_ "ISignalName" SG_ 663 ST_BLT_CT_SOCCU_dummy_15_15 "ST_BLT_CT_SOCCU_dummy_15_15";
BA_ "LongName" SG_ 663 ST_BLT_CT_SOCCU_dummy_15_15 "ST_BLT_CT_SOCCU_dummy_15_15";
BA_ "SysSignalName" SG_ 663 ST_BLT_CT_SOCCU_dummy_15_15 "ST_BLT_CT_SOCCU_dummy_15_15";
BA_ "CompuMethodName" SG_ 663 ST_BLTB_SW_DR "ST_BLTB_SW";
BA_ "ISignalName" SG_ 663 ST_BLTB_SW_DR "ST_BLTB_SW_DR";
BA_ "LongName" SG_ 663 ST_BLTB_SW_DR "Status_Gurtschloß_Schalter_FA";
BA_ "SysSignalName" SG_ 663 ST_BLTB_SW_DR "ST_BLTB_SW_DR";
BA_ "CompuMethodName" SG_ 663 ST_SEAT_OCCU_DR "ST_SEAT_OCCU";
BA_ "ISignalName" SG_ 663 ST_SEAT_OCCU_DR "ST_SEAT_OCCU_DR";
BA_ "LongName" SG_ 663 ST_SEAT_OCCU_DR "Status_Sitz_Belegung_FA";
BA_ "SysSignalName" SG_ 663 ST_SEAT_OCCU_DR "ST_SEAT_OCCU_DR";
BA_ "CompuMethodName" SG_ 663 ST_SEAT_OCCU_3_LH_TIR_RS "ST_SEAT_OCCU_3";
BA_ "ISignalName" SG_ 663 ST_SEAT_OCCU_3_LH_TIR_RS "ST_SEAT_OCCU_3_LH_TIR_RS";
BA_ "LongName" SG_ 663 ST_SEAT_OCCU_3_LH_TIR_RS "status_seat_occupancy_3_lefthand_tiers_rearseat";
BA_ "SysSignalName" SG_ 663 ST_SEAT_OCCU_3_LH_TIR_RS "ST_SEAT_OCCU_3_LH_TIR_RS";
BA_ "CompuMethodName" SG_ 663 ST_BLTB_SW_PS "ST_BLTB_SW";
BA_ "ISignalName" SG_ 663 ST_BLTB_SW_PS "ST_BLTB_SW_PS";
BA_ "LongName" SG_ 663 ST_BLTB_SW_PS "Status_Gurtschloß_Schalter_BF";
BA_ "SysSignalName" SG_ 663 ST_BLTB_SW_PS "ST_BLTB_SW_PS";
BA_ "CompuMethodName" SG_ 663 ST_SEAT_OCCU_PS "ST_SEAT_OCCU_PS";
BA_ "ISignalName" SG_ 663 ST_SEAT_OCCU_PS "ST_SEAT_OCCU_PS";
BA_ "LongName" SG_ 663 ST_SEAT_OCCU_PS "Status_Sitz_Belegung_BF";
BA_ "SysSignalName" SG_ 663 ST_SEAT_OCCU_PS "ST_SEAT_OCCU_PS";
BA_ "CompuMethodName" SG_ 663 ST_SEAT_OCCU_3_MID_TIR_RS "ST_SEAT_OCCU_3";
BA_ "ISignalName" SG_ 663 ST_SEAT_OCCU_3_MID_TIR_RS "ST_SEAT_OCCU_3_MID_TIR_RS";
BA_ "LongName" SG_ 663 ST_SEAT_OCCU_3_MID_TIR_RS "status_seat_occupancy_3_mid_tiers_rearseat";
BA_ "SysSignalName" SG_ 663 ST_SEAT_OCCU_3_MID_TIR_RS "ST_SEAT_OCCU_3_MID_TIR_RS";
BA_ "CompuMethodName" SG_ 663 ST_BLTB_SW_RLH "ST_BLTB_SW";
BA_ "ISignalName" SG_ 663 ST_BLTB_SW_RLH "ST_BLTB_SW_RLH";
BA_ "LongName" SG_ 663 ST_BLTB_SW_RLH "Status_Gurtschloß_Schalter_HL";
BA_ "SysSignalName" SG_ 663 ST_BLTB_SW_RLH "ST_BLTB_SW_RLH";
BA_ "CompuMethodName" SG_ 663 ST_SEAT_OCCU_RLH "ST_SEAT_OCCU";
BA_ "ISignalName" SG_ 663 ST_SEAT_OCCU_RLH "ST_SEAT_OCCU_RLH";
BA_ "LongName" SG_ 663 ST_SEAT_OCCU_RLH "Status_Sitz_Belegung_HL";
BA_ "SysSignalName" SG_ 663 ST_SEAT_OCCU_RLH "ST_SEAT_OCCU_RLH";
BA_ "CompuMethodName" SG_ 663 ST_SEAT_OCCU_3_RH_TIR_RS "ST_SEAT_OCCU_3";
BA_ "ISignalName" SG_ 663 ST_SEAT_OCCU_3_RH_TIR_RS "ST_SEAT_OCCU_3_RH_TIR_RS";
BA_ "LongName" SG_ 663 ST_SEAT_OCCU_3_RH_TIR_RS "status_seat_occupancy_3_righthand_tiers_rearseat";
BA_ "SysSignalName" SG_ 663 ST_SEAT_OCCU_3_RH_TIR_RS "ST_SEAT_OCCU_3_RH_TIR_RS";
BA_ "CompuMethodName" SG_ 663 ST_BLTB_SW_RRH "ST_BLTB_SW";
BA_ "ISignalName" SG_ 663 ST_BLTB_SW_RRH "ST_BLTB_SW_RRH";
BA_ "LongName" SG_ 663 ST_BLTB_SW_RRH "Status_Gurtschloß_Schalter_HR";
BA_ "SysSignalName" SG_ 663 ST_BLTB_SW_RRH "ST_BLTB_SW_RRH";
BA_ "CompuMethodName" SG_ 663 ST_SEAT_OCCU_RRH "ST_SEAT_OCCU";
BA_ "ISignalName" SG_ 663 ST_SEAT_OCCU_RRH "ST_SEAT_OCCU_RRH";
BA_ "LongName" SG_ 663 ST_SEAT_OCCU_RRH "Status_Sitz_Belegung_HR";
BA_ "SysSignalName" SG_ 663 ST_SEAT_OCCU_RRH "ST_SEAT_OCCU_RRH";
BA_ "CompuMethodName" SG_ 663 ST_SEAT_OCCU_RM "ST_SEAT_OCCU_RM";
BA_ "ISignalName" SG_ 663 ST_SEAT_OCCU_RM "ST_SEAT_OCCU_RM";
BA_ "LongName" SG_ 663 ST_SEAT_OCCU_RM "Status_Sitz_Belegung_RM";
BA_ "SysSignalName" SG_ 663 ST_SEAT_OCCU_RM "ST_SEAT_OCCU_RM";
BA_ "CompuMethodName" SG_ 663 ST_BLTB_SW_RM "ST_BLTB_SW";
BA_ "ISignalName" SG_ 663 ST_BLTB_SW_RM "ST_BLTB_SW_RM";
BA_ "LongName" SG_ 663 ST_BLTB_SW_RM "Status_Gurtschloß_Schalter_HM";
BA_ "SysSignalName" SG_ 663 ST_BLTB_SW_RM "ST_BLTB_SW_RM";
BA_ "CompuMethodName" SG_ 663 ST_BLTB_SW_3_LH_TIR_RS "ST_BLTB_SW_3_TIR_RS";
BA_ "ISignalName" SG_ 663 ST_BLTB_SW_3_LH_TIR_RS "ST_BLTB_SW_3_LH_TIR_RS";
BA_ "LongName" SG_ 663 ST_BLTB_SW_3_LH_TIR_RS "Status_Gurtschloß_Schalter_3_Links_Sitzreihe_Hinten";
BA_ "SysSignalName" SG_ 663 ST_BLTB_SW_3_LH_TIR_RS "ST_BLTB_SW_3_LH_TIR_RS";
BA_ "CompuMethodName" SG_ 663 ST_BLTB_SW_3_RH_TIR_RS "ST_BLTB_SW_3_TIR_RS";
BA_ "ISignalName" SG_ 663 ST_BLTB_SW_3_RH_TIR_RS "ST_BLTB_SW_3_RH_TIR_RS";
BA_ "LongName" SG_ 663 ST_BLTB_SW_3_RH_TIR_RS "Status_Gurtschloß_Schalter_3_Rechts_Sitzreihe_Hinten";
BA_ "SysSignalName" SG_ 663 ST_BLTB_SW_3_RH_TIR_RS "ST_BLTB_SW_3_RH_TIR_RS";
BA_ "CompuMethodName" SG_ 663 ST_BLTB_SW_3_MID_TIR_RS "ST_BLTB_SW_3_TIR_RS";
BA_ "ISignalName" SG_ 663 ST_BLTB_SW_3_MID_TIR_RS "ST_BLTB_SW_3_MID_TIR_RS";
BA_ "LongName" SG_ 663 ST_BLTB_SW_3_MID_TIR_RS "Status_Gurtschloß_Schalter_3_Mitte_Sitzreihe_Hinten";
BA_ "SysSignalName" SG_ 663 ST_BLTB_SW_3_MID_TIR_RS "ST_BLTB_SW_3_MID_TIR_RS";
BA_ "CompuMethodName" SG_ 1200 CTR_12V_BN_FACT_ENERG_AVAI "CTR_BN_FACT_AVAI";
BA_ "ISignalName" SG_ 1200 CTR_12V_BN_FACT_ENERG_AVAI "CTR_12V_BN_FACT_ENERG_AVAI";
BA_ "LongName" SG_ 1200 CTR_12V_BN_FACT_ENERG_AVAI "Steuerung_12V_Bordnetz_Faktor_Energie_Verfügbarkeit";
BA_ "SysSignalName" SG_ 1200 CTR_12V_BN_FACT_ENERG_AVAI "CTR_12V_BN_FACT_ENERG_AVAI";
BA_ "CompuMethodName" SG_ 1200 CTR_12V_BN_FACT_PWR_AVAI "CTR_BN_FACT_AVAI";
BA_ "ISignalName" SG_ 1200 CTR_12V_BN_FACT_PWR_AVAI "CTR_12V_BN_FACT_PWR_AVAI";
BA_ "LongName" SG_ 1200 CTR_12V_BN_FACT_PWR_AVAI "Steuerung_12V_Bordnetz_Faktor_Leistung_Verfügbarkeit";
BA_ "SysSignalName" SG_ 1200 CTR_12V_BN_FACT_PWR_AVAI "CTR_12V_BN_FACT_PWR_AVAI";
BA_ "CompuMethodName" SG_ 1200 CTR_ENERG_COSP_VIRT_BT "CTR_ENERG_COSP_VIRT_BT";
BA_ "ISignalName" SG_ 1200 CTR_ENERG_COSP_VIRT_BT "CTR_ENERG_COSP_VIRT_BT";
BA_ "LongName" SG_ 1200 CTR_ENERG_COSP_VIRT_BT "Steuerung_Energie_Verbrauch_Virtuell_Batterie";
BA_ "SysSignalName" SG_ 1200 CTR_ENERG_COSP_VIRT_BT "CTR_ENERG_COSP_VIRT_BT";
BA_ "CompuMethodName" SG_ 1200 CTR_BN_FACT_ENERG_AVAI "CTR_BN_FACT_AVAI";
BA_ "ISignalName" SG_ 1200 CTR_BN_FACT_ENERG_AVAI "CTR_BN_FACT_ENERG_AVAI";
BA_ "LongName" SG_ 1200 CTR_BN_FACT_ENERG_AVAI "Steuerung_Bordnetz_Faktor_Energie_Verfügbarkeit";
BA_ "SysSignalName" SG_ 1200 CTR_BN_FACT_ENERG_AVAI "CTR_BN_FACT_ENERG_AVAI";
BA_ "CompuMethodName" SG_ 1200 CTR_BN_FACT_PWR_AVAI "CTR_BN_FACT_AVAI";
BA_ "ISignalName" SG_ 1200 CTR_BN_FACT_PWR_AVAI "CTR_BN_FACT_PWR_AVAI";
BA_ "LongName" SG_ 1200 CTR_BN_FACT_PWR_AVAI "Steuerung_Bordnetz_Faktor_Leistung_Verfügbarkeit";
BA_ "SysSignalName" SG_ 1200 CTR_BN_FACT_PWR_AVAI "CTR_BN_FACT_PWR_AVAI";
BA_ "CompuMethodName" SG_ 1200 SOC_THO_VIRT_BT "SOC_THO_VIRT_BT";
BA_ "ISignalName" SG_ 1200 SOC_THO_VIRT_BT "SOC_THO_VIRT_BT";
BA_ "LongName" SG_ 1200 SOC_THO_VIRT_BT "SOC_Schwelle_Virtuell_Batterie";
BA_ "SysSignalName" SG_ 1200 SOC_THO_VIRT_BT "SOC_THO_VIRT_BT";
BA_ "CompuMethodName" SG_ 834 ALIV_CABRF "Aliv_4";
BA_ "ISignalName" SG_ 834 ALIV_CABRF "ALIV_CABRF";
BA_ "LongName" SG_ 834 ALIV_CABRF "Alive_Cabrio-Dach";
BA_ "SysSignalName" SG_ 834 ALIV_CABRF "ALIV_CABRF";
BA_ "CompuMethodName" SG_ 834 ST_PO_CABRF "ST_PO_CABRF";
BA_ "ISignalName" SG_ 834 ST_PO_CABRF "ST_PO_CABRF";
BA_ "LongName" SG_ 834 ST_PO_CABRF "Status_Position_Cabrio-Dach";
BA_ "SysSignalName" SG_ 834 ST_PO_CABRF "ST_PO_CABRF";
BA_ "CompuMethodName" SG_ 834 ST_PO_CABRF_RETRF "ST_PO_CABRF_RETRF";
BA_ "ISignalName" SG_ 834 ST_PO_CABRF_RETRF "ST_PO_CABRF_RETRF";
BA_ "LongName" SG_ 834 ST_PO_CABRF_RETRF "Status_Position_Cabrio-Dach_Faltdach";
BA_ "SysSignalName" SG_ 834 ST_PO_CABRF_RETRF "ST_PO_CABRF_RETRF";
BA_ "CompuMethodName" SG_ 834 ST_OP_CABRF "ST_OP_CABRF";
BA_ "ISignalName" SG_ 834 ST_OP_CABRF "ST_OP_CABRF";
BA_ "LongName" SG_ 834 ST_OP_CABRF "Status_Bedienung_Cabrio-Dach";
BA_ "SysSignalName" SG_ 834 ST_OP_CABRF "ST_OP_CABRF";
BA_ "CompuMethodName" SG_ 834 ST_SRC_OP_CABRF "ST_SRC_OP_CABRF";
BA_ "ISignalName" SG_ 834 ST_SRC_OP_CABRF "ST_SRC_OP_CABRF";
BA_ "LongName" SG_ 834 ST_SRC_OP_CABRF "Status_Quelle_Bedienung_Cabrio-Dach";
BA_ "SysSignalName" SG_ 834 ST_SRC_OP_CABRF "ST_SRC_OP_CABRF";
BA_ "CompuMethodName" SG_ 834 ST_ACTI_CABRF "ST_ACTI_CABRF";
BA_ "ISignalName" SG_ 834 ST_ACTI_CABRF "ST_ACTI_CABRF";
BA_ "LongName" SG_ 834 ST_ACTI_CABRF "Status_Auslöser_Cabrio-Dach";
BA_ "SysSignalName" SG_ 834 ST_ACTI_CABRF "ST_ACTI_CABRF";
BA_ "CompuMethodName" SG_ 834 ST_RLS_BTL "ST_RLS_BTL";
BA_ "ISignalName" SG_ 834 ST_RLS_BTL "ST_RLS_BTL";
BA_ "LongName" SG_ 834 ST_RLS_BTL "Status_Freigabe_Heckklappe";
BA_ "SysSignalName" SG_ 834 ST_RLS_BTL "ST_RLS_BTL";
BA_ "ISignalName" SG_ 834 ST_CABRF_dummy_34_55 "ST_CABRF_dummy_34_55";
BA_ "LongName" SG_ 834 ST_CABRF_dummy_34_55 "ST_CABRF_dummy_34_55";
BA_ "SysSignalName" SG_ 834 ST_CABRF_dummy_34_55 "ST_CABRF_dummy_34_55";
BA_ "CompuMethodName" SG_ 834 CRC_ST_CABRF "CRC8";
BA_ "ISignalName" SG_ 834 CRC_ST_CABRF "CRC_ST_CABRF";
BA_ "LongName" SG_ 834 CRC_ST_CABRF "CRC_Status_Cabrio-Dach";
BA_ "SysSignalName" SG_ 834 CRC_ST_CABRF "CRC_ST_CABRF";
BA_ "CompuMethodName" SG_ 1079 CAM_CAL_OFFS_HRZTL "CAM_CAL_OFFS";
BA_ "GenSigStartValue" SG_ 1079 CAM_CAL_OFFS_HRZTL -5;
BA_ "ISignalName" SG_ 1079 CAM_CAL_OFFS_HRZTL "CAM_CAL_OFFS_HRZTL";
BA_ "LongName" SG_ 1079 CAM_CAL_OFFS_HRZTL "Kamera_Kalibrierung_Offset_Horizontal";
BA_ "SysSignalName" SG_ 1079 CAM_CAL_OFFS_HRZTL "CAM_CAL_OFFS_HRZTL";
BA_ "CompuMethodName" SG_ 1079 CAM_CAL_OFFS_VE "CAM_CAL_OFFS";
BA_ "GenSigStartValue" SG_ 1079 CAM_CAL_OFFS_VE -5;
BA_ "ISignalName" SG_ 1079 CAM_CAL_OFFS_VE "CAM_CAL_OFFS_VE";
BA_ "LongName" SG_ 1079 CAM_CAL_OFFS_VE "Kamera_Kalibrierung_Offset_Vertikal";
BA_ "SysSignalName" SG_ 1079 CAM_CAL_OFFS_VE "CAM_CAL_OFFS_VE";
BA_ "CompuMethodName" SG_ 1079 ST_CAM_CAL "ST_CAM_CAL";
BA_ "ISignalName" SG_ 1079 ST_CAM_CAL "ST_CAM_CAL";
BA_ "LongName" SG_ 1079 ST_CAM_CAL "Status_Kamera_Kalibrierung";
BA_ "SysSignalName" SG_ 1079 ST_CAM_CAL "ST_CAM_CAL";
BA_ "CompuMethodName" SG_ 50 CRC_ST_CENG "CRC8";
BA_ "ISignalName" SG_ 50 CRC_ST_CENG "CRC_ST_CENG";
BA_ "LongName" SG_ 50 CRC_ST_CENG "CRC_Status_Verbrennungsmotor";
BA_ "SysSignalName" SG_ 50 CRC_ST_CENG "CRC_ST_CENG";
BA_ "CompuMethodName" SG_ 50 ALIV_ST_CENG "ALIV_4_BIT_UInt";
BA_ "ISignalName" SG_ 50 ALIV_ST_CENG "ALIV_ST_CENG";
BA_ "LongName" SG_ 50 ALIV_ST_CENG "Alive_Status_Verbrennungsmotor";
BA_ "SysSignalName" SG_ 50 ALIV_ST_CENG "ALIV_ST_CENG";
BA_ "CompuMethodName" SG_ 50 StatusValvetrain "StatusValvetrain";
BA_ "ISignalName" SG_ 50 StatusValvetrain "StatusValvetrain";
BA_ "LongName" SG_ 50 StatusValvetrain "StatusValvetrain";
BA_ "SysSignalName" SG_ 50 StatusValvetrain "StatusValvetrain";
BA_ "CompuMethodName" SG_ 50 StatusElectricMode "StatusElectricMode";
BA_ "ISignalName" SG_ 50 StatusElectricMode "StatusElectricMode";
BA_ "LongName" SG_ 50 StatusElectricMode "StatusElectricMode";
BA_ "SysSignalName" SG_ 50 StatusElectricMode "StatusElectricMode";
BA_ "CompuMethodName" SG_ 50 ST_CENG_DRV "ST_CENG_DRV";
BA_ "ISignalName" SG_ 50 ST_CENG_DRV "ST_CENG_DRV";
BA_ "LongName" SG_ 50 ST_CENG_DRV "Status_Verbrennungsmotor_Antrieb";
BA_ "SysSignalName" SG_ 50 ST_CENG_DRV "ST_CENG_DRV";
BA_ "CompuMethodName" SG_ 50 ST_UDP "ST_UDP";
BA_ "ISignalName" SG_ 50 ST_UDP "ST_UDP";
BA_ "LongName" SG_ 50 ST_UDP "Status_Spannungseinbruch";
BA_ "SysSignalName" SG_ 50 ST_UDP "ST_UDP";
BA_ "CompuMethodName" SG_ 50 ST_ENERG_SUPY "ST_ENERG_SUPY";
BA_ "ISignalName" SG_ 50 ST_ENERG_SUPY "ST_ENERG_SUPY";
BA_ "LongName" SG_ 50 ST_ENERG_SUPY "Status_Energie_Versorgung";
BA_ "SysSignalName" SG_ 50 ST_ENERG_SUPY "ST_ENERG_SUPY";
BA_ "CompuMethodName" SG_ 50 ST_MOT_DRV "ST_MOT_DRV";
BA_ "ISignalName" SG_ 50 ST_MOT_DRV "ST_MOT_DRV";
BA_ "LongName" SG_ 50 ST_MOT_DRV "Status_E-Motor_Antrieb";
BA_ "SysSignalName" SG_ 50 ST_MOT_DRV "ST_MOT_DRV";
BA_ "CompuMethodName" SG_ 50 ST_ANO_MSA_ENG_STOP "ST_ANO_MSA_ENG_STOP";
BA_ "ISignalName" SG_ 50 ST_ANO_MSA_ENG_STOP "ST_ANO_MSA_ENG_STOP";
BA_ "LongName" SG_ 50 ST_ANO_MSA_ENG_STOP "Status_Ankündigung_MSA_Motor_Stop";
BA_ "SysSignalName" SG_ 50 ST_ANO_MSA_ENG_STOP "ST_ANO_MSA_ENG_STOP";
BA_ "CompuMethodName" SG_ 50 TR_HHASS_MSA "TR_HHASS_MSA";
BA_ "ISignalName" SG_ 50 TR_HHASS_MSA "TR_HHASS_MSA";
BA_ "LongName" SG_ 50 TR_HHASS_MSA "Trigger_Anfahrassistent_MSA";
BA_ "SysSignalName" SG_ 50 TR_HHASS_MSA "TR_HHASS_MSA";
BA_ "CompuMethodName" SG_ 50 CTR_LED_PUBU_MSA "CTR_LED_PUBU_MSA";
BA_ "ISignalName" SG_ 50 CTR_LED_PUBU_MSA "CTR_LED_PUBU_MSA";
BA_ "LongName" SG_ 50 CTR_LED_PUBU_MSA "Steuerung_LED_Taster_MSA";
BA_ "SysSignalName" SG_ 50 CTR_LED_PUBU_MSA "CTR_LED_PUBU_MSA";
BA_ "CompuMethodName" SG_ 50 PowertrainConfigurationAccelerat "PowertrainConfigurationAcceleratorPedalProgression";
BA_ "ISignalName" SG_ 50 PowertrainConfigurationAccelerat "PowertrainConfigurationAcceleratorPedalProgression";
BA_ "LongName" SG_ 50 PowertrainConfigurationAccelerat "PowertrainConfigurationAcceleratorPedalProgression";
BA_ "SysSignalName" SG_ 50 PowertrainConfigurationAccelerat "PowertrainConfigurationAcceleratorPedalProgression";
BA_ "SystemSignalLongSymbol" SG_ 50 PowertrainConfigurationAccelerat "PowertrainConfigurationAcceleratorPedalProgression";
BA_ "CompuMethodName" SG_ 50 PowertrainConfigurationLoadShock "PowertrainConfigurationLoadShockDamping";
BA_ "ISignalName" SG_ 50 PowertrainConfigurationLoadShock "PowertrainConfigurationLoadShockDamping";
BA_ "LongName" SG_ 50 PowertrainConfigurationLoadShock "PowertrainConfigurationLoadShockDamping";
BA_ "SysSignalName" SG_ 50 PowertrainConfigurationLoadShock "PowertrainConfigurationLoadShockDamping";
BA_ "SystemSignalLongSymbol" SG_ 50 PowertrainConfigurationLoadShock "PowertrainConfigurationLoadShockDamping";
BA_ "CompuMethodName" SG_ 50 PowertrainConfigurationDashpot "PowertrainConfigurationDashpot";
BA_ "ISignalName" SG_ 50 PowertrainConfigurationDashpot "PowertrainConfigurationDashpot";
BA_ "LongName" SG_ 50 PowertrainConfigurationDashpot "PowertrainConfigurationDashpot";
BA_ "SysSignalName" SG_ 50 PowertrainConfigurationDashpot "PowertrainConfigurationDashpot";
BA_ "CompuMethodName" SG_ 50 PowertrainConfigurationGearbox "PowertrainConfigurationGearbox";
BA_ "ISignalName" SG_ 50 PowertrainConfigurationGearbox "PowertrainConfigurationGearbox";
BA_ "LongName" SG_ 50 PowertrainConfigurationGearbox "PowertrainConfigurationGearbox";
BA_ "SysSignalName" SG_ 50 PowertrainConfigurationGearbox "PowertrainConfigurationGearbox";
BA_ "ISignalName" SG_ 50 ST_CENG_dummy_56_63 "ST_CENG_dummy_56_63";
BA_ "LongName" SG_ 50 ST_CENG_dummy_56_63 "ST_CENG_dummy_56_63";
BA_ "SysSignalName" SG_ 50 ST_CENG_dummy_56_63 "ST_CENG_dummy_56_63";
BA_ "CompuMethodName" SG_ 948 ST_CHGWR_PLGD "ST_CHGWR_PLGD";
BA_ "ISignalName" SG_ 948 ST_CHGWR_PLGD "ST_CHGWR_PLGD";
BA_ "LongName" SG_ 948 ST_CHGWR_PLGD "Status_Ladeleitung_Steckt";
BA_ "SysSignalName" SG_ 948 ST_CHGWR_PLGD "ST_CHGWR_PLGD";
BA_ "CompuMethodName" SG_ 948 ST_LOKG_CHGP "ST_LOKG_CHGP";
BA_ "ISignalName" SG_ 948 ST_LOKG_CHGP "ST_LOKG_CHGP";
BA_ "LongName" SG_ 948 ST_LOKG_CHGP "Status_Verriegelung_Ladestecker";
BA_ "SysSignalName" SG_ 948 ST_LOKG_CHGP "ST_LOKG_CHGP";
BA_ "CompuMethodName" SG_ 948 ST_PIL "ST_PIL";
BA_ "ISignalName" SG_ 948 ST_PIL "ST_PIL";
BA_ "LongName" SG_ 948 ST_PIL "Status_Pilot";
BA_ "SysSignalName" SG_ 948 ST_PIL "ST_PIL";
BA_ "CompuMethodName" SG_ 948 ST_DC_CHGWR_PLGD "ST_DC_CHGWR_PLGD";
BA_ "ISignalName" SG_ 948 ST_DC_CHGWR_PLGD "ST_DC_CHGWR_PLGD";
BA_ "LongName" SG_ 948 ST_DC_CHGWR_PLGD "Status_Gleichstrom_Ladeleitung_Steckt";
BA_ "SysSignalName" SG_ 948 ST_DC_CHGWR_PLGD "ST_DC_CHGWR_PLGD";
BA_ "CompuMethodName" SG_ 948 DisplayPositionPlug "DisplayPositionPlug";
BA_ "ISignalName" SG_ 948 DisplayPositionPlug "DisplayPositionPlug";
BA_ "LongName" SG_ 948 DisplayPositionPlug "DisplayPositionPlug";
BA_ "SysSignalName" SG_ 948 DisplayPositionPlug "DisplayPositionPlug";
BA_ "CompuMethodName" SG_ 948 CHGNG_TYP_IMME "CHGNG_TYP_IMME";
BA_ "ISignalName" SG_ 948 CHGNG_TYP_IMME "CHGNG_TYP_IMME";
BA_ "LongName" SG_ 948 CHGNG_TYP_IMME "Laden_Typ_Aktuell";
BA_ "SysSignalName" SG_ 948 CHGNG_TYP_IMME "CHGNG_TYP_IMME";
BA_ "CompuMethodName" SG_ 581 ST_RCOG_CHGSTN_IDT_CHGNG "ST_RCOG_CHGSTN_IDT_CHGNG";
BA_ "ISignalName" SG_ 581 ST_RCOG_CHGSTN_IDT_CHGNG "ST_RCOG_CHGSTN_IDT_CHGNG";
BA_ "LongName" SG_ 581 ST_RCOG_CHGSTN_IDT_CHGNG "Status_Erkennung_Ladestation_Induktiv_Laden";
BA_ "SysSignalName" SG_ 581 ST_RCOG_CHGSTN_IDT_CHGNG "ST_RCOG_CHGSTN_IDT_CHGNG";
BA_ "CompuMethodName" SG_ 581 ST_CONN_CHGSTN_IDT_CHGNG "ST_CONN_CHGSTN_IDT_CHGNG";
BA_ "ISignalName" SG_ 581 ST_CONN_CHGSTN_IDT_CHGNG "ST_CONN_CHGSTN_IDT_CHGNG";
BA_ "LongName" SG_ 581 ST_CONN_CHGSTN_IDT_CHGNG "Status_Verbindung_Ladestation_Induktiv_Laden";
BA_ "SysSignalName" SG_ 581 ST_CONN_CHGSTN_IDT_CHGNG "ST_CONN_CHGSTN_IDT_CHGNG";
BA_ "CompuMethodName" SG_ 581 ST_CHA_1_CHGSTN_IDT_CHGNG "CHA_CHR_CHGSTN_IDT_CHGNG";
BA_ "ISignalName" SG_ 581 ST_CHA_1_CHGSTN_IDT_CHGNG "ST_CHA_1_CHGSTN_IDT_CHGNG";
BA_ "LongName" SG_ 581 ST_CHA_1_CHGSTN_IDT_CHGNG "Status_Buchstabe_1_Ladestation_Induktiv_Laden";
BA_ "SysSignalName" SG_ 581 ST_CHA_1_CHGSTN_IDT_CHGNG "ST_CHA_1_CHGSTN_IDT_CHGNG";
BA_ "CompuMethodName" SG_ 581 ST_CHA_2_CHGSTN_IDT_CHGNG "CHA_CHR_CHGSTN_IDT_CHGNG";
BA_ "ISignalName" SG_ 581 ST_CHA_2_CHGSTN_IDT_CHGNG "ST_CHA_2_CHGSTN_IDT_CHGNG";
BA_ "LongName" SG_ 581 ST_CHA_2_CHGSTN_IDT_CHGNG "status_character_2_charging-station_inductive_charging";
BA_ "SysSignalName" SG_ 581 ST_CHA_2_CHGSTN_IDT_CHGNG "ST_CHA_2_CHGSTN_IDT_CHGNG";
BA_ "CompuMethodName" SG_ 581 ST_CHA_3_CHGSTN_IDT_CHGNG "CHA_CHR_CHGSTN_IDT_CHGNG";
BA_ "ISignalName" SG_ 581 ST_CHA_3_CHGSTN_IDT_CHGNG "ST_CHA_3_CHGSTN_IDT_CHGNG";
BA_ "LongName" SG_ 581 ST_CHA_3_CHGSTN_IDT_CHGNG "Status_Buchstabe_3_Ladestation_Induktiv_Laden";
BA_ "SysSignalName" SG_ 581 ST_CHA_3_CHGSTN_IDT_CHGNG "ST_CHA_3_CHGSTN_IDT_CHGNG";
BA_ "CompuMethodName" SG_ 581 ST_CHA_4_CHGSTN_IDT_CHGNG "CHA_CHR_CHGSTN_IDT_CHGNG";
BA_ "ISignalName" SG_ 581 ST_CHA_4_CHGSTN_IDT_CHGNG "ST_CHA_4_CHGSTN_IDT_CHGNG";
BA_ "LongName" SG_ 581 ST_CHA_4_CHGSTN_IDT_CHGNG "Status_Buchstabe_4_Ladestation_Induktiv_Laden";
BA_ "SysSignalName" SG_ 581 ST_CHA_4_CHGSTN_IDT_CHGNG "ST_CHA_4_CHGSTN_IDT_CHGNG";
BA_ "CompuMethodName" SG_ 581 ST_CHA_5_CHGSTN_IDT_CHGNG "CHA_CHR_CHGSTN_IDT_CHGNG";
BA_ "ISignalName" SG_ 581 ST_CHA_5_CHGSTN_IDT_CHGNG "ST_CHA_5_CHGSTN_IDT_CHGNG";
BA_ "LongName" SG_ 581 ST_CHA_5_CHGSTN_IDT_CHGNG "Status_Buchstabe_5_Ladestation_Induktiv_Laden";
BA_ "SysSignalName" SG_ 581 ST_CHA_5_CHGSTN_IDT_CHGNG "ST_CHA_5_CHGSTN_IDT_CHGNG";
BA_ "CompuMethodName" SG_ 588 ST_CT_RSCR_LCL "ST_CT_RSCR_LCL";
BA_ "ISignalName" SG_ 588 ST_CT_RSCR_LCL "ST_CT_RSCR_LCL";
BA_ "LongName" SG_ 588 ST_CT_RSCR_LCL "status_contact_rear-screen_local";
BA_ "SysSignalName" SG_ 588 ST_CT_RSCR_LCL "ST_CT_RSCR_LCL";
VAL_ 841 RWDT_SEN_FLLV_FUTA_L 65534 "Gilt ab BN2020 außer für SP2009 (außer F25)." 65535 "Signal ungültig";
VAL_ 841 RWDT_SEN_FLLV_FUTA_R 65534 "Gilt ab SP2013 (ohne F15-F16, 444)" 65535 "Signal ungültig";
VAL_ 625 ID_RCOG_SL_CAM 13 "SIGNALTAG_FCTIF_NOT_AVAILABLE" 14 "Hinweis: Reserviert für funktionale Kennung Signal-Tag." 15 "Sendefunktion nicht in Betrieb";
VAL_ 625 ST_MEASMT_SL_CAM 0 "gemessen" 1 "praediziert" 13 "SIGNALTAG_FCTIF_NOT_AVAILABLE" 14 "Hinweis: Reserviert für funktionale Kennung Signal-Tag." 15 "Sendefunktion nicht in Betrieb";
VAL_ 625 XPO_RCOG_SL_CAM 253 "SIGNALTAG_FCTIF_NOT_AVAILABLE" 254 "Hinweis: Reserviert für funktionale Kennung Signal-Tag." 255 "Sendefunktion nicht in Betrieb";
VAL_ 625 PI_RCOG_SL_CAM 253 "SIGNALTAG_FCTIF_NOT_AVAILABLE" 254 "Hinweis: Reserviert für funktionale Kennung Signal-Tag." 255 "Sendefunktion nicht in Betrieb";
VAL_ 625 CRE_SL_CAM 13 "SIGNALTAG_FCTIF_NOT_AVAILABLE" 14 "Hinweis: Reserviert für funktionale Kennung Signal-Tag." 15 "Sendefunktion nicht in Betrieb";
VAL_ 625 CTY_SL_CAM 0 "unbekannt" 1 "durchgezogen" 2 "gestrichelt" 3 "Dreiecke" 13 "SIGNALTAG_FCTIF_NOT_AVAILABLE" 14 "Hinweis: Reserviert für funktionale Kennung Signal-Tag." 15 "Sendefunktion nicht in Betrieb";
VAL_ 614 TRLI_ID 61 "SIGNALTAG_FCTIF_NOT_AVAILABLE" 62 "SIGNALTAG_FCT_ERROR" 63 "Sendefunktion nicht in Betrieb";
VAL_ 614 TRLI_PO_X 253 "SIGNALTAG_FCTIF_NOT_AVAILABLE" 254 "SIGNALTAG_FCT_ERROR" 255 "Sendefunktion nicht in Betrieb";
VAL_ 614 TRLI_PO_Y 253 "SIGNALTAG_FCTIF_NOT_AVAILABLE" 254 "SIGNALTAG_FCT_ERROR" 255 "Sendefunktion nicht in Betrieb";
VAL_ 614 TRLI_PO_Z 253 "SIGNALTAG_FCTIF_NOT_AVAILABLE" 254 "SIGNALTAG_FCT_ERROR" 255 "Sendefunktion nicht in Betrieb";
VAL_ 614 TRLI_ST 0 "Ampel im Blickfeld." 1 "Ampel nicht mehr im Blickfeld, aber noch nicht passiert." 2 "Ampel nicht mehr im Blickfeld, da passiert." 3 "Ampel nicht mehr im Blickfeld, wird nie passiert wegen Richtungsänderung." 13 "SIGNALTAG_FCTIF_NOT_AVAILABLE" 14 "SIGNALTAG_FCT_ERROR" 15 "Sendefunktion nicht in Betrieb";
VAL_ 614 TRLI_ARRW 0 "Kein_Pfeil" 1 "Pfeil_links" 2 "Pfeil_geradeaus" 3 "Pfeil_rechts" 4 "Pfeil_geradeaus_und_links" 5 "Pfeil_geradeaus_und_rechts" 6 "Pfeil_schraeg_links" 7 "Pfeil_schraeg_rechts" 13 "SIGNALTAG_FCTIF_NOT_AVAILABLE" 14 "SIGNALTAG_FCT_ERROR" 15 "Sendefunktion nicht in Betrieb";
VAL_ 614 TRLI_IDC 0 "Ampel_blinkt_nicht" 1 "Ampel_blinkt" 13 "SIGNALTAG_FCTIF_NOT_AVAILABLE" 14 "SIGNALTAG_FCT_ERROR" 15 "Sendefunktion nicht in Betrieb";
VAL_ 614 TRLI_CL 0 "Ampel_ist_rot" 1 "Ampel_ist_gelb" 2 "Ampel_ist_gruen" 3 "Ampel_ist_rot_gelb" 13 "SIGNALTAG_FCTIF_NOT_AVAILABLE" 14 "SIGNALTAG_FCT_ERROR" 15 "Sendefunktion nicht in Betrieb";
VAL_ 614 QUAL_RCOG_TRLI 13 "SIGNALTAG_FCTIF_NOT_AVAILABLE" 14 "SIGNALTAG_FCT_ERROR" 15 "Sendefunktion nicht in Betrieb";
VAL_ 647 PRES_WDR_LIM_V 0 "nicht verfügbar" 1 "Beschränkung" 2 "Aufhebung" 3 "ungültig";
VAL_ 647 RCOG_NPA 0 "kein Überholverbot erkannt" 1 "Überholverbot PKW" 2 "Aufhebung Überholverbot PKW erkannt" 3 "Überholverbot PKW mit Anhänger erkannt" 4 "Aufhebung Überholverbot PKW mit Anhänger erkannt" 5 "Überholverbot LKW" 6 "Aufhebung Überholverbot LKW" 7 "Andere Überholverbote" 8 "Reserviert" 9 "Überholverbot Linksverkehr" 10 "Reserviert" 11 "Reserviert" 12 "Reserviert" 13 "Reserviert" 14 "NPI nicht verfügbar" 15 "Signal ungültig";
VAL_ 647 PRES_CLAS_LIM_V 0 "Aufhebung alles" 1 "5" 2 "10" 3 "15" 4 "20" 5 "25" 6 "30" 7 "35" 8 "40" 9 "45" 10 "50" 11 "55" 12 "60" 13 "65" 14 "70" 15 "75" 16 "80" 17 "85" 18 "90" 19 "95" 20 "100" 21 "105" 22 "110" 23 "115" 24 "120" 25 "125" 26 "130" 27 "135" 28 "140" 29 "145" 30 "150" 31 "Diese Codierung wird ab SP2018 (nicht KAFAS3) versendet. Anzeige eines Straßentyp-spezifischen Piktogramms" 32 "Diese Codierung wird ab SP2018 (nicht KAFAS3) versendet. Anzeige eines Straßentyp-spezifischen Piktogramms" 33 "Diese Codierung wird ab SP2018 (nicht KAFAS3) versendet. Anzeige eines Straßentyp-spezifischen Piktogramms" 34 "Diese Codierung wird ab SP2018 (nicht KAFAS3) versendet. Anzeige eines Straßentyp-spezifischen Piktogramms" 35 "Diese Codierung wird ab SP2015 versendet." 254 "nicht verfügbar" 255 "Signal ungültig";
VAL_ 647 NXT_CLAS_LIM_V 0 "Aufhebung alles" 1 "5" 2 "10" 3 "15" 4 "20" 5 "25" 6 "30" 7 "35" 8 "40" 9 "45" 10 "50" 11 "55" 12 "60" 13 "65" 14 "70" 15 "75" 16 "80" 17 "85" 18 "90" 19 "95" 20 "100" 21 "105" 22 "110" 23 "115" 24 "120" 25 "125" 26 "130" 27 "135" 28 "140" 29 "Gong_Anforderung_Speed_Limit_Wechsel" 30 "150" 254 "nicht verfügbar" 255 "Send function not in operation";
VAL_ 647 CNCD_TRSG 0 "ECE weiß" 1 "ECE gelb" 2 "US weiß" 3 "US gelb" 4 "Generische Anzeige" 5 "Gilt ab SP2015" 6 "Gilt ab SP2015" 7 "Gilt ab SP2015" 8 "Gilt ab SP2015" 9 "Gilt ab SP2015" 10 "Gilt ab SP2015" 14 "Anzeige des generischen Init Symbols" 15 "Anzeige des generischen Init Symbols";
VAL_ 647 UN_V_LIM 0 "km/h" 1 "MPH" 2 "nicht verfügbar" 3 "Signal ungültig";
VAL_ 647 ST_DT_MAT_CAM_ADAS 0 "nach dem Aufstarten bis zur ersten Kameraerkennung oder bis zum Empfang gültiger Navigationsdaten" 1 "Anzeige optisch erkannter Speedlimits" 2 "Anzeige von explizit in der Navigation hinterlegten Speedlimits" 3 "Anzeige von landes- und straßentypspezifischen Speedlimits" 4 "Anzeige optisch erkannter Speedlimits im sicheren Zustand" 5 "Anzeige optisch erkannter Speedlimits im unsicheren Zustand" 6 "Default-Wert nach Fahrzeugauslieferung/Neuprogrammierung bzw. Ablauf des TSM unsicheren Zustands" 7 "Signal ungültig";
VAL_ 647 DISP_SUPSI 0 "Kein Zusatzzeichen einblenden" 1 "Uhrsymbol" 2 "Regensymbol" 3 "Schneesymbol" 4 "Pfeil der nach links zeigt" 5 "Pfeil der nach rechts zeigt" 6 "Pfeil von bis. Diese Codierung wird ab SP2018 (nicht KAFAS3) versendet." 7 "DIST-Symbol. Diese Codierung wird ab SP2018 (nicht KAFAS3) versendet." 8 "Nebelsymbol. Diese Codierung wird ab SP2018 (nicht KAFAS3) versendet." 9 "Leeres Zusatzzeichen. Diese Codierung wird ab SP2018 (nicht KAFAS3) versendet." 10 "Ausrufezeichen. Diese Codierung wird ab SP2018 (nicht KAFAS3) versendet." 11 "Anhängersymbol. Diese Codierung wird ab SP2018 (nicht KAFAS3) versendet." 12 "Zonensymbol. Diese Codierung wird ab SP2018 (nicht KAFAS3) versendet." 13 "SIGNALTAG_FCTIF_NOT_AVAILABLE" 14 "SIGNALTAG_FCT_ERROR" 15 "Sendefunktion nicht in Betrieb";
VAL_ 647 CTR_SLI_WARN 0 "SLI Warnung wird nicht angefordert" 1 "SLI Warnung wird angefordert" 2 "SLI Warnung Stufe 2" 3 "Sendefunktion nicht in Betrieb";
VAL_ 607 TRSG_ID 13 "SIGNALTAG_FCTIF_NOT_AVAILABLE" 14 "SIGNALTAG_FCT_ERROR" 15 "Sendefunktion nicht in Betrieb";
VAL_ 607 TRSG_TYP 1 "NO_PASSING_SIGN" 2 "WITHDRAWAL_NO_PASSING_SIGN" 3 "WITHDRAWAL_SPEED_LIMIT" 4 "GENERAL_WITHDRAWAL" 5 "SPEED_LIMIT" 6 "WITHDRAWAL_SPEED_LIMIT_2_DIGITS" 7 "WITHDRAWAL_SPEED_LIMIT_3_DIGITS" 8 "MANDATORY_PASSING_LEFT" 9 "MANDATORY_PASSING_RIGHT" 10 "MANDATORY_PASSING_STRAIGHT" 11 "ROUNDABOUT_SIGN" 12 "NO_ENTRY" 13 "VEHICLES_PROHIBITED" 14 "MOTORWAY_START_OF" 15 "MOTORWAY_END_OF" 16 "EXPRESSWAY_START_OF" 17 "EXPRESSWAY_END_OF" 18 "TRAFFIC_CALMING_ZONE_START_OF" 19 "TRAFFIC_CALMING_ZONE_END_OF" 20 "STOP_SIGN" 21 "GIVE_WAY" 22 "PRIORITY_ROAD_START_OF" 23 "PRIORITY_ROAD_END_OF" 24 "DS_BEND_LEFT" 25 "DS_BEND_RIGHT" 26 "DS_DOUBLE_BEND_LEFT_FIRST" 27 "DS_DOUBLE_BEND_RIGHT_FIRST" 28 "DS_ROAD_NARROW_BOTH_SIDES" 29 "DS_ROAD_NARROW_LEFT_SIDE" 30 "DS_ROAD_NARROW_RIGHT_SIDE" 31 "DS_CROSS_ROAD" 32 "DS_CROSS_ROAD_SMALL_ROAD" 33 "DS_ROAD_FROM_LEFT__DEGREE" 34 "DS_ROAD_FROM_RIGHT__DEGREE" 35 "DS_ONE_BUMP" 36 "DS_TWO_BUMP" 37 "DS_CONCAVE" 38 "DS_TRAFFIC_JAM" 39 "DS_ROAD_WORKS" 40 "DS_RIGHT_DOWNWARDS" 41 "DS_RIGHT_UPWARDS" 42 "DS_TRAFFIC_LIGHT" 43 "DS_ANIMAL_CROSSING" 44 "DS_CHILDREN" 45 "DS_SNOW" 46 "DS_SPLIPPERY_ROAD" 47 "DS_GIVE_WAY_ROUNDABOUT" 48 "DS_WIND_FROM_SIDE" 49 "DS_PEDESTRIAN_CROSSING" 50 "DS_BYCICLE_CROSSING" 51 "DS_TRAIN_CROSS_WITHOUT_BARRIER" 52 "DS_TRAIN_CROSS_WITH_BARRIER" 53 "DS_GRAVEL" 54 "DS_TWO_WAY_TRAFFIC" 55 "CITY_LIMIT_START_OF" 56 "CITY_LIMIT_END_OF" 57 "CITY_LIMIT_START_END_OF" 58 "ENVIRONMENTAL_ZONE_START_OF" 59 "ENVIRONMENTAL_ZONE_END_OF" 60 "UNKNOWN" 61 "SIGNALTAG_FCTIF_NOT_AVAILABLE" 62 "Reserviert für funktionale Kennung Signal-Tag." 63 "Sendefunktion nicht in Betrieb";
VAL_ 607 TRSG_ADDON_TYP_1 1 "SS_RAIN" 2 "SS_FOG" 3 "SS_SNOW" 4 "SS_SNOW_RAIN" 5 "SS_TIME" 6 "SS_SCHOOL" 7 "SS_WEIGHT" 8 "SS_DISTANCE_IN" 9 "SS_DISTANCE_FOR" 10 "SS_L_ARROW" 11 "SS_R_ARROW" 12 "SS_L_BEND_ARROW" 13 "SS_R_BEND_ARROW" 14 "SS_TRUCK" 15 "SS_TRUCK_RESTRICTIVE" 16 "SS_HAZARDOUS" 17 "SS_TRAILER" 18 "SS_NIGHT" 19 "SS_ZONE" 20 "SS_STOP_WAY" 21 "SS_MOTORCYCLE" 22 "GENERIC_SUPPLEMENTAL" 61 "SIGNALTAG_FCTIF_NOT_AVAILABLE" 62 "Reserviert für funktionale Kennung Signal-Tag" 63 "Sendefunktion nicht in Betrieb";
VAL_ 607 TRSG_ADDON_TYP_2 1 "SS_RAIN" 2 "SS_FOG" 3 "SS_SNOW" 4 "SS_SNOW_RAIN" 5 "SS_TIME" 6 "SS_SCHOOL" 7 "SS_WEIGHT" 8 "SS_DISTANCE_IN" 9 "SS_DISTANCE_FOR" 10 "SS_L_ARROW" 11 "SS_R_ARROW" 12 "SS_L_BEND_ARROW" 13 "SS_R_BEND_ARROW" 14 "SS_TRUCK" 15 "SS_TRUCK_RESTRICTIVE" 16 "SS_HAZARDOUS" 17 "SS_TRAILER" 18 "SS_NIGHT" 19 "SS_ZONE" 20 "SS_STOP_WAY" 21 "SS_MOTORCYCLE" 22 "GENERIC_SUPPLEMENTAL" 61 "SIGNALTAG_FCTIF_NOT_AVAILABLE" 62 "Reserviert für funktionale Kennung Signal-Tag" 63 "Sendefunktion nicht in Betrieb";
VAL_ 607 QUAL_RCOG_TRSG 0 "Bad Quality" 1 "Medium Quality" 2 "Good Quality" 3 "Sendefunktion nicht in Betrieb";
VAL_ 607 TRSG_VL 61 "SIGNALTAG_FCTIF_NOT_AVAILABLE" 62 "SIGNALTAG_FCT_ERROR" 63 "Sendefunktion nicht in Betrieb";
VAL_ 607 V_LIM_UN 0 "Initialization / Status Unknown" 1 "km/h" 2 "mph" 3 "Sendefunktion nicht in Betrieb";
VAL_ 607 TRSG_PO_X 253 "SIGNALTAG_FCTIF_NOT_AVAILABLE" 254 "SIGNALTAG_FCT_ERROR" 255 "Sendefunktion nicht in Betrieb";
VAL_ 607 TRSG_PO_Y 253 "SIGNALTAG_FCTIF_NOT_AVAILABLE" 254 "SIGNALTAG_FCT_ERROR" 255 "Sendefunktion nicht in Betrieb";
VAL_ 607 TRSG_PO_Z 13 "SIGNALTAG_FCTIF_NOT_AVAILABLE" 14 "SIGNALTAG_FCT_ERROR" 15 "Sendefunktion nicht in Betrieb";
VAL_ 607 TRSG_ST 0 "track stopped - Track is not correctly finished" 1 "track is active, sign is still being tracked" 2 "track has ended, sign is no longer being tracked" 3 "track has ended, sign has been passed by vehicle" 4 "track is finished, no further changes to track data will take place" 5 "track is finished, but sign has not been passed by vehicle and track is not correctly finished" 13 "SIGNALTAG_FCTIF_NOT_AVAILABLE" 14 "SIGNALTAG_FCT_ERROR" 15 "Sendefunktion nicht in Betrieb";
VAL_ 916 ID2_RDA_INQY 68 "RDA-Anfrage" 72 "RDA-Datenablage" 255 "Signal ungültig";
VAL_ 916 IDEN_RDA_INQY 255 "Signal ungültig";
VAL_ 916 UTDT_RDA_INQY_1 255 "Signal ungültig";
VAL_ 916 UTDT_RDA_INQY_2 255 "Signal ungültig";
VAL_ 916 UTDT_RDA_INQY_3 255 "Signal ungültig";
VAL_ 916 UTDT_RDA_INQY_4 255 "Signal ungültig";
VAL_ 916 UTDT_RDA_INQY_5 255 "Signal ungültig";
VAL_ 916 UTDT_RDA_INQY_6 255 "Signal ungültig";
VAL_ 349 RQ_ILE_EMS 0 "Keine_Anforderung" 1 "Innenbeleuchtung_einschalten" 3 "Signal_unbefuellt";
VAL_ 349 RQ_CLSY_EMS 0 "Keine_Anforderung" 1 "Zentralverriegelung_oeffnen" 3 "Signal_unbefuellt";
VAL_ 891 RLS_COOL_HVSTO 0 "Kältemittelabsperrventil ist geschlossen zu halten" 1 "Freigabe zum Öffnen des Kältemittelabsperrventils" 2 "Systemfehler erkannt" 3 "Signal ungültig";
VAL_ 891 RQ_PAIC 0 "keine_Standkuehlung_Erhaltungskuehlung" 1 "Standkuehlung_Erhaltungskuehlung_aktiviert" 3 "Signal_ungueltig";
VAL_ 891 RQ_CSOV_HVSTO 0 "Keine Anforderung, Ventilansteuerung gemäss Festlegungen der Hochvoltbatteriekühlung" 1 "Anforderung zum Öffnen des Kältemittelabsperrventils" 2 "Anforderung zum Öffnen des Kältemittelabsperrventils mit Ansteuerung der Kühlmittelpumpe im Kühlkreislauf der Hochvoltspeicherkühlung (Kühlpfad offen bzw. Duplexbetrieb - nur E72)." 3 "Signal ungültig";
VAL_ 891 ST_FRT_AC 0 "PIA-Wert AC-Taster Aus" 1 "PIA-Wert AC-Taster Ein" 3 "Sendefunktion nicht in Betrieb";
VAL_ 891 EkmvCompressorRpm 253 "SIGNALTAG_FCTIF_NOT_AVAILABLE" 254 "SIGNALTAG_FCT_ERROR" 255 "Sendefunktion nicht in Betrieb";
VAL_ 735 RLS_PWR_COOL_BT_AIC 253 "Hinweis: Reserviert für funktionale Kennung Signal-Tag." 254 "Hinweis: Reserviert für funktionale Kennung Signal-Tag." 255 "Sendefunktion nicht in Betrieb.";
VAL_ 735 RLS_PWR_COOL_BT_FAST_AIC 253 "Hinweis: Reserviert für funktionale Kennung Signal-Tag." 254 "Hinweis: Reserviert für funktionale Kennung Signal-Tag." 255 "Sendefunktion nicht in Betrieb.";
VAL_ 735 RLS_PWR_DFR_AIC 4093 "Hinweis: Reserviert für funktionale Kennung Signal-Tag." 4094 "Hinweis: Reserviert für funktionale Kennung Signal-Tag." 4095 "Sendefunktion nicht in Betrieb.";
VAL_ 735 RLS_PWR_FOG_AIC 4093 "Hinweis: Reserviert für funktionale Kennung Signal-Tag." 4094 "Hinweis: Reserviert für funktionale Kennung Signal-Tag." 4095 "Sendefunktion nicht in Betrieb.";
VAL_ 741 RLS_PWR_CLDWN_AIC 253 "Hinweis: Reserviert für funktionale Kennung Signal-Tag." 254 "Hinweis: Reserviert für funktionale Kennung Signal-Tag." 255 "Sendefunktion nicht in Betrieb.";
VAL_ 741 RLS_PWR_HTUP_AIC 253 "Hinweis: Reserviert für funktionale Kennung Signal-Tag." 254 "Hinweis: Reserviert für funktionale Kennung Signal-Tag." 255 "Sendefunktion nicht in Betrieb.";
VAL_ 741 RLS_PWR_CNSR_COOL_AIC 253 "Hinweis: Reserviert für funktionale Kennung Signal-Tag." 254 "Hinweis: Reserviert für funktionale Kennung Signal-Tag." 255 "Sendefunktion nicht in Betrieb.";
VAL_ 741 RLS_PWR_CNSR_HT_AIC 253 "Hinweis: Reserviert für funktionale Kennung Signal-Tag." 254 "Hinweis: Reserviert für funktionale Kennung Signal-Tag." 255 "Sendefunktion nicht in Betrieb.";
VAL_ 741 RLS_PWR_PRECOND_INO_AIC 253 "Hinweis: Reserviert für funktionale Kennung Signal-Tag." 254 "Hinweis: Reserviert für funktionale Kennung Signal-Tag." 255 "Sendefunktion nicht in Betrieb.";
VAL_ 968 DIST_VEH_GPS_SIG_V_COR 4094 "Bestätigungs-Code für gültige Übertragung" 4095 "Signal ungültig";
VAL_ 761 ST_PHTR_ENGSTA_DRV 1 "Wird verschickt, wenn das Gerät AUS ist bzw. kein Stand-/Zuheizer verbaut ist." 2 "Wird verschickt, wenn das Standheizgerät den Status EIN als Standheizer zurückmeldet." 7 "Wird verschickt, sobald eine Kommunikationsstörung zwischen dem SH_ZH und der IHKA erkannt wird.";
VAL_ 761 AVL_RQMT_HTFL 0 "Keine_Anforderung" 1 "Zusatzheizleistung_erforderlich" 2 "Anforderung_niedrige_Kuehlmitteltemperatur_NTKW" 3 "Signal_ungueltig";
VAL_ 761 AVL_SETQ_LOW_TEMP_WAP_AIC 13 "SIGNALTAG_FCTIF_NOT_AVAILABLE" 14 "SIGNALTAG_FCT_ERROR" 15 "Sendefunktion nicht in Betrieb";
VAL_ 512 FRC_AIC_PWR_RETA 253 "SIGNALTAG_FCTIF_NOT_AVAILABLE" 254 "SIGNALTAG_FCT_ERROR" 255 "Sendefunktion nicht in Betrieb";
VAL_ 512 FRC_AIC_ENERG_CLDWN_HTUP 253 "SIGNALTAG_FCTIF_NOT_AVAILABLE" 254 "SIGNALTAG_FCT_ERROR" 255 "Sendefunktion nicht in Betrieb";
VAL_ 512 MUX_RQ_AIC_1 3 "This literal is used as current_settings in SP2021ff (excluding SP2021R)" 4 "Sport" 5 "Sport_Plus" 7 "ECO_Pro" 8 "Info: ECO_Pro_Plus equals Max Efficient in SP2021 (excluding SP2021R)" 15 "Signal ungültig";
VAL_ 512 ActualValueThermicCoolingUrgency 61 "SIGNALTAG_FCTIF_NOT_AVAILABLE" 62 "SIGNALTAG_FCT_ERROR" 63 "Sendefunktion nicht in Betrieb";
VAL_ 160 TAR_MOD_SHFT_DVCH 0 "Initialisierung" 1 "Keine Anforderung" 2 "M-Gasse" 3 "Tip in D (Kurzzeitmanuell)" 12 "Sprint Modus aktiv" 13 "Hinweis: Reserviert für funktionale Kennung Signal-Tag" 14 "Hinweis: Reserviert für funktionale Kennung Signal-Tag" 15 "Sendefunktion nicht in Betrieb";
VAL_ 258 RQ_SOU 0 "Kein Ton" 1 "z.B. CTA-Klangzeichen" 2 "IBrake-Klangzeichen" 15 "Signal ungültig";
VAL_ 261 RQ_DISP_SYM 0 "Kein Warnsymbol anzeigen" 1 "System: Nivi; pFGS / IBrake / CCM" 2 "System: Nivi" 3 "System: Nivi" 4 "System: Nivi" 5 "System: Nivi; Kombination" 6 "System: Nivi; Kombination" 7 "System: Nivi; Kombination" 8 "System: Nivi; Kombination" 9 "System: Nivi" 10 "System: Nivi" 11 "System: IBrake / CCM" 12 "Defaultanzeige oder System: IBrake / CCM / QVA" 13 "System: QVA" 14 "System: QVA" 15 "System: GWW" 16 "System: GWW" 17 "System: GWW" 18 "System: WWA" 253 "Hinweis: Reserviert für funktionale Kennung Signal-Tag" 254 "Hinweis: Reserviert für funktionale Kennung Signal-Tag" 255 "Sendefunktion nicht in Betrieb";
VAL_ 261 RQ_SYMAB 0 "Keine Warnung" 1 "Vorwarnung" 2 "Akutwarnung" 13 "Hinweis: Reserviert für funktionale Kennung Signal-Tag" 14 "Hinweis: Reserviert für funktionale Kennung Signal-Tag" 15 "Sendefunktion nicht in Betrieb";
VAL_ 1096 RequestKeyFunction 0 "Request for an interior key search" 1 "Request to activate an key" 2 "Request to deactivate an key" 253 "SIGNALTAG_FCTIF_NOT_AVAILABLE" 254 "SIGNALTAG_FCT_ERROR" 255 "Send function not in operation";
VAL_ 1096 RequestKeyId 0 "Key of slot entry 0 is affected" 1 "Key of slot entry 1 is affected" 2 "Key of slot entry 2 is affected" 3 "Key of slot entry 3 is affected" 4 "Key of slot entry 4 is affected" 5 "Key of slot entry 5 is affected" 6 "Key of slot entry 6 is affected" 7 "Key of slot entry 7 is affected" 8 "Key of slot entry 8 is affected" 9 "Key of slot entry 9 is affected" 16 "Key of slot entry 10 is affected" 17 "Key of slot entry 11 is affected" 18 "Key of slot entry 12 is affected" 19 "Key of slot entry 13 is affected" 20 "Key of slot entry 14 is affected" 21 "Key of slot entry 15 is affected" 22 "Key of slot entry 16 is affected" 23 "Key of slot entry 17 is affected" 24 "Key of slot entry 18 is affected" 25 "Key of slot entry 19 is affected" 16777213 "SIGNALTAG_FCTIF_NOT_AVAILABLE" 16777214 "SIGNALTAG_FCT_ERROR" 16777215 "Send function not in operation";
VAL_ 464 TORQ_MIN_LAY_2_MOT_1 252 "Keine Beschränkung" 253 "SIGNALTAG_FCTIF_NOT_AVAILABLE" 254 "Hinweis: Reserviert für funktionale Kennung Signal-Tag." 255 "Sendefunktion nicht in Betrieb";
VAL_ 464 TORQ_MAX_LAY_2_MOT_1 252 "Keine Beschränkung" 253 "SIGNALTAG_FCTIF_NOT_AVAILABLE" 254 "Hinweis: Reserviert für funktionale Kennung Signal-Tag." 255 "Sendefunktion nicht in Betrieb";
VAL_ 786 TR_AUTOM_SER_CALL_TS 0 "Keine Aktion" 1 "Trigger aktiv" 3 "Signal ungültig";
VAL_ 786 ST_CBS_TS 0 "Keine Aktion" 1 "ServiceCall getriggert" 2 "ServiceCall idle" 3 "Signal ungültig";
VAL_ 933 DSTN_SLRDI_GLB 128 "K-CAN Bus Slave" 129 "Body-CAN Bus Slave" 130 "FA-CAN Bus Slave" 131 "FlexRay Bus Slave" 132 "I-CAN Bus Slave" 133 "LO-CAN Bus Slave" 134 "FAS-CAN Bus Slave" 136 "MOST Bus Slave" 225 "Broadcast alle Slaves" 255 "Signal ungültig";
VAL_ 933 CTR_SLRDI_GLB 1 "AWAKE_IND" 2 "SLEEP_ACK" 3 "Signal ungültig";
VAL_ 933 CTR_FSL 1 "SLEEP_COOPERATIVE" 2 "(Vorhalt)" 3 "Signal ungültig";
VAL_ 933 CTR_SLP_BUS 1 "COLLECTIVE_INDICATION" 2 "PARTIAL_INDICATION" 3 "Signal ungültig";
VAL_ 933 CTR_SNW 1 "Wachhalten K-CAN" 2 "Wachhalten Body-CAN" 4 "Wachhalten FA-CAN" 8 "Wachhalten A-FlexRay" 16 "Wachhalten A-CAN" 32 "Wachhalten MOST" 4095 "Signal ungültig";
VAL_ 740 ST_DI_DF_TRAI 0 "Beide Blinker in Ordnung" 1 "Blinker rechts defekt" 2 "Blinker links defekt" 3 "Beide_Blinker_defekt" 7 "Signal ungültig";
VAL_ 740 ST_SYNCN_HAZWCL_TRAI 0 "Bussynchronisation" 1 "Hardwaresynchronisation" 3 "Signal ungültig";
VAL_ 740 ST_RFLI_DF_TRAI 0 "Nebelschlussleuchte betriebsbereit" 1 "Nebelschlussleuchte defekt, nicht vorhanden oder nicht erkannt." 3 "Signal ungültig";
VAL_ 740 ST_PO_AHV 0 "(Arbeitsposition)" 1 "(Ruheposition)" 2 "Zwischenposition" 3 "(keine Nachtaktung)" 4 "Bewegung in Richtung Ruheposition" 5 "Bewegung in Richtung Arbeitsposition" 7 "Signal ungültig";
VAL_ 740 StatusBikeCarrier 0 "Fahrradhecktraeger_oder Anhaenger_ohne PDC_Funktion_angeschlossen" 1 "Fahrradhecktraeger_mit_PDC_Funktion_angeschlossen" 3 "(kein Anhaenger oder Fahrradhecktraeger erkannt / Funktion nicht codiert)";
VAL_ 740 DISP_ST_TRAI 0 "Auswahl in MMI nicht gesetzt und nicht ausgegraut; Durch den Kunden änderbar." 1 "Auswahl in MMI gesetzt und nicht ausgegraut; Durch den Kunden änderbar." 2 "Auswahl in MMI gesetzt und ausgegraut; Nicht durch den Kunden änderbar." 3 "Sendefunktion nicht in Betrieb.";
VAL_ 860 ST_BC_2_BN2020 0 "BC2 ist gestoppt" 1 "BC2 läuft" 3 "Signal ungültig";
VAL_ 860 ST_RST_BC2_BN2020 0 "Kein automatischer Reset BC aktiv" 1 "Automatischer Reset BC aktiv" 3 "Signal ungültig";
VAL_ 860 ST_LIM_BN2020 0 "Limitwarnung deaktiviert" 1 "Limitwarnung aktiviert" 2 "Keine Aktion" 3 "Signal ungültig";
VAL_ 860 ST_UN_V_SPDM_BN2020 0 "km/h" 1 "mph" 3 "Signal ungültig";
VAL_ 847 ST_CT_HABR 0 "nicht codiert" 1 "Handbremse gelöst" 2 "Handbremse angezogen" 3 "Signal ungültig";
VAL_ 722 DT_PSEN_RFCI 253 "Elektrischer Fehler, wird nicht in SP2009 versendet" 254 "Elektrischer Fehler, wird nicht in SP2009 versendet" 255 "Signal ungültig";
VAL_ 481 ST_DSW_DRD_VRFD 0 "Tür ist geschlossen" 1 "Tür ist offen" 2 "Sensorsignal im ungültigen Bereich (zwischen offen und geschlossen)" 3 "Fehler Kurzschluss oder Drahtbruch";
VAL_ 481 ST_DSW_PSD_VRFD 0 "Tür ist geschlossen" 1 "Tür ist offen" 2 "Sensorsignal im ungültigen Bereich (zwischen offen und geschlossen)" 3 "Fehler Kurzschluss oder Drahtbruch";
VAL_ 481 ST_DSW_PSDR_VRFD 0 "Tür ist geschlossen" 1 "Tür ist offen" 2 "Sensorsignal im ungültigen Bereich (zwischen offen und geschlossen)" 3 "Fehler Kurzschluss oder Drahtbruch";
VAL_ 481 ST_DSW_DVDR_VRFD 0 "Tür ist geschlossen" 1 "Tür ist offen" 2 "Sensorsignal im ungültigen Bereich (zwischen offen und geschlossen)" 3 "Fehler Kurzschluss oder Drahtbruch";
VAL_ 779 ALIV_ST_ENG_STA_AUTO 15 "Signal ungültig";
VAL_ 779 RQ_MSA_ENG_STA_1 0 "Zustand nicht definiert, Fehlerfall in Applikation (kein Motorstart)" 1 "Steuert KL50_MSA nicht an" 2 "Steuert KL50_MSA an" 3 "Fehlerfall, TimeOut (kein Motorstart)";
VAL_ 779 RQ_MSA_ENG_STA_2 0 "Zustand nicht definiert, Fehlerfall in Applikation (kein Motorstart)" 1 "Steuert KL50_MSA nicht an" 2 "Steuert KL50_MSA an" 3 "Fehlerfall, TimeOut (kein Motorstart)";
VAL_ 779 ST_AVL_PENG_CENG_ENGMG 0 "kein Kraftschluss" 1 "Kraftschluss" 3 "Signal ungültig";
VAL_ 779 ST_FN_MSA 0 "MSA-Funktion deaktiviert" 1 "MSA-Funktion aktiv" 3 "Fehlerfall, per Default wird MSA-Funktion deaktiviert";
VAL_ 779 SPEC_TYP_ENGSTA_PRM 0 "Dauerhaft kein Startsystem ausgewählt" 1 "Dauerhaft Starter-Genarator ausgewählt" 2 "Dauerhaft E-Maschine als Startsystem ausgewählt" 3 "Dauerhaft Kombinationstart ausgewählt" 4 "Dauerhaft Ritzelstarter ausgewählt" 5 "Dauerhaft Zustarteinrichtung" 13 "Hinweis: Reserviert für funktionale Kennung Signal-Tag." 14 "Hinweis: Reserviert für funktionale Kennung Signal-Tag." 15 "Sendefunktion nicht in Betrieb";
VAL_ 779 ST_TAR_CENG 1 "Sollzustand Verbrenner aus" 2 "Sollzustand Verbrenner ein" 3 "Signal ungültig";
VAL_ 779 ST_RPM_CLCTR_MOT 0 "keine Drehzahlregelung" 1 "Drehzahlregelung aktiv" 3 "Signal ungültig";
VAL_ 779 ST_TAR_PENG_CENG 0 "kein Kraftschluss" 1 "Kraftschluss" 3 "Signal ungültig";
VAL_ 779 ST_AVAI_SAIL_DME 0 "SV 6 Aus" 1 "Entspricht AVL_MOD_SW_DRDY_INTR_BIT4 = 0" 2 "SV Segeln Einstieg An" 4 "SV 2 An" 8 "SV 3 An" 16 "SV 4 An" 32 "SV 5 An" 64 "SV 6 An" 253 "SIGNALTAG_FCTIF_NOT_AVAILABLE" 254 "SIGNALTAG_FCT_ERROR" 255 "Sendefunktion nicht in Betrieb";
VAL_ 779 VARI_TYP_ENGSTA 0 "normaler Verbrennungsmotorstart/normales Abstellen" 1 "DSC-Anforderung" 2 "Variante des SGR-Starts; geführtes Abstellen" 3 "Signal ungültig";
VAL_ 779 ST_CON_MSA 0 "Initialisierung" 1 "kein MSA-Motorstopp angekündigt oder aktiv" 2 "MSA-Motorstopp angekündigt oder aktiv in Durchführung" 3 "Motorstopp beabsichtigt" 4 "darf nur gesetzt werden, wenn Getriebe Freigabe Motorstopp mit GGA gesetzt wurde (ST_RLS_MSA)" 5 "darf nur gesetzt werden, wenn Getriebe Freigabe Motorstopp - NüN aktiv gesetzt wurde (ST_RLS_MSA)" 7 "Motorstopp im Gang" 8 "Motor aus" 9 "(auch Retry)" 10 "Motorstart durch Verbrennungsenergie" 12 "Funktion passiv durch Bedienelement" 13 "Hinweis: Reserviert für funktionale Kennung Signal-Tag" 14 "Hinweis: Reserviert für funktionale Kennung Signal-Tag" 15 "Sendefunktion nicht in Betrieb";
VAL_ 788 ST_LOWB 0 "Fahrlicht ausschalten" 1 "Fahrlicht einschalten" 3 "Signal ungültig";
VAL_ 788 ST_SEN_LOWB 0 "In Ordnung" 1 "Defekt" 3 "Signal ungültig";
VAL_ 788 AMBR_LOWB 0 "Nicht verwendet" 15 "Signal ungültig";
VAL_ 788 ST_LOWB_REAS 0 "Keine HUD Ausgabe" 1 "Dämmerung" 2 "Dunkelheit" 4 "Niederschlag" 8 "Tunnel" 16 "Tiefgarage" 32 "Hochgeschwindigkeit" 64 "Meßbereich 1" 128 "Meßbereich 2" 255 "Signal ungültig";
VAL_ 788 ST_VL_LOWB 255 "Signal ungültig";
VAL_ 570 NO_KEY_PRSL_IMME 0 "Profil_1" 1 "Profil_2" 2 "Profil_3" 3 "Profil_4. Gilt ab SP2021 (exklusive SP2021R)" 4 "Profil_5. Gilt ab SP2021 (exklusive SP2021R)" 5 "Profil_6. Gilt ab SP2021 (exklusive SP2021R)" 6 "Profil_7. Gilt ab SP2021 (exklusive SP2021R)" 10 "Gastprofil" 14 "Defaultprofil" 15 "Sendefunktion nicht in Betrieb oder unpersonalisiertes_Profil";
VAL_ 570 NO_KEY_PRSL 0 "Profil_1" 1 "Profil_2" 2 "Profil_3" 3 "Profil_4. Gilt ab SP2021 (exklusive SP2021R)" 4 "Profil_5. Gilt ab SP2021 (exklusive SP2021R)" 5 "Profil_6. Gilt ab SP2021 (exklusive SP2021R)" 6 "Profil_7. Gilt ab SP2021 (exklusive SP2021R)" 10 "Gastprofil" 14 "Defaultprofil" 15 "Sendefunktion nicht in Betrieb oder unpersonalisiertes_Profil";
VAL_ 570 ST_KEY_RMC 0 "Fernbedienungsschlüssel" 1 "Kein Fernbedienungsschlüssel" 2 "Reserviert" 3 "Signal ungültig";
VAL_ 570 ST_KEY_BT 0 "Batterie in Ordnung" 1 "Unterspannung liegt vor" 3 "Signal ungültig";
VAL_ 570 OP_KEY_LDPO_FLDT 0 "Keine Anforderung" 1 "Anforderung Lade-Position" 3 "Signal ungültig";
VAL_ 570 OP_KEY_BUT_ULOK 0 "Taste nicht betätigt" 1 "Taste betätigt" 3 "Signal ungültig";
VAL_ 570 OP_KEY_BUT_LOK 0 "Taste nicht betätigt" 1 "Taste betätigt" 3 "Signal ungültig";
VAL_ 570 OP_KEY_BUT_BTL 0 "Signal wird in Abhängigkeit von der konfigurierten Funktion auf der Taste gesendet." 1 "Signal wird in Abhängigkeit von der konfigurierten Funktion auf der Taste gesendet." 3 "Signal ungültig";
VAL_ 570 NO_KEY_TR_PRSL 0 "Personalisierungsnummer_0" 1 "Personalisierungsnummer_1" 2 "Personalisierungsnummer_2" 3 "Gilt ab SP2021 (exklusive SP2021R)" 4 "Gilt ab SP2021 (exklusive SP2021R)" 5 "Gilt ab SP2021 (exklusive SP2021R)" 6 "Gilt ab SP2021 (exklusive SP2021R)" 10 "Gastprofil" 14 "Defaultprofil" 15 "Sendefunktion nicht in Betrieb oder unpersonalisiertes_Profil";
VAL_ 570 CTR_TR_PRSL 0 "Keine Aktion" 1 "Personalisierungsdaten abrufen" 2 "Personalisierungsdaten speichern" 3 "Signal ungültig";
VAL_ 570 ST_LOK_RQ_FFB_LFSR 0 "keine Erkennung angestoßen" 1 "FFB nicht im Nahbereich detektiert (bei gedrücktem Lock Button)" 2 "FFB im Nahbereich detektiert (bei gedrücktem Lock Button)" 3 "Signal ungültig";
VAL_ 570 CTR_LP_FMH 0 "Keine Follow-Me-Home-Funktion aktivieren" 1 "Follow-Me-Home-Funktion aktivieren (ggf. zur Vermeidung von Übertragungs-Fehlern erst mit dreimaligem Empfang) aktvieren" 3 "Signal ungültig";
VAL_ 570 CTR_UGDO 0 "Keine UGDO-RCS-Funktion aktivieren" 1 "UGDO-RCSFunktion aktivieren (ggf. zur Vermeidung von Übertragungs-Fehlern erst mit dreimaligem Empfang) aktvieren" 3 "Signal ungültig";
VAL_ 570 ST_KEY_BT_DISP_MMI 0 "Keine Anzeige im MMI aktiviern (Funktion ist deaktivert)" 1 "Rest-Lebensdauer der Schlüssel-Batterie: 1Monat" 2 "Rest-Lebensdauer der Schlüssel-Batterie: 2Monate" 3 "Rest-Lebensdauer der Schlüssel-Batterie: 3Monate" 4 "Rest-Lebensdauer der Schlüssel-Batterie: 4Monate" 5 "Rest-Lebensdauer der Schlüssel-Batterie: 5Monate" 6 "Rest-Lebensdauer der Schlüssel-Batterie: 6Monate" 7 "Rest-Lebensdauer der Schlüssel-Batterie: 7Monate" 8 "Rest-Lebensdauer der Schlüssel-Batterie: 8Monate" 9 "Rest-Lebensdauer der Schlüssel-Batterie: 9Monate" 10 "Rest-Lebensdauer der Schlüssel-Batterie: 10Monate" 11 "Rest-Lebensdauer der Schlüssel-Batterie: 12Monate" 12 "Rest-Lebensdauer der Schlüssel-Batterie: 24Monate" 13 "Rest-Lebensdauer der Schlüssel-Batterie: 36Monate" 14 "Rest-Lebensdauer der Schlüssel-Batterie: 48Monate" 15 "Signal ungültig";
VAL_ 570 ST_PCOL 0 "Taste am ID-Geber zur Auslösung Standkühlung nicht betätigt. Empfängersteuergerät entscheidet, wie mit einer ausgelösten Standkühlung zu verfahren ist." 1 "Taste am ID-Geber zur Auslösung Standkühlung betätigt (mindestens 501ms) und wieder losgelassen." 2 "Verriegelntaste 3-Mal gedrückt (Auslösung für Remote Start)" 3 "Signal ungültig";
VAL_ 570 CTR_PAN_MOD 0 "Beendet den ausgelösten Panik-Alarm bzw. keine Auslösung Panik-Alarm." 1 "Auslösung des Panik-Alarms durch einmalige Betätigung der Panik-Alarmtaste vom ID-Geber nach einer Mindestbetätigungsdauer oder 3fach-Druck der Panik-Alarmtaste innerhalb Maximalzeitfenster. Status bleibt solange erhalten, bis eine beliebige ID-Gebertaste betätigt wurde. (Fahrzeugentriegelung beendet ausgelösten Panik-Alarm)" 3 "Signal ungültig";
VAL_ 570 AVL_MOD_SSHK 0 "nicht_aktiv" 1 "Modus_1_aktiv" 13 "Hinweis: Reserviert für funktionale Kennung Signal-Tag." 14 "Hinweis: Reserviert für funktionale Kennung Signal-Tag." 15 "Sendefunktion nicht in Betrieb";
VAL_ 944 ST_GR_BAC 1 "kein Rückwärtsgang" 2 "Rückwärtsgang" 3 "Signal ungültig";
VAL_ 274 StatusThermicCapacityUtilization 0 "Keine_Anforderung" 1 "Untertemperaturabschaltung" 2 "Leistungseinschraenkung_zu_kalt_Bereich" 3 "Waermer_Bereich" 4 "Unterer_Wohlfuehltemperaturbereich" 5 "Unterer_Idealtemperaturbereich" 6 "Oberer_Idealtemperaturbereich" 7 "Oberer_Wohlfuehltemperaturbereich" 8 "Kaelter_Bereich" 9 "Leistungseinschraenkung_zu_heiss_Bereich" 10 "Uebertemperaturabschaltung" 11 "Ungueltig" 13 "SIGNALTAG_FCTIF_NOT_AVAILABLE" 14 "SIGNALTAG_FCT_ERROR" 15 "Send function not in operation";
VAL_ 814 CTR_BLW 253 "SIGNALTAG_FCTIF_NOT_AVAILABLE" 254 "SIGNALTAG_FCT_ERROR" 255 "Sendefunktion nicht in Betrieb";
VAL_ 752 ST_PAIC 0 "Keine Aktion / Nicht verfügbar" 1 "Standklimatisierung aus" 2 "Standklimatisierung ein" 3 "Signal ungültig";
VAL_ 752 ST_IVNT 0 "Keine Aktion / Nicht verfügbar" 1 "Standlüften aus" 2 "Im SP2013 (ohne 444, UKL, F15-F16) wird diese Codierung auch als \"Standby\" ausgewertet." 3 "Signal ungültig";
VAL_ 752 ST_BLW 0 "Geblaese_AUS" 1 "Geblaese_EIN" 3 "Signal_ungueltig";
VAL_ 752 ST_PHTR 0 "Keine Aktion / Nicht verfügbar" 1 "Standheizung aus" 2 "Standheizung ein" 3 "Signal ungültig";
VAL_ 752 ST_EXHT 0 "Keine Aktion / Nicht verfügbar" 1 "ZH ausschalten / aus" 2 "ZH einschalten / ein" 3 "Signal ungültig";
VAL_ 752 ST_PFN_AMOD 0 "Keine Aktion / Nicht verfügbar" 1 "Auto-Modus aus" 2 "Auto-Modus ein" 3 "Signal ungültig";
VAL_ 752 ST_PFN_RMC 0 "Kein_Fehler" 1 "Tankreserve" 2 "Batterie" 3 "Sperre_Nachlaufzeit" 4 "Heizgeraetestoerung" 5 "Komponentenfehler" 6 "Motorhaube offen (ab SP2018)" 8 "Kein_Fehler_AutoMode_aktiv" 15 "Signal_ungueltig";
VAL_ 752 RQ_ENGR_PFN 0 "Keine_Anforderung_Remote_Start" 1 "Anforderung_Remote_Start" 2 "Remote_Start_initiiert" 3 "Sendefunktion nicht in Betrieb";
VAL_ 752 ST_ENGR_PFN 0 "Keine_Aktion" 1 "Remote_Start_nicht_aktiv" 2 "Remote_Start_aktiv" 3 "Sendefunktion nicht in Betrieb";
VAL_ 752 RQR_PFN 0 "Kein_Anforderer" 1 "Remote Start über Signal ST_PCOL angefordert (auch über DSK möglich)" 2 "DisplayKey" 3 "ATM_App" 4 "Timer" 5 "Sofortstart über MMI aktiviert über OP_PFN_AMOD" 13 "SIGNALTAG_FCTIF_NOT_AVAILABLE" 14 "SIGNALTAG_FCT_ERROR" 15 "Sendefunktion nicht in Betrieb";
VAL_ 752 ST_SU_REM_STA 0 "Keine_Aktion_Nicht_verfuegbar" 1 "Standlüften aktiv" 2 "\"Motorlauf als Standfunktion\" aktiv" 3 "Sendefunktion nicht in Betrieb";
VAL_ 752 AVL_DUR_PFN 253 "SIGNALTAG_FCTIF_NOT_AVAILABLE" 254 "SIGNALTAG_FCT_ERROR" 255 "Sendefunktion nicht in Betrieb";
VAL_ 542 ST_CONTR_NIVI 255 "Signal ungültig";
VAL_ 542 ST_RLS_NIVI 1 "Night-Vision darf nicht eingeschaltet werden" 2 "Night-Vision darf eingeschaltet werden" 3 "Signal ungültig";
VAL_ 542 ST_CAM_NIVI 1 "Night-Vision-Kamera AUS" 2 "Night-Vision-Kamera EIN" 3 "Signal ungültig";
VAL_ 542 ST_OPTN_ACTVN_GZA 0 "Funktion ausgefallen" 1 "Funktion teilweise ausgefallen - nicht aktiv" 2 "Funktion i.O. - nicht aktiv" 3 "Eingeschränkt aktiv" 4 "Funktion i.O. - aktiv" 5 "Signal Tag - Schnittstelle ist nicht verfügbar" 6 "Signal Tag - Funktion meldet Fehler" 7 "Signal Tag - Signal ist unbefüllt";
VAL_ 542 ST_OBJ_DETE_NIVI 0 "Objekterkennung nicht aktivierbar" 1 "Objekterkennung AUS" 2 "Objekterkennung EIN" 3 "Signal ungültig";
VAL_ 542 RQ_DISP_NIVI 1 "Night-Vision-Bild AUS" 2 "Night-Vision-Bild EIN" 3 "Signal ungültig";
VAL_ 543 ST_AVAI_CHAIN_BRG 1 "Bremskoordinator ist bereit Anforderungen von den entsprechenden Sicherheitssystemen entgegen zu nehmen. Es wird aber aktuell keine Bremsung umgesetzt." 2 "Bremskoordinator ist nicht bereit Anforderungen von den entsprechenden Sicherheitssystemen entgegen zu nehmen. Sperrzeit auf Grund funktionaler Randbedingungen zwischen zwei Bremsanforderungen, u. a. durch Fahrerinteraktion (Sperrungen durch einzelne Überlagerungen werden hier nicht berücksichtigt)." 6 "Dieser Zustand stellt sich dann ein, wenn die Funktion nicht zur Verfügung gestellt werden kann und ein interner HW/SW Fehler identifiziert wurde." 8 "Funktion befindet sich in der Initialisierung" 9 "Eine Bremsung wurde angefordert und wird aktuell umgesetzt." 10 "Bremskoordinator ist bereit Anforderungen von den entsprechenden Sicherheitssystemen entgegen zu nehmen. Eine Bremsung wurde angefordert und wird aktuell umgesetzt. Abbruch durch Fahrer (nicht durch zeitliche Restriktionen) steht bevor. Dieses Bit wird einen Zyklus lang gesetzt und wird gefolgt durch Zustand 0001." 14 "Dieser Zustand stellt sich dann ein, wenn die Funktion nicht zur Verfügung gestellt werden kann, jedoch kein interner HW/SW Fehler vorliegt." 15 "Signal ist unbefüllt. Defaultbefüllung durch die KOM-Schicht beim Aufstarten der ECU bzw. statischer Zustand bei Auskodierung der Funktion.";
VAL_ 543 ST_AVAI_CHAIN_WARN 1 "Warnkoordinator ist bereit Anforderungen von den entsprechenden Sicherheitssystemen entgegen zu nehmen.  Es wird aber aktuell keine Warnung angezeigt." 6 "Dieser Zustand stellt sich dann ein, wenn die Funktion nicht zur Verfügung gestellt werden kann und ein interner HW/SW Fehler identifiziert wurde." 8 "Funktion befindet sich in der Initialisierung" 9 "Warnkoordinator ist bereit Anforderungen von den entsprechenden Sicherheitssystemen entgegen zu nehmen.  Eine Warnung wurde angefordert und wird aktuell angezeigt." 14 "Dieser Zustand stellt sich dann ein, wenn die Funktion nicht zur Verfügung gestellt werden kann, jedoch kein interner HW/SW Fehler vorliegt. Dies umfasst auch die Fahrerinteraktion (z.B. Deaktivieren eines Systems durch den Fahrer)." 15 "Signal ist unbefüllt. Defaultbefüllung durch die KOM - Schicht beim Aufstarten der ECU bzw. statischer Zustand bei  Auskodierung der Funktion.";
VAL_ 783 AVAI_SER_TeleX 0 "Automatischer Service-Call ist nicht verfügbar" 1 "Automatischer Service-Call ist verfügbar" 15 "Signal ungültig";
VAL_ 783 ST_SER_CALL_TeleX 0 "Idle" 1 "Data Call Triggered" 2 "Data Transfer in Preparation" 3 "Data Transfer in progress" 4 "Data Call suspended / on hold" 5 "Data Transfer successful" 6 "Data Transfer paused (awaiting user information)" 7 "Data Transfer not successful" 8 "Data Call finished successfully" 9 "Data Call cancelled by user abort" 10 "Data Call not successful (other reasons)" 15 "Signal ungültig";
VAL_ 764 CTR_CLSY 0 "Elektrisch_oeffnen" 1 "Entriegeln" 2 "Verriegeln" 3 "Sichern" 5 "Kindersicherung_deaktivieren" 7 "Kindersicherung_aktivieren" 8 "Keine_Aenderung" 13 "SIGNALTAG_FCTIF_NOT_AVAILABLE" 14 "SIGNALTAG_FCT_ERROR" 15 "Send function not in operation";
VAL_ 764 ST_DSW_DRD 0 "FAT ist geschlossen" 1 "FAT ist offen" 2 "Bei Unter-/Überspannung oder Sensorsignal im ungültigen Bereich (zwischen offen und geschlossen)" 3 "Bei Fehler Kurzschluss, Drahtbruch";
VAL_ 764 ST_DSW_PSD 0 "Beifahrertür ist geschlossen" 1 "Beifahrertür ist offen" 2 "Bei Unter-/Überspannung oder Sensorsignal im ungültigen Bereich (zwischen offen und geschlossen)" 3 "Bei Fehler Kurzschluss, Drahtbruch";
VAL_ 764 ST_DSW_DVDR 0 "FATH ist geschlossen" 1 "FATH ist offen" 2 "Bei Unter-/Überspannung oder Sensorsignal im ungültigen Bereich (zwischen offen und geschlossen)" 3 "Bei Fehler Kurzschluss, Drahtbruch";
VAL_ 764 ST_DSW_PSDR 0 "BFTH ist geschlossen" 1 "BFTH ist offen" 2 "Bei Unter-/Überspannung oder Sensorsignal im ungültigen Bereich (zwischen offen und geschlossen)" 3 "Bei Fehler Kurzschluss, Drahtbruch";
VAL_ 764 ST_CT_BTL 0 "BN2020: Bei Splitdoors sind beide Türen geschlossen" 1 "BN2020: Bei Splitdoors ist mindestens die rechte Tür offen" 3 "Signal ungültig";
VAL_ 764 ST_CT_BON 0 "Motorhaube oder Frontklappe geschlossen" 1 "Bei nicht diagnostizierbarem Frontklappenkontakt. Bei diagnostizierbarem Frontklappenkontakt, Fehler Kurzschluss, Drahtbruch, Unter-/Überspannung oder Sensorsignal im ungültigen Bereich (zwischen offen und geschlossen). Diese Codierung wird in einem definierten Pegelbereich versendet und unterscheidet sich so von den Codierwerten 10 und 11." 2 "Nur bei diagnostizierbarem Frontklappenkontakt. Bei Fehler Kurzschluss, Drahtbruch, Unter-/Überspannung oder Sensorsignal im ungültigen Bereich (zwischen offen und geschlossen). Diese Codierung wird in einem definierten Pegelbereich versendet und unterscheidet sich so von den Codierwerten 01 und 11." 3 "Sendefunktion nicht in Betrieb";
VAL_ 764 ST_HOTM 0 "Hotelstellung nicht aktiv" 1 "Hotelstellung aktiv" 3 "Signal ungültig";
VAL_ 764 ST_CT_FLAP_2 0 "Klappe_2_geschlossen" 1 "Klappe_2_offen" 2 "Kurzschluss oder offene Leitung" 3 "Sendefunktion nicht in Betrieb";
VAL_ 764 ST_CT_SCA 0 "SCA_Vorraste_geschlossen" 1 "SCA_Vorraste_offen" 2 "Kurzschluss oder offene Leitung an Türkontakt (Hallsensor)" 3 "Sendefunktion nicht in Betrieb";
VAL_ 764 ST_CLSY_BTL 0 "Heckklappe_nicht_logisch_entriegelt" 1 "Heckklappe_logisch_entriegelt" 3 "Sendefunktion nicht in Betrieb";
VAL_ 719 ST_AUWP 0 "nicht codiert" 1 "ZWP eingeschaltet" 2 "ZWP ausgeschaltet" 3 "thermische Überlastung" 4 "offen" 5 "Masseschluss" 6 "Plusschluss" 7 "Signal ungültig";
VAL_ 770 ST_ECU_STEA_FTAX_EFFV 0 "Zustand Initialisierung" 1 "Zustand Normalbetrieb" 2 "Zustand Normalbetrieb/Überspannung sensiert" 3 "Zustand Normalbetrieb/Unterspannung sensiert" 4 "Zustand Diagnose" 5 "Zustand Diagnose/Überspannung sensiert" 6 "Zustand Diagnose/Unterspannung sensiert" 7 "Zustand Powerdown" 8 "Zustand PowerSave" 9 "Zustand Nicht verfügbar" 10 "Zustand Reset" 11 "Zustand Reserviert 11" 12 "Zustand Reserviert 12" 13 "Zustand Reserviert 13" 14 "Zustand Reserviert 14" 15 "Signal ungültig";
VAL_ 770 ST_CON_STEA 0 "Kein Multiturnverlust an der Hinterrachse erkannt oder keine HSR verbaut" 1 "Die absolute Position der Zahnstange an der Vorderachse kann einen Fehler aufweisen, da nicht sicher bekannt ist in welcher Umdrehung (auf wenige begrenzt) sich der Sensor befindet. Der Lenkwinkel und andere Folgesignale können einen Fehler aufweisen, diese sind aus den Fehleramplituden zu entnehmen." 2 "Die absolute Position der Zahnstange an der Vorderachse kann nicht bestimmt werden, da nicht bekannt ist in welcher Umdrehung sich der Sensor befindet." 4 "Multiturn Information an der Hinterrachse begrenzt bekannt (Teilaufgesetzt)" 8 "Multiturn Information an der Hinterrachse verloren" 12 "Reserviert für Signal Tags" 13 "Hinweis: Reserviert für funktionale Kennung Signal-Tag." 14 "SIGNALTAG_FCT_ERROR" 15 "Sendefunktion nicht in Betrieb";
VAL_ 756 ST_CONN_HSFZ 0 "100BASE-Tx Ethernet Link an OBD Dose ist DOWN - Aktueller Zustand" 1 "100BASE-Tx Ethernet Link an OBD Dose ist UP - Aktueller Zustand" 255 "Signal ungültig";
VAL_ 756 ST_ACTVN_WR_HSFZ 0 "Aktivierungsleitung an OBD Dose ist LOW - Aktueller Zustand" 1 "Aktivierungsleitung an OBD Dose ist HIGH - Aktueller Zustand" 2 "Aktivierungsleitung an OBD Dose ist LOW, war bei letzter Prüfung noch HIGH - Aktueller Zustand + Änderung" 3 "Aktivierungsleitung an OBD Dose ist HIGH, war bei letzter Prüfung noch LOW - Aktueller Zustand + Änderung" 255 "Signal ungültig";
VAL_ 957 ST_FN_BUT_9_MIKO 0 "In M Fahrzeugen Motorsound-Taste nicht gedrückt." 1 "In M Fahrzeugen Motorsound-Taste gedrückt." 2 "In M Fahrzeugen Motorsound-Taste berührt." 3 "Sendefunktion nicht in Betrieb";
VAL_ 663 ST_ERR_SEAT_MT_DR 0 "Falsche Codierung" 1 "Steckverbindungen und oder Leitungen prüfen" 2 "Matte defekt" 6 "Kein Fehler" 7 "Fehlerfall";
VAL_ 663 ST_BLTB_SW_DR 0 "Beim Systemstart  (Kl 30b an) wird vom Airbag-SG, wenn der Gurtschloß-Schalter verbaut ist, der Status \"Signal ungültig\" ausgegeben. Dies darf über die Zeitspanne von 5 Sekunden ab Systemstart zu keinem Fehler führen!" 1 "Beim Systemstart  (Kl 30b an) wird vom Airbag-SG, wenn der Gurtschloß-Schalter verbaut ist, der Status \"Signal ungültig\" ausgegeben. Dies darf über die Zeitspanne von 5 Sekunden ab Systemstart zu keinem Fehler führen!" 2 "Gurtschloß-Schalter ist im Fahrzeug nicht verbaut." 3 "Startwert / Im Fehlerfall";
VAL_ 663 ST_SEAT_OCCU_3_LH_TIR_RS 0 "Der Sitz kann trotzdem mit einem Gegenstand belegt sein." 3 "Sitz_belegt" 4 "Erkennungssystem ist im Fahrzeug nicht verbaut." 6 "Falls das System verbaut ist, wird bei Systemstart (physikalische Kl. 30 B an) dieser Wert für max. 5 s gesendet. Anschließend wird der entsprechende Status gesendet." 7 "Sendefunktion nicht in Betrieb";
VAL_ 663 ST_BLTB_SW_PS 0 "Beim Systemstart  (Kl 30b an) wird vom Airbag-SG, wenn der Gurtschloß-Schalter verbaut ist, der Status \"Signal ungültig\" ausgegeben. Dies darf über die Zeitspanne von 5 Sekunden ab Systemstart zu keinem Fehler führen!" 1 "Beim Systemstart  (Kl 30b an) wird vom Airbag-SG, wenn der Gurtschloß-Schalter verbaut ist, der Status \"Signal ungültig\" ausgegeben. Dies darf über die Zeitspanne von 5 Sekunden ab Systemstart zu keinem Fehler führen!" 2 "Gurtschloß-Schalter ist im Fahrzeug nicht verbaut." 3 "Startwert / Im Fehlerfall";
VAL_ 663 ST_SEAT_OCCU_3_MID_TIR_RS 0 "Der Sitz kann trotzdem mit einem Gegenstand belegt sein." 3 "Sitz_belegt" 4 "Erkennungssystem ist im Fahrzeug nicht verbaut." 6 "Falls das System verbaut ist, wird bei Systemstart (physikalische Kl. 30 B an) dieser Wert für max. 5 s gesendet. Anschließend wird der entsprechende Status gesendet." 7 "Sendefunktion nicht in Betrieb";
VAL_ 663 ST_BLTB_SW_RLH 0 "Beim Systemstart  (Kl 30b an) wird vom Airbag-SG, wenn der Gurtschloß-Schalter verbaut ist, der Status \"Signal ungültig\" ausgegeben. Dies darf über die Zeitspanne von 5 Sekunden ab Systemstart zu keinem Fehler führen!" 1 "Beim Systemstart  (Kl 30b an) wird vom Airbag-SG, wenn der Gurtschloß-Schalter verbaut ist, der Status \"Signal ungültig\" ausgegeben. Dies darf über die Zeitspanne von 5 Sekunden ab Systemstart zu keinem Fehler führen!" 2 "Gurtschloß-Schalter ist im Fahrzeug nicht verbaut." 3 "Startwert / Im Fehlerfall";
VAL_ 663 ST_SEAT_OCCU_3_RH_TIR_RS 0 "Der Sitz kann trotzdem mit einem Gegenstand belegt sein." 3 "Sitz_belegt" 4 "Erkennungssystem ist im Fahrzeug nicht verbaut." 6 "Falls das System verbaut ist, wird bei Systemstart (physikalische Kl. 30 B an) dieser Wert für max. 5 s gesendet. Anschließend wird der entsprechende Status gesendet." 7 "Sendefunktion nicht in Betrieb";
VAL_ 663 ST_BLTB_SW_RRH 0 "Beim Systemstart  (Kl 30b an) wird vom Airbag-SG, wenn der Gurtschloß-Schalter verbaut ist, der Status \"Signal ungültig\" ausgegeben. Dies darf über die Zeitspanne von 5 Sekunden ab Systemstart zu keinem Fehler führen!" 1 "Beim Systemstart  (Kl 30b an) wird vom Airbag-SG, wenn der Gurtschloß-Schalter verbaut ist, der Status \"Signal ungültig\" ausgegeben. Dies darf über die Zeitspanne von 5 Sekunden ab Systemstart zu keinem Fehler führen!" 2 "Gurtschloß-Schalter ist im Fahrzeug nicht verbaut." 3 "Startwert / Im Fehlerfall";
VAL_ 663 ST_SEAT_OCCU_RM 0 "Der Sitz kann trotzdem mit einem Gegenstand belegt sein. Die Information ist erst ab Auslösbereitschaft (Kl R/15 an) verfügbar. Status wird im PDC ermittelt! Bei Systemstart (Kl 30b an) wird \"Signal_unbefuellt\" übertragen." 3 "Sitz_belegt" 4 "Erkennungssystem ist im Fahrzeug nicht verbaut." 6 "Ab Kl R/15 \"an\" (PDC) wird vom Airbag-SG, wenn das Erkennungssystem im Fahrzeug verbaut ist, der Status\" Wert-Initialisierung\" ausgegeben. Die Wert-Ermittlung, ab Kl R/15 \"an\", kann bis zu 10 Sekunden dauern! Bei Systemstart (Kl 30b an) wird \"Signal_unbefuellt\" übertragen." 7 "Sendefunktion nicht in Betrieb";
VAL_ 663 ST_BLTB_SW_RM 0 "Beim Systemstart  (Kl 30b an) wird vom Airbag-SG, wenn der Gurtschloß-Schalter verbaut ist, der Status \"Signal ungültig\" ausgegeben. Dies darf über die Zeitspanne von 5 Sekunden ab Systemstart zu keinem Fehler führen!" 1 "Beim Systemstart  (Kl 30b an) wird vom Airbag-SG, wenn der Gurtschloß-Schalter verbaut ist, der Status \"Signal ungültig\" ausgegeben. Dies darf über die Zeitspanne von 5 Sekunden ab Systemstart zu keinem Fehler führen!" 2 "Gurtschloß-Schalter ist im Fahrzeug nicht verbaut." 3 "Startwert / Im Fehlerfall";
VAL_ 663 ST_BLTB_SW_3_LH_TIR_RS 0 "Beim Systemstart (KL_30B an) wird vom Airbag-SG, wenn der Gurtschloss-Schalter verbaut ist, der Status \"Signal ungültig\" ausgegeben. Dies darf über die Zeitspanne von 5 Sekunden ab Systemstart zu keinem Fehler führen." 1 "Beim Systemstart (KL_30B an) wird vom Airbag-SG, wenn der Gurtschloss-Schalter verbaut ist, der Status \"Signal ungültig\" ausgegeben. Dies darf über die Zeitspanne von 5 Sekunden ab Systemstart zu keinem Fehler führen." 2 "Gurtschloss-Schalter ist im Fahrzeug nicht verbaut." 3 "Startwert/im Fehlerfall";
VAL_ 663 ST_BLTB_SW_3_RH_TIR_RS 0 "Beim Systemstart (KL_30B an) wird vom Airbag-SG, wenn der Gurtschloss-Schalter verbaut ist, der Status \"Signal ungültig\" ausgegeben. Dies darf über die Zeitspanne von 5 Sekunden ab Systemstart zu keinem Fehler führen." 1 "Beim Systemstart (KL_30B an) wird vom Airbag-SG, wenn der Gurtschloss-Schalter verbaut ist, der Status \"Signal ungültig\" ausgegeben. Dies darf über die Zeitspanne von 5 Sekunden ab Systemstart zu keinem Fehler führen." 2 "Gurtschloss-Schalter ist im Fahrzeug nicht verbaut." 3 "Startwert/im Fehlerfall";
VAL_ 663 ST_BLTB_SW_3_MID_TIR_RS 0 "Beim Systemstart (KL_30B an) wird vom Airbag-SG, wenn der Gurtschloss-Schalter verbaut ist, der Status \"Signal ungültig\" ausgegeben. Dies darf über die Zeitspanne von 5 Sekunden ab Systemstart zu keinem Fehler führen." 1 "Beim Systemstart (KL_30B an) wird vom Airbag-SG, wenn der Gurtschloss-Schalter verbaut ist, der Status \"Signal ungültig\" ausgegeben. Dies darf über die Zeitspanne von 5 Sekunden ab Systemstart zu keinem Fehler führen." 2 "Gurtschloss-Schalter ist im Fahrzeug nicht verbaut." 3 "Startwert/im Fehlerfall";
VAL_ 1200 CTR_12V_BN_FACT_ENERG_AVAI 253 "SIGNALTAG_FCTIF_NOT_AVAILABLE" 254 "SIGNALTAG_FCT_ERROR" 255 "Sendefunktion nicht in Betrieb";
VAL_ 1200 CTR_12V_BN_FACT_PWR_AVAI 253 "SIGNALTAG_FCTIF_NOT_AVAILABLE" 254 "SIGNALTAG_FCT_ERROR" 255 "Sendefunktion nicht in Betrieb";
VAL_ 1200 CTR_ENERG_COSP_VIRT_BT 0 "Virtuelle Batterie ist nicht entladen bzw. nicht aktiv" 1 "Virtuelle Batterie entladen, Anforderung zum Beenden von Wohnen" 2 "Virtuelle Batterie ist in Kürze entladen, Abschaltung ankündigen" 15 "Signal ungültig";
VAL_ 1200 CTR_BN_FACT_ENERG_AVAI 253 "SIGNALTAG_FCTIF_NOT_AVAILABLE" 254 "SIGNALTAG_FCT_ERROR" 255 "Sendefunktion nicht in Betrieb";
VAL_ 1200 CTR_BN_FACT_PWR_AVAI 253 "SIGNALTAG_FCTIF_NOT_AVAILABLE" 254 "SIGNALTAG_FCT_ERROR" 255 "Sendefunktion nicht in Betrieb";
VAL_ 1200 SOC_THO_VIRT_BT 253 "SIGNALTAG_FCTIF_NOT_AVAILABLE" 254 "SIGNALTAG_FCT_ERROR" 255 "Sendefunktion nicht in Betrieb";
VAL_ 834 ST_PO_CABRF_RETRF 0 "Faltdach ist vollständig geschlossen und mech. verriegelt" 1 "Faltdach ist zwischen offen und geschlossen" 2 "Faltdach ist vollständig geöffnet und mech. verriegelt" 3 "Position infolge manueller Bedienung nicht  bekannt" 5 "Dach ist vollständig geschlossen" 6 "Dach ist vollständig geöffnet" 7 "Diese Codierung darf ab BN2020 nicht verwendet werden, da sie vom ABK wegen RüKo zu BN2000 als \"Don´t care\" interpretiert wird." 8 "Dach manuell geschlossen und verriegelt infolge Störung Antrieb" 15 "Signal ungültig";
VAL_ 834 ST_OP_CABRF 0 "keine Bedienung" 1 "öffnen" 2 "schließen" 3 "Beladeposition anfahren" 4 "Beladeposition verlassen" 15 "Signal ungültig";
VAL_ 834 ST_SRC_OP_CABRF 0 "Keine Bedienung" 1 "Bedienschalter öffnen" 2 "Bedienschalter schließen" 4 "Betätigung Türschloss mechanisch mit Schlüssel außen am Fahrzeug" 8 "Nur bei Comfort Access: Funkbetätigung durch ID-Geber" 16 "Nicht bei Comfort Access: Funkbetätigung durch Fernbedienung" 32 "Gilt nur ab SP2011: Betätigung Beladehilfstaster \"anheben\"" 64 "Gilt nur ab SP2011: Betätigung Beladehilfstaster \"absenken\"" 128 "Gilt nur ab SP2011: nur bei Comfort Access: Funkbetätigung der Beladehilfe durch ID-Geber" 253 "SIGNALTAG_FCTIF_NOT_AVAILABLE" 254 "SIGNALTAG_FCT_ERROR" 255 "Sendefunktion nicht in Betrieb";
VAL_ 834 ST_ACTI_CABRF 0 "Keine Ansteuerung" 1 "Motor im Windlauf zur mech. Ent- oder Verriegelung des Dachs aktiv" 2 "Dachhydraulik aktiv" 4 "Klappenhydraulik aktiv" 8 "Gilt nur ab SP2011: Motor zur Umschaltung zwischen Beladehilfsfunktion und Verdeckfunktion oder Motor für Verdeckantrieb links aktiv" 16 "Gilt nur ab SP2011: Motor zur Umschaltung zwischen Beladehilfsfunktion und Verdeckfunktion oder Motor für Verdeckantrieb rechts aktiv" 253 "SIGNALTAG_FCTIF_NOT_AVAILABLE" 254 "SIGNALTAG_FCT_ERROR" 255 "Sendefunktion nicht in Betrieb";
VAL_ 834 ST_RLS_BTL 0 "Keine Anforderung an Heckklappen-Steuerung" 1 "Bei dieser Codierung darf die Heckklappe geöffnet werden." 2 "Bei dieser Codierung darf die Heckklappe nicht geöffnet werden" 3 "Im Fehlerfall erfolgt aus Sicherheitsgründen auch die Freigabe zum öffnen der Heckklappe";
VAL_ 1079 CAM_CAL_OFFS_HRZTL 253 "Vorhalt für Signal-Tag \"nicht verfügbar\"" 254 "Vorhalt für Signal-Tag \"Fehler\"" 255 "Signal_unbefuellt";
VAL_ 1079 CAM_CAL_OFFS_VE 253 "Vorhalt für Signal-Tag \"nicht verfügbar\"" 254 "Vorhalt für Signal-Tag \"Fehler\"" 255 "Signal_unbefuellt";
VAL_ 1079 ST_CAM_CAL 0 "Autoaim not OK" 1 "Autoaim OK" 3 "Signal ungültig";
VAL_ 50 StatusValvetrain 0 "alle Zylinder mit Ladungswechsel" 1 "Zielzustand: kein Ladungswechsel" 2 "Zielzustand: Ladungswechsel nur auf der Hälfte der Zylinder" 3 "Sendefunktion nicht in Betrieb";
VAL_ 50 StatusElectricMode 0 "ElectricMode_not_active" 1 "ElectricMode_active" 3 "Sendefunktion nicht in Betrieb";
VAL_ 50 ST_CENG_DRV 0 "Motorstillstand anhand interner Bedingungen erkannt (z.B. Kurbelwellendrehzahl < Schwelle für bestimmte Zeit)" 1 "Startroutinen aktiv, Motor in Vorsteuerung" 2 "Motor im geregelten Betrieb, Motorlauf ohne Startsystemeingriff gewährleistet" 3 "Anforderung zum Motorabstellen (z.B. über MSA-Anforderung, Anforderung Fahrbereitschaft beenden, etc.)" 13 "SIGNALTAG_FCTIF_NOT_AVAILABLE" 14 "Hinweis: Reserviert für funktionale Kennung Signal-Tag." 15 "Sendefunktion nicht in Betrieb";
VAL_ 50 ST_UDP 0 "kein Spannungseinbruch angekündigt oder aktiv" 1 "Spannungseinbruch bis Schwelle 1 aktiv (z.B. Ankündigung vor Einbruch, bei Ansteuerung Startsystem, Nachlauf nach Abwurf Startsystem bis Normalisierung des BN-Niveaus) Siehe GS95024-2-1 (Kap. 4.11.2.2) Warmstart" 2 "Spannungseinbruch bis Schwelle 2 aktiv (z.B. Ankündigung vor Einbruch, bei Ansteuerung Startsystem, Nachlauf nach Abwurf Startsystem bis Normalisierung des BN-Niveaus)  Siehe GS95024-2-1 (Kap. 4.11.2.1) Kaltstart" 13 "SIGNALTAG_FCTIF_NOT_AVAILABLE" 14 "Hinweis: Reserviert für funktionale Kennung Signal-Tag." 15 "Sendefunktion nicht in Betrieb";
VAL_ 50 ST_ENERG_SUPY 0 "Kein Spannungseinbruch" 1 "Auf Versorgungszweig 1 ist bei MSA2.3 der Starter. Bei MSA2.5 kann beim Kaltstart Versorgungszweig 1 und Versorgungszweig 2 über ein Relais verbunden werden." 2 "Auf Versorgungszweig 2 ist bei MSA2.5 der Starter. Bei den Hybriden ist die Zustarteinrichtung ebenfalls auf Versorgungszweig 2." 4 "Spannungsversorgung 48 Volt" 253 "Hinweis: Reserviert für funktionale Kennung Signal-Tag" 254 "Hinweis: Reserviert für funktionale Kennung Signal-Tag" 255 "Sendefunktion nicht in Betrieb";
VAL_ 50 ST_MOT_DRV 0 "Keine Traktions-E-Maschine verfügbar, oder Traktions-E-Maschine(n) nicht bereit, oder elektrische Fahrbereitschaft nicht zulässig." 1 "Hochvoltsystem ist aktiv, Traktions-E-Maschine(n) bereit und elektrische Fahrbereitschaft zulässig." 3 "Signal ungültig";
VAL_ 50 ST_ANO_MSA_ENG_STOP 0 "kein MSA-Motorstopp angekündigt oder aktiv" 1 "MSA-Motorstopp angekündigt oder aktiv in Durchführung" 3 "Signal ungültig";
VAL_ 50 TR_HHASS_MSA 0 "Keine Retry Anforderung um das Fahrzeug zu halten" 1 "Selbstlaufgrenze unterschritten" 2 "Selbstlaufgrenze wird bald unterschritten" 4 "Retry Anforderung Fahrzeug halten" 13 "SIGNALTAG_FCTIF_NOT_AVAILABLE" 14 "SIGNALTAG_FCT_ERROR" 15 "Sendefunktion nicht in Betrieb";
VAL_ 50 CTR_LED_PUBU_MSA 0 "ausschalten" 1 "einschalten" 3 "Signal ungültig";
VAL_ 50 PowertrainConfigurationAccelerat 0 "Flache_FP_Progression_mit_Plateau" 1 "Sehr_komfortable_FP_Progression" 2 "Komfortable_FP_Progression" 3 "Sportliche_FP_Progression" 4 "Extrem_Sportliche_FP_Progression" 5 "SIGNALTAG_FCTIF_NOT_AVAILABLE" 6 "SIGNALTAG_FCT_ERROR" 7 "Sendefunktion nicht in Betrieb";
VAL_ 50 PowertrainConfigurationLoadShock 0 "Moderater Momentenaufbaugradient" 1 "Hohe_Gradientenbegrenzung_bei_Lastschlag" 2 "Mittlere_Gradientenbegrenzung_bei_Lastschlag" 3 "Geringe_Gradientenbegrenzung_bei_Lastschlag" 4 "Dynamischer/ schneller Momentenaufbaugradient" 5 "SIGNALTAG_FCTIF_NOT_AVAILABLE" 6 "SIGNALTAG_FCT_ERROR" 7 "Sendefunktion nicht in Betrieb";
VAL_ 50 PowertrainConfigurationDashpot 0 "Moderater Momentenabbaugradient" 1 "Hohe_Gradientenbegrenzung_bei_Dashpot" 2 "Mittlere_Gradientenbegrenzung_bei_Dashpot" 3 "Geringe_Gradientenbegrenzung_bei_Dashpot" 4 "Dynamischer/ schneller Momentenabbaugradient" 5 "SIGNALTAG_FCTIF_NOT_AVAILABLE" 6 "SIGNALTAG_FCT_ERROR" 7 "Sendefunktion nicht in Betrieb";
VAL_ 948 ST_CHGWR_PLGD 0 "Kein Ladekabel erkannt." 1 "Ladekabel ist gesteckt, Proximity-Signal ist gültig." 2 "Fehler" 3 "Signal ungültig";
VAL_ 948 ST_LOKG_CHGP 0 "Ladestecker ist nicht verriegelt." 1 "Ladestecker ist verriegelt." 2 "Fehler" 3 "Signal ungültig";
VAL_ 948 ST_PIL 0 "Keine Verbindung zur EVSE oder EVSE inaktiv. Entspricht Zustand A1, A2, E oder F entspr. IEC 61851-1 Ed. 3." 1 "Pilotsignal mit Tastverhältnis 10% - 96% wurde erkannt. Fzg. meldet keine Ladebereitschaft an EVSE. Entspricht Zustand B2 entspr. IEC 61851-1 Ed. 3." 2 "Pilotsignal mit Tastverhältnis 10% - 96% wurde erkannt. Fzg. meldet Ladebereitschaft an EVSE. Entspricht Zustand C2 entspr. IEC 61851-1 Ed." 3 "Fehler des Pilotsignals (z.B. falsche Frequenz)" 4 "Pilotsignal mit Tastverhältnis 5% wurde erkannt. Fzg. meldet keine Ladebereitschaft an EVSE. Entspricht Zustand B2 entspr. IEC 61851-1 Ed. 3." 5 "Pilotsignal mit Tastverhältnis 5% wurde erkannt. Fzg. meldet Ladebereitschaft an EVSE. Entspricht Zustand C2 entspr. IEC 61851-1 Ed. 3." 6 "Pilotsignal mit statischem Spannungspegel von 6 V oder 9 V erkannt. Entspricht Zustand B1 oder C1 entspr. IEC 61851-1 Ed. 3." 7 "Signal ungültig";
VAL_ 948 ST_DC_CHGWR_PLGD 0 "DC-Ladestecker nicht gesteckt" 1 "DC-Ladestecker gesteckt" 2 "Fehler" 3 "Signal ungültig";
VAL_ 948 DisplayPositionPlug 0 "Kein Stecker gesteckt" 1 "Vorne links" 2 "Hinten rechts" 5 "SIGNALTAG_FCTIF_NOT_AVAILABLE" 6 "SIGNALTAG_FCT_ERROR" 7 "Sendefunktion nicht in Betrieb";
VAL_ 948 CHGNG_TYP_IMME 0 "Kein Ladeverfahren" 1 "AC-Laden mit Typ1-Stecker" 2 "AC-Laden mit Typ2-Stecker" 3 "DC-Laden nach CHAdeMO-Protokoll" 4 "DC-Laden mit DC-Pins über Typ1-Combo-Dose" 5 "AC-Laden-CN" 6 "AC-Laden über Typ1-Combo-Dose" 7 "AC-Laden über Typ2-Combo (Kern)-Ladedose" 8 "DC-Laden mit Kernpins über Typ2-Combo (Kern)-Ladedose" 9 "DC-Laden mit DC-Pins über Typ2-Combo (Kern)-Ladedose" 10 "DC_Laden_mit_DC_Pins_nach_GB_T" 11 "DC_Laden_nach_ChaoJi_Protokoll" 253 "Schnittstelle ist nicht verfügbar" 254 "SIGNALTAG_FCT_ERROR" 255 "Signal wird von Funktion nicht bedient.";
VAL_ 581 ST_RCOG_CHGSTN_IDT_CHGNG 0 "Keine_Aenderung" 1 "Keine_Ladestation_in_Reichweite" 2 "mind. eine" 3 "mind. eine" 4 "Jeweils mind. eine" 5 "Suche_fehlerhaft" 15 "Sendefunktion nicht in Betrieb";
VAL_ 581 ST_CONN_CHGSTN_IDT_CHGNG 0 "Keine_Aenderung" 1 "Verbindungsaufbau" 2 "Schluessel_benoetigt" 3 "Verbunden" 4 "Verbindung_Fehlgeschlagen" 5 "Verbindung_Fehlgeschlagen_Ladestation_ausser_Reichweite" 6 "Keine_Verbindung" 15 "Sendefunktion nicht in Betrieb";
VAL_ 588 ST_CT_RSCR_LCL 0 "Heckscheibe ist geschlossen" 1 "Heckscheibe ist offen" 2 "Kurzschluss oder offene Leitung" 3 "Signal ungültig";
SIG_GROUP_ 258 e2eGrp_RQ_WBK_ACOU 1 : CRC_RQ_WBK_ACOU ALIV_RQ_WBK_ACOU CHL_RQ_WBK_ACOU RQ_SOU RQ_WBK_ACOU_dummy_20_31 RQ_WBK_ACOU_dummy_32_63;
SIG_GROUP_ 261 e2eGrp_RQ_WBK_DISP 1 : CRC_RQ_WBK_DISP ALIV_RQ_WBK_DISP CHL_RQ_WBK_DISP RQ_DISP_SYM RQ_SYMAB RQ_WBK_DISP_dummy_28_31 RQ_WBK_DISP_dummy_32_63;
SIG_GROUP_ 464 e2eGrp_SAFG_PT 1 : CRC_SAFG_PT ALIV_SAFG_PT SAFG_PT_dummy_12_15 SAFG_PT_dummy_16_47 TORQ_MIN_LAY_2_MOT_1 TORQ_MAX_LAY_2_MOT_1;
SIG_GROUP_ 482 signalGrp_SECU_FAHRGESTELLNUMMER 1 : STU_8_BYTE;
SIG_GROUP_ 740 e2eGrp_STAT_ANHAENGER 1 : ST_TRAI ST_DI_DF_TRAI ST_SYNCN_HAZWCL_TRAI STAT_ANHAENGER_dummy_7_7 ST_RFLI_DF_TRAI ST_PO_AHV StatusBikeCarrier STAT_ANHAENGER_dummy_15_15 DISP_ST_TRAI STAT_ANHAENGER_dummy_18_47 ALIV_ST_TRAI STAT_ANHAENGER_dummy_52_55 CRC_ST_TRAI;
SIG_GROUP_ 481 e2eGrp_STAT_DS_VRFD 1 : CRC_ST_DSW_VRFD ALIV_ST_DSW_VRFD STAT_DS_VRFD_dummy_12_15 ST_DSW_DRD_VRFD ST_DSW_PSD_VRFD ST_DSW_PSDR_VRFD ST_DSW_DVDR_VRFD STAT_DS_VRFD_dummy_24_47;
SIG_GROUP_ 779 e2eGrp_STAT_ENG_STA_AUTO 1 : CRC_ST_ENG_STA_AUTO ALIV_ST_ENG_STA_AUTO RQ_MSA_ENG_STA_1 RQ_MSA_ENG_STA_2 ST_AVL_PENG_CENG_ENGMG ST_FN_MSA SPEC_TYP_ENGSTA_PRM ST_SHFT_MSA_ENGSTP PSBTY_MSA_ENG_STOP_STA ST_TAR_CENG SPEC_TYP_ENGSTA ST_RPM_CLCTR_MOT ST_TAR_PENG_CENG ST_AVAI_SAIL_DME RQ_SLIP_K0 VARI_TYP_ENGSTA STAT_ENG_STA_AUTO_dummy_58_59 ST_CON_MSA;
SIG_GROUP_ 770 e2eGrp_STEA_FTAX_EFFV 1 : CRC_STEA_FTAX_EFFV ALIV_STEA_FTAX_EFFV ST_ECU_STEA_FTAX_EFFV STEA_FTAX_EFFV QU_STEA_FTAX_EFFV ST_CON_STEA STEA_FTAX_EFFV_ERR_AMP;
SIG_GROUP_ 663 e2eGrp_ST_BLT_CT_SOCCU 1 : CRC_ST_BLT_CT_SOCCU ALIV_COU_ST_BLT_CT_SOCCU ST_ERR_SEAT_MT_DR ST_BLT_CT_SOCCU_dummy_15_15 ST_BLTB_SW_DR ST_SEAT_OCCU_DR ST_SEAT_OCCU_3_LH_TIR_RS ST_BLTB_SW_PS ST_SEAT_OCCU_PS ST_SEAT_OCCU_3_MID_TIR_RS ST_BLTB_SW_RLH ST_SEAT_OCCU_RLH ST_SEAT_OCCU_3_RH_TIR_RS ST_BLTB_SW_RRH ST_SEAT_OCCU_RRH ST_SEAT_OCCU_RM ST_BLTB_SW_RM ST_BLTB_SW_3_LH_TIR_RS ST_BLTB_SW_3_RH_TIR_RS ST_BLTB_SW_3_MID_TIR_RS;
SIG_GROUP_ 834 e2eGrp_ST_CABRF 1 : ALIV_CABRF ST_PO_CABRF ST_PO_CABRF_RETRF ST_OP_CABRF ST_SRC_OP_CABRF ST_ACTI_CABRF ST_RLS_BTL ST_CABRF_dummy_34_55 CRC_ST_CABRF;
SIG_GROUP_ 50 e2eGrp_ST_CENG 1 : CRC_ST_CENG ALIV_ST_CENG StatusValvetrain StatusElectricMode ST_CENG_DRV ST_UDP ST_ENERG_SUPY ST_MOT_DRV ST_ANO_MSA_ENG_STOP TR_HHASS_MSA CTR_LED_PUBU_MSA PowertrainConfigurationAccelerat PowertrainConfigurationLoadShock PowertrainConfigurationDashpot PowertrainConfigurationGearbox ST_CENG_dummy_56_63;
